VERSION "HINBNNNYYNNNYYNNNNNNNNNNNNYNNNYYYNNYNNNNNN/4//%%/4/'%**4NNN///"

NS_ :

BS_:

BU_: VirtualNMTMaster TTGateway_ID2 Master_ID1 SupportFront_ID12 LadderDrive_ID11 SupportRear_ID13 ControlPanel_ID10

BO_ 1537 CSDO_001: 8 Vector__XXX
 SG_ RequestNMT_1F82_5E m94 : 32|8@1+ (1,0) [0|255] ""  Master_ID1
 SG_ RequestNMT_1F82_5D m93 : 32|8@1+ (1,0) [0|255] ""  Master_ID1
 SG_ RequestNMT_1F82_5C m92 : 32|8@1+ (1,0) [0|255] ""  Master_ID1
 SG_ RequestNMT_1F82_5B m91 : 32|8@1+ (1,0) [0|255] ""  Master_ID1
 SG_ RequestNMT_1F82_5A m90 : 32|8@1+ (1,0) [0|255] ""  Master_ID1
 SG_ RequestNMT_1F82_59 m89 : 32|8@1+ (1,0) [0|255] ""  Master_ID1
 SG_ RequestNMT_1F82_58 m88 : 32|8@1+ (1,0) [0|255] ""  Master_ID1
 SG_ RequestNMT_1F82_57 m87 : 32|8@1+ (1,0) [0|255] ""  Master_ID1
 SG_ RequestNMT_1F82_56 m86 : 32|8@1+ (1,0) [0|255] ""  Master_ID1
 SG_ RequestNMT_1F82_55 m85 : 32|8@1+ (1,0) [0|255] ""  Master_ID1
 SG_ RequestNMT_1F82_54 m84 : 32|8@1+ (1,0) [0|255] ""  Master_ID1
 SG_ RequestNMT_1F82_53 m83 : 32|8@1+ (1,0) [0|255] ""  Master_ID1
 SG_ RequestNMT_1F82_52 m82 : 32|8@1+ (1,0) [0|255] ""  Master_ID1
 SG_ RequestNMT_1F82_51 m81 : 32|8@1+ (1,0) [0|255] ""  Master_ID1
 SG_ RequestNMT_1F82_50 m80 : 32|8@1+ (1,0) [0|255] ""  Master_ID1
 SG_ RequestNMT_1F82_4F m79 : 32|8@1+ (1,0) [0|255] ""  Master_ID1
 SG_ RequestNMT_1F82_4E m78 : 32|8@1+ (1,0) [0|255] ""  Master_ID1
 SG_ RequestNMT_1F82_4D m77 : 32|8@1+ (1,0) [0|255] ""  Master_ID1
 SG_ RequestNMT_1F82_4C m76 : 32|8@1+ (1,0) [0|255] ""  Master_ID1
 SG_ RequestNMT_1F82_4B m75 : 32|8@1+ (1,0) [0|255] ""  Master_ID1
 SG_ RequestNMT_1F82_4A m74 : 32|8@1+ (1,0) [0|255] ""  Master_ID1
 SG_ RequestNMT_1F82_49 m73 : 32|8@1+ (1,0) [0|255] ""  Master_ID1
 SG_ RequestNMT_1F82_48 m72 : 32|8@1+ (1,0) [0|255] ""  Master_ID1
 SG_ RequestNMT_1F82_47 m71 : 32|8@1+ (1,0) [0|255] ""  Master_ID1
 SG_ RequestNMT_1F82_46 m70 : 32|8@1+ (1,0) [0|255] ""  Master_ID1
 SG_ RequestNMT_1F82_45 m69 : 32|8@1+ (1,0) [0|255] ""  Master_ID1
 SG_ RequestNMT_1F82_44 m68 : 32|8@1+ (1,0) [0|255] ""  Master_ID1
 SG_ RequestNMT_1F82_43 m67 : 32|8@1+ (1,0) [0|255] ""  Master_ID1
 SG_ RequestNMT_1F82_42 m66 : 32|8@1+ (1,0) [0|255] ""  Master_ID1
 SG_ RequestNMT_1F82_41 m65 : 32|8@1+ (1,0) [0|255] ""  Master_ID1
 SG_ RequestNMT_1F82_40 m64 : 32|8@1+ (1,0) [0|255] ""  Master_ID1
 SG_ RequestNMT_1F82_3F m63 : 32|8@1+ (1,0) [0|255] ""  Master_ID1
 SG_ RequestNMT_1F82_3E m62 : 32|8@1+ (1,0) [0|255] ""  Master_ID1
 SG_ RequestNMT_1F82_3D m61 : 32|8@1+ (1,0) [0|255] ""  Master_ID1
 SG_ RequestNMT_1F82_3C m60 : 32|8@1+ (1,0) [0|255] ""  Master_ID1
 SG_ RequestNMT_1F82_3B m59 : 32|8@1+ (1,0) [0|255] ""  Master_ID1
 SG_ RequestNMT_1F82_3A m58 : 32|8@1+ (1,0) [0|255] ""  Master_ID1
 SG_ RequestNMT_1F82_39 m57 : 32|8@1+ (1,0) [0|255] ""  Master_ID1
 SG_ RequestNMT_1F82_38 m56 : 32|8@1+ (1,0) [0|255] ""  Master_ID1
 SG_ RequestNMT_1F82_37 m55 : 32|8@1+ (1,0) [0|255] ""  Master_ID1
 SG_ RequestNMT_1F82_36 m54 : 32|8@1+ (1,0) [0|255] ""  Master_ID1
 SG_ RequestNMT_1F82_35 m53 : 32|8@1+ (1,0) [0|255] ""  Master_ID1
 SG_ RequestNMT_1F82_34 m52 : 32|8@1+ (1,0) [0|255] ""  Master_ID1
 SG_ RequestNMT_1F82_33 m51 : 32|8@1+ (1,0) [0|255] ""  Master_ID1
 SG_ RequestNMT_1F82_32 m50 : 32|8@1+ (1,0) [0|255] ""  Master_ID1
 SG_ RequestNMT_1F82_31 m49 : 32|8@1+ (1,0) [0|255] ""  Master_ID1
 SG_ RequestNMT_1F82_30 m48 : 32|8@1+ (1,0) [0|255] ""  Master_ID1
 SG_ RequestNMT_1F82_2F m47 : 32|8@1+ (1,0) [0|255] ""  Master_ID1
 SG_ RequestNMT_1F82_2E m46 : 32|8@1+ (1,0) [0|255] ""  Master_ID1
 SG_ RequestNMT_1F82_2D m45 : 32|8@1+ (1,0) [0|255] ""  Master_ID1
 SG_ RequestNMT_1F82_2C m44 : 32|8@1+ (1,0) [0|255] ""  Master_ID1
 SG_ RequestNMT_1F82_2B m43 : 32|8@1+ (1,0) [0|255] ""  Master_ID1
 SG_ RequestNMT_1F82_2A m42 : 32|8@1+ (1,0) [0|255] ""  Master_ID1
 SG_ RequestNMT_1F82_29 m41 : 32|8@1+ (1,0) [0|255] ""  Master_ID1
 SG_ RequestNMT_1F82_28 m40 : 32|8@1+ (1,0) [0|255] ""  Master_ID1
 SG_ RequestNMT_1F82_27 m39 : 32|8@1+ (1,0) [0|255] ""  Master_ID1
 SG_ RequestNMT_1F82_26 m38 : 32|8@1+ (1,0) [0|255] ""  Master_ID1
 SG_ RequestNMT_1F82_25 m37 : 32|8@1+ (1,0) [0|255] ""  Master_ID1
 SG_ RequestNMT_1F82_24 m36 : 32|8@1+ (1,0) [0|255] ""  Master_ID1
 SG_ RequestNMT_1F82_23 m35 : 32|8@1+ (1,0) [0|255] ""  Master_ID1
 SG_ RequestNMT_1F82_22 m34 : 32|8@1+ (1,0) [0|255] ""  Master_ID1
 SG_ RequestNMT_1F82_21 m33 : 32|8@1+ (1,0) [0|255] ""  Master_ID1
 SG_ RequestNMT_1F82_20 m32 : 32|8@1+ (1,0) [0|255] ""  Master_ID1
 SG_ RequestNMT_1F82_1F m31 : 32|8@1+ (1,0) [0|255] ""  Master_ID1
 SG_ RequestNMT_1F82_1E m30 : 32|8@1+ (1,0) [0|255] ""  Master_ID1
 SG_ RequestNMT_1F82_1D m29 : 32|8@1+ (1,0) [0|255] ""  Master_ID1
 SG_ RequestNMT_1F82_1C m28 : 32|8@1+ (1,0) [0|255] ""  Master_ID1
 SG_ RequestNMT_1F82_1B m27 : 32|8@1+ (1,0) [0|255] ""  Master_ID1
 SG_ RequestNMT_1F82_1A m26 : 32|8@1+ (1,0) [0|255] ""  Master_ID1
 SG_ RequestNMT_1F82_19 m25 : 32|8@1+ (1,0) [0|255] ""  Master_ID1
 SG_ RequestNMT_1F82_18 m24 : 32|8@1+ (1,0) [0|255] ""  Master_ID1
 SG_ RequestNMT_1F82_17 m23 : 32|8@1+ (1,0) [0|255] ""  Master_ID1
 SG_ RequestNMT_1F82_16 m22 : 32|8@1+ (1,0) [0|255] ""  Master_ID1
 SG_ RequestNMT_1F82_15 m21 : 32|8@1+ (1,0) [0|255] ""  Master_ID1
 SG_ RequestNMT_1F82_14 m20 : 32|8@1+ (1,0) [0|255] ""  Master_ID1
 SG_ RequestNMT_1F82_13 m19 : 32|8@1+ (1,0) [0|255] ""  Master_ID1
 SG_ RequestNMT_1F82_12 m18 : 32|8@1+ (1,0) [0|255] ""  Master_ID1
 SG_ RequestNMT_1F82_11 m17 : 32|8@1+ (1,0) [0|255] ""  Master_ID1
 SG_ RequestNMT_1F82_10 m16 : 32|8@1+ (1,0) [0|255] ""  Master_ID1
 SG_ RequestNMT_1F82_0F m15 : 32|8@1+ (1,0) [0|255] ""  Master_ID1
 SG_ RequestNMT_1F82_0E m14 : 32|8@1+ (1,0) [0|255] ""  Master_ID1
 SG_ RequestNMT_1F82_0D m13 : 32|8@1+ (1,0) [0|255] ""  Master_ID1
 SG_ RequestNMT_1F82_0C m12 : 32|8@1+ (1,0) [0|255] ""  Master_ID1
 SG_ RequestNMT_1F82_0B m11 : 32|8@1+ (1,0) [0|255] ""  Master_ID1
 SG_ RequestNMT_1F82_0A m10 : 32|8@1+ (1,0) [0|255] ""  Master_ID1
 SG_ RequestNMT_1F82_09 m9 : 32|8@1+ (1,0) [0|255] ""  Master_ID1
 SG_ RequestNMT_1F82_08 m8 : 32|8@1+ (1,0) [0|255] ""  Master_ID1
 SG_ RequestNMT_1F82_07 m7 : 32|8@1+ (1,0) [0|255] ""  Master_ID1
 SG_ RequestNMT_1F82_06 m6 : 32|8@1+ (1,0) [0|255] ""  Master_ID1
 SG_ RequestNMT_1F82_05 m5 : 32|8@1+ (1,0) [0|255] ""  Master_ID1
 SG_ RequestNMT_1F82_04 m4 : 32|8@1+ (1,0) [0|255] ""  Master_ID1
 SG_ RequestNMT_1F82_03 m3 : 32|8@1+ (1,0) [0|255] ""  Master_ID1
 SG_ RequestNMT_1F82_02 m2 : 32|8@1+ (1,0) [0|255] ""  Master_ID1
 SG_ RequestNMT_1F82_01 m1 : 32|8@1+ (1,0) [0|255] ""  Master_ID1
 SG_ Highest_sub_index_supported_0013 m0 : 32|8@1+ (1,0) [0|255] ""  Master_ID1
 SG_ SubIndex_1F82 m8066M : 24|8@1+ (1,0) [0|128] ""  Master_ID1
 SG_ SlaveAssignment_1F81_7F m127 : 32|32@1+ (1,0) [0|4294967295] ""  Master_ID1
 SG_ SlaveAssignment_1F81_7E m126 : 32|32@1+ (1,0) [0|4294967295] ""  Master_ID1
 SG_ SlaveAssignment_1F81_7D m125 : 32|32@1+ (1,0) [0|4294967295] ""  Master_ID1
 SG_ SlaveAssignment_1F81_7C m124 : 32|32@1+ (1,0) [0|4294967295] ""  Master_ID1
 SG_ SlaveAssignment_1F81_7B m123 : 32|32@1+ (1,0) [0|4294967295] ""  Master_ID1
 SG_ SlaveAssignment_1F81_7A m122 : 32|32@1+ (1,0) [0|4294967295] ""  Master_ID1
 SG_ SlaveAssignment_1F81_79 m121 : 32|32@1+ (1,0) [0|4294967295] ""  Master_ID1
 SG_ SlaveAssignment_1F81_78 m120 : 32|32@1+ (1,0) [0|4294967295] ""  Master_ID1
 SG_ SlaveAssignment_1F81_77 m119 : 32|32@1+ (1,0) [0|4294967295] ""  Master_ID1
 SG_ SlaveAssignment_1F81_76 m118 : 32|32@1+ (1,0) [0|4294967295] ""  Master_ID1
 SG_ SlaveAssignment_1F81_75 m117 : 32|32@1+ (1,0) [0|4294967295] ""  Master_ID1
 SG_ SlaveAssignment_1F81_74 m116 : 32|32@1+ (1,0) [0|4294967295] ""  Master_ID1
 SG_ SlaveAssignment_1F81_73 m115 : 32|32@1+ (1,0) [0|4294967295] ""  Master_ID1
 SG_ SlaveAssignment_1F81_72 m114 : 32|32@1+ (1,0) [0|4294967295] ""  Master_ID1
 SG_ SlaveAssignment_1F81_71 m113 : 32|32@1+ (1,0) [0|4294967295] ""  Master_ID1
 SG_ SlaveAssignment_1F81_70 m112 : 32|32@1+ (1,0) [0|4294967295] ""  Master_ID1
 SG_ SlaveAssignment_1F81_6F m111 : 32|32@1+ (1,0) [0|4294967295] ""  Master_ID1
 SG_ SlaveAssignment_1F81_6E m110 : 32|32@1+ (1,0) [0|4294967295] ""  Master_ID1
 SG_ SlaveAssignment_1F81_6D m109 : 32|32@1+ (1,0) [0|4294967295] ""  Master_ID1
 SG_ SlaveAssignment_1F81_6C m108 : 32|32@1+ (1,0) [0|4294967295] ""  Master_ID1
 SG_ SlaveAssignment_1F81_6B m107 : 32|32@1+ (1,0) [0|4294967295] ""  Master_ID1
 SG_ SlaveAssignment_1F81_6A m106 : 32|32@1+ (1,0) [0|4294967295] ""  Master_ID1
 SG_ SlaveAssignment_1F81_69 m105 : 32|32@1+ (1,0) [0|4294967295] ""  Master_ID1
 SG_ SlaveAssignment_1F81_68 m104 : 32|32@1+ (1,0) [0|4294967295] ""  Master_ID1
 SG_ SlaveAssignment_1F81_67 m103 : 32|32@1+ (1,0) [0|4294967295] ""  Master_ID1
 SG_ SlaveAssignment_1F81_66 m102 : 32|32@1+ (1,0) [0|4294967295] ""  Master_ID1
 SG_ SlaveAssignment_1F81_65 m101 : 32|32@1+ (1,0) [0|4294967295] ""  Master_ID1
 SG_ SlaveAssignment_1F81_64 m100 : 32|32@1+ (1,0) [0|4294967295] ""  Master_ID1
 SG_ SlaveAssignment_1F81_63 m99 : 32|32@1+ (1,0) [0|4294967295] ""  Master_ID1
 SG_ SlaveAssignment_1F81_62 m98 : 32|32@1+ (1,0) [0|4294967295] ""  Master_ID1
 SG_ SlaveAssignment_1F81_61 m97 : 32|32@1+ (1,0) [0|4294967295] ""  Master_ID1
 SG_ SlaveAssignment_1F81_60 m96 : 32|32@1+ (1,0) [0|4294967295] ""  Master_ID1
 SG_ SlaveAssignment_1F81_5F m95 : 32|32@1+ (1,0) [0|4294967295] ""  Master_ID1
 SG_ SlaveAssignment_1F81_5E m94 : 32|32@1+ (1,0) [0|4294967295] ""  Master_ID1
 SG_ SlaveAssignment_1F81_5D m93 : 32|32@1+ (1,0) [0|4294967295] ""  Master_ID1
 SG_ SlaveAssignment_1F81_5C m92 : 32|32@1+ (1,0) [0|4294967295] ""  Master_ID1
 SG_ SlaveAssignment_1F81_5B m91 : 32|32@1+ (1,0) [0|4294967295] ""  Master_ID1
 SG_ SlaveAssignment_1F81_5A m90 : 32|32@1+ (1,0) [0|4294967295] ""  Master_ID1
 SG_ SlaveAssignment_1F81_59 m89 : 32|32@1+ (1,0) [0|4294967295] ""  Master_ID1
 SG_ SlaveAssignment_1F81_58 m88 : 32|32@1+ (1,0) [0|4294967295] ""  Master_ID1
 SG_ SlaveAssignment_1F81_57 m87 : 32|32@1+ (1,0) [0|4294967295] ""  Master_ID1
 SG_ SlaveAssignment_1F81_56 m86 : 32|32@1+ (1,0) [0|4294967295] ""  Master_ID1
 SG_ SlaveAssignment_1F81_55 m85 : 32|32@1+ (1,0) [0|4294967295] ""  Master_ID1
 SG_ SlaveAssignment_1F81_54 m84 : 32|32@1+ (1,0) [0|4294967295] ""  Master_ID1
 SG_ SlaveAssignment_1F81_53 m83 : 32|32@1+ (1,0) [0|4294967295] ""  Master_ID1
 SG_ SlaveAssignment_1F81_52 m82 : 32|32@1+ (1,0) [0|4294967295] ""  Master_ID1
 SG_ SlaveAssignment_1F81_51 m81 : 32|32@1+ (1,0) [0|4294967295] ""  Master_ID1
 SG_ SlaveAssignment_1F81_50 m80 : 32|32@1+ (1,0) [0|4294967295] ""  Master_ID1
 SG_ SlaveAssignment_1F81_4F m79 : 32|32@1+ (1,0) [0|4294967295] ""  Master_ID1
 SG_ SlaveAssignment_1F81_4E m78 : 32|32@1+ (1,0) [0|4294967295] ""  Master_ID1
 SG_ SlaveAssignment_1F81_4D m77 : 32|32@1+ (1,0) [0|4294967295] ""  Master_ID1
 SG_ SlaveAssignment_1F81_4C m76 : 32|32@1+ (1,0) [0|4294967295] ""  Master_ID1
 SG_ SlaveAssignment_1F81_4B m75 : 32|32@1+ (1,0) [0|4294967295] ""  Master_ID1
 SG_ SlaveAssignment_1F81_4A m74 : 32|32@1+ (1,0) [0|4294967295] ""  Master_ID1
 SG_ SlaveAssignment_1F81_49 m73 : 32|32@1+ (1,0) [0|4294967295] ""  Master_ID1
 SG_ SlaveAssignment_1F81_48 m72 : 32|32@1+ (1,0) [0|4294967295] ""  Master_ID1
 SG_ SlaveAssignment_1F81_47 m71 : 32|32@1+ (1,0) [0|4294967295] ""  Master_ID1
 SG_ SlaveAssignment_1F81_46 m70 : 32|32@1+ (1,0) [0|4294967295] ""  Master_ID1
 SG_ SlaveAssignment_1F81_45 m69 : 32|32@1+ (1,0) [0|4294967295] ""  Master_ID1
 SG_ SlaveAssignment_1F81_44 m68 : 32|32@1+ (1,0) [0|4294967295] ""  Master_ID1
 SG_ SlaveAssignment_1F81_43 m67 : 32|32@1+ (1,0) [0|4294967295] ""  Master_ID1
 SG_ SlaveAssignment_1F81_42 m66 : 32|32@1+ (1,0) [0|4294967295] ""  Master_ID1
 SG_ SlaveAssignment_1F81_41 m65 : 32|32@1+ (1,0) [0|4294967295] ""  Master_ID1
 SG_ SlaveAssignment_1F81_40 m64 : 32|32@1+ (1,0) [0|4294967295] ""  Master_ID1
 SG_ SlaveAssignment_1F81_3F m63 : 32|32@1+ (1,0) [0|4294967295] ""  Master_ID1
 SG_ SlaveAssignment_1F81_3E m62 : 32|32@1+ (1,0) [0|4294967295] ""  Master_ID1
 SG_ SlaveAssignment_1F81_3D m61 : 32|32@1+ (1,0) [0|4294967295] ""  Master_ID1
 SG_ SlaveAssignment_1F81_3C m60 : 32|32@1+ (1,0) [0|4294967295] ""  Master_ID1
 SG_ SlaveAssignment_1F81_3B m59 : 32|32@1+ (1,0) [0|4294967295] ""  Master_ID1
 SG_ SlaveAssignment_1F81_3A m58 : 32|32@1+ (1,0) [0|4294967295] ""  Master_ID1
 SG_ SlaveAssignment_1F81_39 m57 : 32|32@1+ (1,0) [0|4294967295] ""  Master_ID1
 SG_ SlaveAssignment_1F81_38 m56 : 32|32@1+ (1,0) [0|4294967295] ""  Master_ID1
 SG_ SlaveAssignment_1F81_37 m55 : 32|32@1+ (1,0) [0|4294967295] ""  Master_ID1
 SG_ SlaveAssignment_1F81_36 m54 : 32|32@1+ (1,0) [0|4294967295] ""  Master_ID1
 SG_ SlaveAssignment_1F81_35 m53 : 32|32@1+ (1,0) [0|4294967295] ""  Master_ID1
 SG_ SlaveAssignment_1F81_34 m52 : 32|32@1+ (1,0) [0|4294967295] ""  Master_ID1
 SG_ SlaveAssignment_1F81_33 m51 : 32|32@1+ (1,0) [0|4294967295] ""  Master_ID1
 SG_ SlaveAssignment_1F81_32 m50 : 32|32@1+ (1,0) [0|4294967295] ""  Master_ID1
 SG_ SlaveAssignment_1F81_31 m49 : 32|32@1+ (1,0) [0|4294967295] ""  Master_ID1
 SG_ SlaveAssignment_1F81_30 m48 : 32|32@1+ (1,0) [0|4294967295] ""  Master_ID1
 SG_ SlaveAssignment_1F81_2F m47 : 32|32@1+ (1,0) [0|4294967295] ""  Master_ID1
 SG_ SlaveAssignment_1F81_2E m46 : 32|32@1+ (1,0) [0|4294967295] ""  Master_ID1
 SG_ SlaveAssignment_1F81_2D m45 : 32|32@1+ (1,0) [0|4294967295] ""  Master_ID1
 SG_ SlaveAssignment_1F81_2C m44 : 32|32@1+ (1,0) [0|4294967295] ""  Master_ID1
 SG_ SlaveAssignment_1F81_2B m43 : 32|32@1+ (1,0) [0|4294967295] ""  Master_ID1
 SG_ SlaveAssignment_1F81_2A m42 : 32|32@1+ (1,0) [0|4294967295] ""  Master_ID1
 SG_ SlaveAssignment_1F81_29 m41 : 32|32@1+ (1,0) [0|4294967295] ""  Master_ID1
 SG_ SlaveAssignment_1F81_28 m40 : 32|32@1+ (1,0) [0|4294967295] ""  Master_ID1
 SG_ SlaveAssignment_1F81_27 m39 : 32|32@1+ (1,0) [0|4294967295] ""  Master_ID1
 SG_ SlaveAssignment_1F81_26 m38 : 32|32@1+ (1,0) [0|4294967295] ""  Master_ID1
 SG_ SlaveAssignment_1F81_25 m37 : 32|32@1+ (1,0) [0|4294967295] ""  Master_ID1
 SG_ SlaveAssignment_1F81_24 m36 : 32|32@1+ (1,0) [0|4294967295] ""  Master_ID1
 SG_ SlaveAssignment_1F81_23 m35 : 32|32@1+ (1,0) [0|4294967295] ""  Master_ID1
 SG_ SlaveAssignment_1F81_22 m34 : 32|32@1+ (1,0) [0|4294967295] ""  Master_ID1
 SG_ SlaveAssignment_1F81_21 m33 : 32|32@1+ (1,0) [0|4294967295] ""  Master_ID1
 SG_ SlaveAssignment_1F81_20 m32 : 32|32@1+ (1,0) [0|4294967295] ""  Master_ID1
 SG_ SlaveAssignment_1F81_1F m31 : 32|32@1+ (1,0) [0|4294967295] ""  Master_ID1
 SG_ SlaveAssignment_1F81_1E m30 : 32|32@1+ (1,0) [0|4294967295] ""  Master_ID1
 SG_ SlaveAssignment_1F81_1D m29 : 32|32@1+ (1,0) [0|4294967295] ""  Master_ID1
 SG_ SlaveAssignment_1F81_1C m28 : 32|32@1+ (1,0) [0|4294967295] ""  Master_ID1
 SG_ SlaveAssignment_1F81_1B m27 : 32|32@1+ (1,0) [0|4294967295] ""  Master_ID1
 SG_ SlaveAssignment_1F81_1A m26 : 32|32@1+ (1,0) [0|4294967295] ""  Master_ID1
 SG_ SlaveAssignment_1F81_19 m25 : 32|32@1+ (1,0) [0|4294967295] ""  Master_ID1
 SG_ SlaveAssignment_1F81_18 m24 : 32|32@1+ (1,0) [0|4294967295] ""  Master_ID1
 SG_ SlaveAssignment_1F81_17 m23 : 32|32@1+ (1,0) [0|4294967295] ""  Master_ID1
 SG_ SlaveAssignment_1F81_16 m22 : 32|32@1+ (1,0) [0|4294967295] ""  Master_ID1
 SG_ SlaveAssignment_1F81_15 m21 : 32|32@1+ (1,0) [0|4294967295] ""  Master_ID1
 SG_ SlaveAssignment_1F81_14 m20 : 32|32@1+ (1,0) [0|4294967295] ""  Master_ID1
 SG_ SlaveAssignment_1F81_13 m19 : 32|32@1+ (1,0) [0|4294967295] ""  Master_ID1
 SG_ SlaveAssignment_1F81_12 m18 : 32|32@1+ (1,0) [0|4294967295] ""  Master_ID1
 SG_ SlaveAssignment_1F81_11 m17 : 32|32@1+ (1,0) [0|4294967295] ""  Master_ID1
 SG_ SlaveAssignment_1F81_10 m16 : 32|32@1+ (1,0) [0|4294967295] ""  Master_ID1
 SG_ SlaveAssignment_1F81_0F m15 : 32|32@1+ (1,0) [0|4294967295] ""  Master_ID1
 SG_ SlaveAssignment_1F81_0E m14 : 32|32@1+ (1,0) [0|4294967295] ""  Master_ID1
 SG_ SlaveAssignment_1F81_0D m13 : 32|32@1+ (1,0) [0|4294967295] ""  Master_ID1
 SG_ SlaveAssignment_1F81_0C m12 : 32|32@1+ (1,0) [0|4294967295] ""  Master_ID1
 SG_ SlaveAssignment_1F81_0B m11 : 32|32@1+ (1,0) [0|4294967295] ""  Master_ID1
 SG_ SlaveAssignment_1F81_0A m10 : 32|32@1+ (1,0) [0|4294967295] ""  Master_ID1
 SG_ SlaveAssignment_1F81_09 m9 : 32|32@1+ (1,0) [0|4294967295] ""  Master_ID1
 SG_ SlaveAssignment_1F81_08 m8 : 32|32@1+ (1,0) [0|4294967295] ""  Master_ID1
 SG_ SlaveAssignment_1F81_07 m7 : 32|32@1+ (1,0) [0|4294967295] ""  Master_ID1
 SG_ SlaveAssignment_1F81_06 m6 : 32|32@1+ (1,0) [0|4294967295] ""  Master_ID1
 SG_ SlaveAssignment_1F81_05 m5 : 32|32@1+ (1,0) [0|4294967295] ""  Master_ID1
 SG_ SlaveAssignment_1F81_04 m4 : 32|32@1+ (1,0) [0|4294967295] ""  Master_ID1
 SG_ SlaveAssignment_1F81_03 m3 : 32|32@1+ (1,0) [0|4294967295] ""  Master_ID1
 SG_ SlaveAssignment_1F81_02 m2 : 32|32@1+ (1,0) [0|4294967295] ""  Master_ID1
 SG_ SlaveAssignment_1F81_01 m1 : 32|32@1+ (1,0) [0|4294967295] ""  Master_ID1
 SG_ NrOfObjects_1F81_00 m0 : 32|8@1+ (1,0) [0|255] ""  Master_ID1
 SG_ SubIndex_1F81 m8065M : 24|8@1+ (1,0) [0|127] ""  Master_ID1
 SG_ NMTStartup_1F80 m0 : 32|32@1+ (1,0) [0|4294967295] ""  Master_ID1
 SG_ SubIndex_1F80 m8064M : 24|8@1+ (1,0) [0|0] ""  Master_ID1
 SG_ Configure_Slave_1F25_80 m128 : 32|32@1+ (1,0) [0|4294967295] ""  Master_ID1
 SG_ Configure_Slave_1F25_7F m127 : 32|32@1+ (1,0) [0|4294967295] ""  Master_ID1
 SG_ Configure_Slave_1F25_7E m126 : 32|32@1+ (1,0) [0|4294967295] ""  Master_ID1
 SG_ Configure_Slave_1F25_7D m125 : 32|32@1+ (1,0) [0|4294967295] ""  Master_ID1
 SG_ Configure_Slave_1F25_7C m124 : 32|32@1+ (1,0) [0|4294967295] ""  Master_ID1
 SG_ Configure_Slave_1F25_7B m123 : 32|32@1+ (1,0) [0|4294967295] ""  Master_ID1
 SG_ Configure_Slave_1F25_7A m122 : 32|32@1+ (1,0) [0|4294967295] ""  Master_ID1
 SG_ Configure_Slave_1F25_79 m121 : 32|32@1+ (1,0) [0|4294967295] ""  Master_ID1
 SG_ Configure_Slave_1F25_78 m120 : 32|32@1+ (1,0) [0|4294967295] ""  Master_ID1
 SG_ Configure_Slave_1F25_77 m119 : 32|32@1+ (1,0) [0|4294967295] ""  Master_ID1
 SG_ Configure_Slave_1F25_76 m118 : 32|32@1+ (1,0) [0|4294967295] ""  Master_ID1
 SG_ Configure_Slave_1F25_75 m117 : 32|32@1+ (1,0) [0|4294967295] ""  Master_ID1
 SG_ Configure_Slave_1F25_74 m116 : 32|32@1+ (1,0) [0|4294967295] ""  Master_ID1
 SG_ Configure_Slave_1F25_73 m115 : 32|32@1+ (1,0) [0|4294967295] ""  Master_ID1
 SG_ Configure_Slave_1F25_72 m114 : 32|32@1+ (1,0) [0|4294967295] ""  Master_ID1
 SG_ Configure_Slave_1F25_71 m113 : 32|32@1+ (1,0) [0|4294967295] ""  Master_ID1
 SG_ Configure_Slave_1F25_70 m112 : 32|32@1+ (1,0) [0|4294967295] ""  Master_ID1
 SG_ Configure_Slave_1F25_6F m111 : 32|32@1+ (1,0) [0|4294967295] ""  Master_ID1
 SG_ Configure_Slave_1F25_6E m110 : 32|32@1+ (1,0) [0|4294967295] ""  Master_ID1
 SG_ Configure_Slave_1F25_6D m109 : 32|32@1+ (1,0) [0|4294967295] ""  Master_ID1
 SG_ Configure_Slave_1F25_6C m108 : 32|32@1+ (1,0) [0|4294967295] ""  Master_ID1
 SG_ Configure_Slave_1F25_6B m107 : 32|32@1+ (1,0) [0|4294967295] ""  Master_ID1
 SG_ Configure_Slave_1F25_6A m106 : 32|32@1+ (1,0) [0|4294967295] ""  Master_ID1
 SG_ Configure_Slave_1F25_69 m105 : 32|32@1+ (1,0) [0|4294967295] ""  Master_ID1
 SG_ Configure_Slave_1F25_68 m104 : 32|32@1+ (1,0) [0|4294967295] ""  Master_ID1
 SG_ Configure_Slave_1F25_67 m103 : 32|32@1+ (1,0) [0|4294967295] ""  Master_ID1
 SG_ Configure_Slave_1F25_66 m102 : 32|32@1+ (1,0) [0|4294967295] ""  Master_ID1
 SG_ Configure_Slave_1F25_65 m101 : 32|32@1+ (1,0) [0|4294967295] ""  Master_ID1
 SG_ Configure_Slave_1F25_64 m100 : 32|32@1+ (1,0) [0|4294967295] ""  Master_ID1
 SG_ Configure_Slave_1F25_63 m99 : 32|32@1+ (1,0) [0|4294967295] ""  Master_ID1
 SG_ Configure_Slave_1F25_62 m98 : 32|32@1+ (1,0) [0|4294967295] ""  Master_ID1
 SG_ Configure_Slave_1F25_61 m97 : 32|32@1+ (1,0) [0|4294967295] ""  Master_ID1
 SG_ Configure_Slave_1F25_60 m96 : 32|32@1+ (1,0) [0|4294967295] ""  Master_ID1
 SG_ Configure_Slave_1F25_5F m95 : 32|32@1+ (1,0) [0|4294967295] ""  Master_ID1
 SG_ Configure_Slave_1F25_5E m94 : 32|32@1+ (1,0) [0|4294967295] ""  Master_ID1
 SG_ Configure_Slave_1F25_5D m93 : 32|32@1+ (1,0) [0|4294967295] ""  Master_ID1
 SG_ Configure_Slave_1F25_5C m92 : 32|32@1+ (1,0) [0|4294967295] ""  Master_ID1
 SG_ Configure_Slave_1F25_5B m91 : 32|32@1+ (1,0) [0|4294967295] ""  Master_ID1
 SG_ Configure_Slave_1F25_5A m90 : 32|32@1+ (1,0) [0|4294967295] ""  Master_ID1
 SG_ Configure_Slave_1F25_59 m89 : 32|32@1+ (1,0) [0|4294967295] ""  Master_ID1
 SG_ Configure_Slave_1F25_58 m88 : 32|32@1+ (1,0) [0|4294967295] ""  Master_ID1
 SG_ Configure_Slave_1F25_57 m87 : 32|32@1+ (1,0) [0|4294967295] ""  Master_ID1
 SG_ Configure_Slave_1F25_56 m86 : 32|32@1+ (1,0) [0|4294967295] ""  Master_ID1
 SG_ Configure_Slave_1F25_55 m85 : 32|32@1+ (1,0) [0|4294967295] ""  Master_ID1
 SG_ Configure_Slave_1F25_54 m84 : 32|32@1+ (1,0) [0|4294967295] ""  Master_ID1
 SG_ Configure_Slave_1F25_53 m83 : 32|32@1+ (1,0) [0|4294967295] ""  Master_ID1
 SG_ Configure_Slave_1F25_52 m82 : 32|32@1+ (1,0) [0|4294967295] ""  Master_ID1
 SG_ Configure_Slave_1F25_51 m81 : 32|32@1+ (1,0) [0|4294967295] ""  Master_ID1
 SG_ Configure_Slave_1F25_50 m80 : 32|32@1+ (1,0) [0|4294967295] ""  Master_ID1
 SG_ Configure_Slave_1F25_4F m79 : 32|32@1+ (1,0) [0|4294967295] ""  Master_ID1
 SG_ Configure_Slave_1F25_4E m78 : 32|32@1+ (1,0) [0|4294967295] ""  Master_ID1
 SG_ Configure_Slave_1F25_4D m77 : 32|32@1+ (1,0) [0|4294967295] ""  Master_ID1
 SG_ Configure_Slave_1F25_4C m76 : 32|32@1+ (1,0) [0|4294967295] ""  Master_ID1
 SG_ Configure_Slave_1F25_4B m75 : 32|32@1+ (1,0) [0|4294967295] ""  Master_ID1
 SG_ Configure_Slave_1F25_4A m74 : 32|32@1+ (1,0) [0|4294967295] ""  Master_ID1
 SG_ Configure_Slave_1F25_49 m73 : 32|32@1+ (1,0) [0|4294967295] ""  Master_ID1
 SG_ Configure_Slave_1F25_48 m72 : 32|32@1+ (1,0) [0|4294967295] ""  Master_ID1
 SG_ Configure_Slave_1F25_47 m71 : 32|32@1+ (1,0) [0|4294967295] ""  Master_ID1
 SG_ Configure_Slave_1F25_46 m70 : 32|32@1+ (1,0) [0|4294967295] ""  Master_ID1
 SG_ Configure_Slave_1F25_45 m69 : 32|32@1+ (1,0) [0|4294967295] ""  Master_ID1
 SG_ Configure_Slave_1F25_44 m68 : 32|32@1+ (1,0) [0|4294967295] ""  Master_ID1
 SG_ Configure_Slave_1F25_43 m67 : 32|32@1+ (1,0) [0|4294967295] ""  Master_ID1
 SG_ Configure_Slave_1F25_42 m66 : 32|32@1+ (1,0) [0|4294967295] ""  Master_ID1
 SG_ Configure_Slave_1F25_41 m65 : 32|32@1+ (1,0) [0|4294967295] ""  Master_ID1
 SG_ Configure_Slave_1F25_40 m64 : 32|32@1+ (1,0) [0|4294967295] ""  Master_ID1
 SG_ Configure_Slave_1F25_3F m63 : 32|32@1+ (1,0) [0|4294967295] ""  Master_ID1
 SG_ Configure_Slave_1F25_3E m62 : 32|32@1+ (1,0) [0|4294967295] ""  Master_ID1
 SG_ Configure_Slave_1F25_3D m61 : 32|32@1+ (1,0) [0|4294967295] ""  Master_ID1
 SG_ Configure_Slave_1F25_3C m60 : 32|32@1+ (1,0) [0|4294967295] ""  Master_ID1
 SG_ Configure_Slave_1F25_3B m59 : 32|32@1+ (1,0) [0|4294967295] ""  Master_ID1
 SG_ Configure_Slave_1F25_3A m58 : 32|32@1+ (1,0) [0|4294967295] ""  Master_ID1
 SG_ Configure_Slave_1F25_39 m57 : 32|32@1+ (1,0) [0|4294967295] ""  Master_ID1
 SG_ Configure_Slave_1F25_38 m56 : 32|32@1+ (1,0) [0|4294967295] ""  Master_ID1
 SG_ Configure_Slave_1F25_37 m55 : 32|32@1+ (1,0) [0|4294967295] ""  Master_ID1
 SG_ Configure_Slave_1F25_36 m54 : 32|32@1+ (1,0) [0|4294967295] ""  Master_ID1
 SG_ Configure_Slave_1F25_35 m53 : 32|32@1+ (1,0) [0|4294967295] ""  Master_ID1
 SG_ Configure_Slave_1F25_34 m52 : 32|32@1+ (1,0) [0|4294967295] ""  Master_ID1
 SG_ Configure_Slave_1F25_33 m51 : 32|32@1+ (1,0) [0|4294967295] ""  Master_ID1
 SG_ Configure_Slave_1F25_32 m50 : 32|32@1+ (1,0) [0|4294967295] ""  Master_ID1
 SG_ Configure_Slave_1F25_31 m49 : 32|32@1+ (1,0) [0|4294967295] ""  Master_ID1
 SG_ Configure_Slave_1F25_30 m48 : 32|32@1+ (1,0) [0|4294967295] ""  Master_ID1
 SG_ Configure_Slave_1F25_2F m47 : 32|32@1+ (1,0) [0|4294967295] ""  Master_ID1
 SG_ Configure_Slave_1F25_2E m46 : 32|32@1+ (1,0) [0|4294967295] ""  Master_ID1
 SG_ Configure_Slave_1F25_2D m45 : 32|32@1+ (1,0) [0|4294967295] ""  Master_ID1
 SG_ Configure_Slave_1F25_2C m44 : 32|32@1+ (1,0) [0|4294967295] ""  Master_ID1
 SG_ Configure_Slave_1F25_2B m43 : 32|32@1+ (1,0) [0|4294967295] ""  Master_ID1
 SG_ Configure_Slave_1F25_2A m42 : 32|32@1+ (1,0) [0|4294967295] ""  Master_ID1
 SG_ Configure_Slave_1F25_29 m41 : 32|32@1+ (1,0) [0|4294967295] ""  Master_ID1
 SG_ Configure_Slave_1F25_28 m40 : 32|32@1+ (1,0) [0|4294967295] ""  Master_ID1
 SG_ Configure_Slave_1F25_27 m39 : 32|32@1+ (1,0) [0|4294967295] ""  Master_ID1
 SG_ Configure_Slave_1F25_26 m38 : 32|32@1+ (1,0) [0|4294967295] ""  Master_ID1
 SG_ Configure_Slave_1F25_25 m37 : 32|32@1+ (1,0) [0|4294967295] ""  Master_ID1
 SG_ Configure_Slave_1F25_24 m36 : 32|32@1+ (1,0) [0|4294967295] ""  Master_ID1
 SG_ Configure_Slave_1F25_23 m35 : 32|32@1+ (1,0) [0|4294967295] ""  Master_ID1
 SG_ Configure_Slave_1F25_22 m34 : 32|32@1+ (1,0) [0|4294967295] ""  Master_ID1
 SG_ Configure_Slave_1F25_21 m33 : 32|32@1+ (1,0) [0|4294967295] ""  Master_ID1
 SG_ Configure_Slave_1F25_20 m32 : 32|32@1+ (1,0) [0|4294967295] ""  Master_ID1
 SG_ Configure_Slave_1F25_1F m31 : 32|32@1+ (1,0) [0|4294967295] ""  Master_ID1
 SG_ Configure_Slave_1F25_1E m30 : 32|32@1+ (1,0) [0|4294967295] ""  Master_ID1
 SG_ Configure_Slave_1F25_1D m29 : 32|32@1+ (1,0) [0|4294967295] ""  Master_ID1
 SG_ Configure_Slave_1F25_1C m28 : 32|32@1+ (1,0) [0|4294967295] ""  Master_ID1
 SG_ Configure_Slave_1F25_1B m27 : 32|32@1+ (1,0) [0|4294967295] ""  Master_ID1
 SG_ Configure_Slave_1F25_1A m26 : 32|32@1+ (1,0) [0|4294967295] ""  Master_ID1
 SG_ Configure_Slave_1F25_19 m25 : 32|32@1+ (1,0) [0|4294967295] ""  Master_ID1
 SG_ Configure_Slave_1F25_18 m24 : 32|32@1+ (1,0) [0|4294967295] ""  Master_ID1
 SG_ Configure_Slave_1F25_17 m23 : 32|32@1+ (1,0) [0|4294967295] ""  Master_ID1
 SG_ Configure_Slave_1F25_16 m22 : 32|32@1+ (1,0) [0|4294967295] ""  Master_ID1
 SG_ Configure_Slave_1F25_15 m21 : 32|32@1+ (1,0) [0|4294967295] ""  Master_ID1
 SG_ Configure_Slave_1F25_14 m20 : 32|32@1+ (1,0) [0|4294967295] ""  Master_ID1
 SG_ Configure_Slave_1F25_13 m19 : 32|32@1+ (1,0) [0|4294967295] ""  Master_ID1
 SG_ Configure_Slave_1F25_12 m18 : 32|32@1+ (1,0) [0|4294967295] ""  Master_ID1
 SG_ Configure_Slave_1F25_11 m17 : 32|32@1+ (1,0) [0|4294967295] ""  Master_ID1
 SG_ Configure_Slave_1F25_10 m16 : 32|32@1+ (1,0) [0|4294967295] ""  Master_ID1
 SG_ Configure_Slave_1F25_0F m15 : 32|32@1+ (1,0) [0|4294967295] ""  Master_ID1
 SG_ Configure_Slave_1F25_0E m14 : 32|32@1+ (1,0) [0|4294967295] ""  Master_ID1
 SG_ Configure_Slave_1F25_0D m13 : 32|32@1+ (1,0) [0|4294967295] ""  Master_ID1
 SG_ Configure_Slave_1F25_0C m12 : 32|32@1+ (1,0) [0|4294967295] ""  Master_ID1
 SG_ Configure_Slave_1F25_0B m11 : 32|32@1+ (1,0) [0|4294967295] ""  Master_ID1
 SG_ Configure_Slave_1F25_0A m10 : 32|32@1+ (1,0) [0|4294967295] ""  Master_ID1
 SG_ Configure_Slave_1F25_09 m9 : 32|32@1+ (1,0) [0|4294967295] ""  Master_ID1
 SG_ Configure_Slave_1F25_08 m8 : 32|32@1+ (1,0) [0|4294967295] ""  Master_ID1
 SG_ Configure_Slave_1F25_07 m7 : 32|32@1+ (1,0) [0|4294967295] ""  Master_ID1
 SG_ Configure_Slave_1F25_06 m6 : 32|32@1+ (1,0) [0|4294967295] ""  Master_ID1
 SG_ Configure_Slave_1F25_05 m5 : 32|32@1+ (1,0) [0|4294967295] ""  Master_ID1
 SG_ Configure_Slave_1F25_04 m4 : 32|32@1+ (1,0) [0|4294967295] ""  Master_ID1
 SG_ Configure_Slave_1F25_03 m3 : 32|32@1+ (1,0) [0|4294967295] ""  Master_ID1
 SG_ Configure_Slave_1F25_02 m2 : 32|32@1+ (1,0) [0|4294967295] ""  Master_ID1
 SG_ Configure_Network_1F25_01 m1 : 32|32@1+ (1,0) [0|4294967295] ""  Master_ID1
 SG_ NrOfObjects_1F25_00 m0 : 32|8@1+ (1,0) [0|255] ""  Master_ID1
 SG_ SubIndex_1F25 m7973M : 24|8@1+ (1,0) [0|128] ""  Master_ID1
 SG_ NrOfObjects_1F22_00 m0 : 32|8@1+ (1,0) [0|255] ""  Master_ID1
 SG_ SubIndex_1F22 m7970M : 24|8@1+ (1,0) [0|127] ""  Master_ID1
 SG_ GENERATED_1A04_03 m3 : 32|32@1+ (1,0) [0|4294967295] ""  Master_ID1
 SG_ GENERATED_1A04_02 m2 : 32|32@1+ (1,0) [0|4294967295] ""  Master_ID1
 SG_ GENERATED_1A04_01 m1 : 32|32@1+ (1,0) [0|4294967295] ""  Master_ID1
 SG_ NrOfMappedObjects_1A04_00 m0 : 32|8@1+ (1,0) [0|8] ""  Master_ID1
 SG_ SubIndex_1A04 m6660M : 24|8@1+ (1,0) [0|3] ""  Master_ID1
 SG_ GENERATED_1A03_03 m3 : 32|32@1+ (1,0) [0|4294967295] ""  Master_ID1
 SG_ mappedObj2_1A03_02 m2 : 32|32@1+ (1,0) [0|4294967295] ""  Master_ID1
 SG_ mappedObj1_1A03_01 m1 : 32|32@1+ (1,0) [0|4294967295] ""  Master_ID1
 SG_ NrOfMappedObjects_1A03_00 m0 : 32|8@1+ (1,0) [0|8] ""  Master_ID1
 SG_ SubIndex_1A03 m6659M : 24|8@1+ (1,0) [0|3] ""  Master_ID1
 SG_ mappedObj2_1A02_02 m2 : 32|32@1+ (1,0) [0|4294967295] ""  Master_ID1
 SG_ mappedObj1_1A02_01 m1 : 32|32@1+ (1,0) [0|4294967295] ""  Master_ID1
 SG_ NrOfMappedObjects_1A02_00 m0 : 32|8@1+ (1,0) [0|8] ""  Master_ID1
 SG_ SubIndex_1A02 m6658M : 24|8@1+ (1,0) [0|2] ""  Master_ID1
 SG_ mappedObj2_1A01_02 m2 : 32|32@1+ (1,0) [0|4294967295] ""  Master_ID1
 SG_ mappedObj1_1A01_01 m1 : 32|32@1+ (1,0) [0|4294967295] ""  Master_ID1
 SG_ NrOfMappedObjects_1A01_00 m0 : 32|8@1+ (1,0) [0|8] ""  Master_ID1
 SG_ SubIndex_1A01 m6657M : 24|8@1+ (1,0) [0|2] ""  Master_ID1
 SG_ mappedObj2_1A00_02 m2 : 32|32@1+ (1,0) [0|4294967295] ""  Master_ID1
 SG_ mappedObj1_1A00_01 m1 : 32|32@1+ (1,0) [0|4294967295] ""  Master_ID1
 SG_ NrOfMappedObjects_1A00_00 m0 : 32|8@1+ (1,0) [0|8] ""  Master_ID1
 SG_ SubIndex_1A00 m6656M : 24|8@1+ (1,0) [0|2] ""  Master_ID1
 SG_ EventTimer_1804_05 m5 : 32|16@1+ (1,0) [0|65535] ""  Master_ID1
 SG_ TransmissionType_1804_02 m2 : 32|8@1+ (1,0) [0|255] ""  Master_ID1
 SG_ COB_ID_1804_01 m1 : 32|32@1+ (1,0) [128|4294967295] ""  Master_ID1
 SG_ Highest_sub_index_supported_0014 m0 : 32|8@1+ (1,0) [2|5] ""  Master_ID1
 SG_ SubIndex_1804 m6148M : 24|8@1+ (1,0) [0|5] ""  Master_ID1
 SG_ EventTimer_1803_05 m5 : 32|16@1+ (1,0) [0|65535] ""  Master_ID1
 SG_ TransmissionType_1803_02 m2 : 32|8@1+ (1,0) [0|255] ""  Master_ID1
 SG_ COB_ID_1803_01 m1 : 32|32@1+ (1,0) [128|4294967295] ""  Master_ID1
 SG_ Highest_sub_index_supported_0015 m0 : 32|8@1+ (1,0) [2|5] ""  Master_ID1
 SG_ SubIndex_1803 m6147M : 24|8@1+ (1,0) [0|5] ""  Master_ID1
 SG_ EventTimer_1802_05 m5 : 32|16@1+ (1,0) [0|65535] ""  Master_ID1
 SG_ TransmissionType_1802_02 m2 : 32|8@1+ (1,0) [0|255] ""  Master_ID1
 SG_ COB_ID_1802_01 m1 : 32|32@1+ (1,0) [128|4294967295] ""  Master_ID1
 SG_ Highest_sub_index_supported_0016 m0 : 32|8@1+ (1,0) [2|5] ""  Master_ID1
 SG_ SubIndex_1802 m6146M : 24|8@1+ (1,0) [0|5] ""  Master_ID1
 SG_ EventTimer_1801_05 m5 : 32|16@1+ (1,0) [0|65535] ""  Master_ID1
 SG_ TransmissionType_1801_02 m2 : 32|8@1+ (1,0) [0|255] ""  Master_ID1
 SG_ COB_ID_1801_01 m1 : 32|32@1+ (1,0) [128|4294967295] ""  Master_ID1
 SG_ Highest_sub_index_supported_0017 m0 : 32|8@1+ (1,0) [2|5] ""  Master_ID1
 SG_ SubIndex_1801 m6145M : 24|8@1+ (1,0) [0|5] ""  Master_ID1
 SG_ EventTimer_1800_05 m5 : 32|16@1+ (1,0) [0|65535] ""  Master_ID1
 SG_ TransmissionType_1800_02 m2 : 32|8@1+ (1,0) [0|255] ""  Master_ID1
 SG_ COB_ID_1800_01 m1 : 32|32@1+ (1,0) [128|4294967295] ""  Master_ID1
 SG_ Highest_sub_index_supported_0018 m0 : 32|8@1+ (1,0) [2|5] ""  Master_ID1
 SG_ SubIndex_1800 m6144M : 24|8@1+ (1,0) [0|5] ""  Master_ID1
 SG_ GENERATED_1604_05 m5 : 32|32@1+ (1,0) [0|4294967295] ""  Master_ID1
 SG_ GENERATED_1604_04 m4 : 32|32@1+ (1,0) [0|4294967295] ""  Master_ID1
 SG_ GENERATED_1604_03 m3 : 32|32@1+ (1,0) [0|4294967295] ""  Master_ID1
 SG_ GENERATED_1604_02 m2 : 32|32@1+ (1,0) [0|4294967295] ""  Master_ID1
 SG_ GENERATED_1604_01 m1 : 32|32@1+ (1,0) [0|4294967295] ""  Master_ID1
 SG_ NrOfMappedObjects_1604_00 m0 : 32|8@1+ (1,0) [0|8] ""  Master_ID1
 SG_ SubIndex_1604 m5636M : 24|8@1+ (1,0) [0|5] ""  Master_ID1
 SG_ mappedObj2_1603_02 m2 : 32|32@1+ (1,0) [0|4294967295] ""  Master_ID1
 SG_ mappedObj1_1603_01 m1 : 32|32@1+ (1,0) [0|4294967295] ""  Master_ID1
 SG_ NrOfMappedObjects_1603_00 m0 : 32|8@1+ (1,0) [0|8] ""  Master_ID1
 SG_ SubIndex_1603 m5635M : 24|8@1+ (1,0) [0|2] ""  Master_ID1
 SG_ mappedObj2_1602_02 m2 : 32|32@1+ (1,0) [0|4294967295] ""  Master_ID1
 SG_ mappedObj1_1602_01 m1 : 32|32@1+ (1,0) [0|4294967295] ""  Master_ID1
 SG_ NrOfMappedObjects_1602_00 m0 : 32|8@1+ (1,0) [0|8] ""  Master_ID1
 SG_ SubIndex_1602 m5634M : 24|8@1+ (1,0) [0|2] ""  Master_ID1
 SG_ GENERATED_1601_03 m3 : 32|32@1+ (1,0) [0|4294967295] ""  Master_ID1
 SG_ mappedObj2_1601_02 m2 : 32|32@1+ (1,0) [0|4294967295] ""  Master_ID1
 SG_ mappedObj1_1601_01 m1 : 32|32@1+ (1,0) [0|4294967295] ""  Master_ID1
 SG_ NrOfMappedObjects_1601_00 m0 : 32|8@1+ (1,0) [0|8] ""  Master_ID1
 SG_ SubIndex_1601 m5633M : 24|8@1+ (1,0) [0|3] ""  Master_ID1
 SG_ GENERATED_1600_05 m5 : 32|32@1+ (1,0) [0|4294967295] ""  Master_ID1
 SG_ mappedObj4_1600_04 m4 : 32|32@1+ (1,0) [0|4294967295] ""  Master_ID1
 SG_ mappedObj3_1600_03 m3 : 32|32@1+ (1,0) [0|4294967295] ""  Master_ID1
 SG_ mappedObj2_1600_02 m2 : 32|32@1+ (1,0) [0|4294967295] ""  Master_ID1
 SG_ mappedObj1_1600_01 m1 : 32|32@1+ (1,0) [0|4294967295] ""  Master_ID1
 SG_ NrOfMappedObjects_1600_00 m0 : 32|8@1+ (1,0) [0|8] ""  Master_ID1
 SG_ SubIndex_1600 m5632M : 24|8@1+ (1,0) [0|5] ""  Master_ID1
 SG_ TransmissionType_1404_02 m2 : 32|8@1+ (1,0) [0|255] ""  Master_ID1
 SG_ COB_ID_1404_01 m1 : 32|32@1+ (1,0) [128|4294967295] ""  Master_ID1
 SG_ Highest_sub_index_supported_0019 m0 : 32|8@1+ (1,0) [2|5] ""  Master_ID1
 SG_ SubIndex_1404 m5124M : 24|8@1+ (1,0) [0|2] ""  Master_ID1
 SG_ TransmissionType_1403_02 m2 : 32|8@1+ (1,0) [0|255] ""  Master_ID1
 SG_ COB_ID_1403_01 m1 : 32|32@1+ (1,0) [128|4294967295] ""  Master_ID1
 SG_ Highest_sub_index_supported_0020 m0 : 32|8@1+ (1,0) [2|5] ""  Master_ID1
 SG_ SubIndex_1403 m5123M : 24|8@1+ (1,0) [0|2] ""  Master_ID1
 SG_ TransmissionType_1402_02 m2 : 32|8@1+ (1,0) [0|255] ""  Master_ID1
 SG_ COB_ID_1402_01 m1 : 32|32@1+ (1,0) [128|4294967295] ""  Master_ID1
 SG_ Highest_sub_index_supported_0021 m0 : 32|8@1+ (1,0) [2|5] ""  Master_ID1
 SG_ SubIndex_1402 m5122M : 24|8@1+ (1,0) [0|2] ""  Master_ID1
 SG_ TransmissionType_1401_02 m2 : 32|8@1+ (1,0) [0|255] ""  Master_ID1
 SG_ COB_ID_1401_01 m1 : 32|32@1+ (1,0) [128|4294967295] ""  Master_ID1
 SG_ Highest_sub_index_supported_0022 m0 : 32|8@1+ (1,0) [2|5] ""  Master_ID1
 SG_ SubIndex_1401 m5121M : 24|8@1+ (1,0) [0|2] ""  Master_ID1
 SG_ TransmissionType_1400_02 m2 : 32|8@1+ (1,0) [0|255] ""  Master_ID1
 SG_ COB_ID_1400_01 m1 : 32|32@1+ (1,0) [128|4294967295] ""  Master_ID1
 SG_ Highest_sub_index_supported_0023 m0 : 32|8@1+ (1,0) [2|5] ""  Master_ID1
 SG_ SubIndex_1400 m5120M : 24|8@1+ (1,0) [0|2] ""  Master_ID1
 SG_ Configuration_time_1020_02 m2 : 32|32@1+ (1,0) [0|4294967295] ""  Master_ID1
 SG_ Configuration_date_1020_01 m1 : 32|32@1+ (1,0) [0|4294967295] ""  Master_ID1
 SG_ NrOfObjects_1020_00 m0 : 32|8@1+ (1,0) [0|255] ""  Master_ID1
 SG_ SubIndex_1020 m4128M : 24|8@1+ (1,0) [0|2] ""  Master_ID1
 SG_ Serial_number_1018_04 m4 : 32|32@1+ (1,0) [0|4294967295] ""  Master_ID1
 SG_ Revision_number_1018_03 m3 : 32|32@1+ (1,0) [0|4294967295] ""  Master_ID1
 SG_ Product_Code_1018_02 m2 : 32|32@1+ (1,0) [0|4294967295] ""  Master_ID1
 SG_ Vendor_Id_1018_01 m1 : 32|32@1+ (1,0) [0|4294967295] ""  Master_ID1
 SG_ Highest_sub_index_supported_0024 m0 : 32|8@1+ (1,0) [1|4] ""  Master_ID1
 SG_ SubIndex_1018 m4120M : 24|8@1+ (1,0) [0|4] ""  Master_ID1
 SG_ Producer_Heartbeat_Time_1017 m0 : 32|16@1+ (1,0) [0|65535] ""  Master_ID1
 SG_ SubIndex_1017 m4119M : 24|8@1+ (1,0) [0|0] ""  Master_ID1
 SG_ Consumer_Heartbeat_Time_1016_7E m126 : 32|32@1+ (1,0) [0|4294967295] ""  Master_ID1
 SG_ Consumer_Heartbeat_Time_1016_7D m125 : 32|32@1+ (1,0) [0|4294967295] ""  Master_ID1
 SG_ Consumer_Heartbeat_Time_1016_7C m124 : 32|32@1+ (1,0) [0|4294967295] ""  Master_ID1
 SG_ Consumer_Heartbeat_Time_1016_7B m123 : 32|32@1+ (1,0) [0|4294967295] ""  Master_ID1
 SG_ Consumer_Heartbeat_Time_1016_7A m122 : 32|32@1+ (1,0) [0|4294967295] ""  Master_ID1
 SG_ Consumer_Heartbeat_Time_1016_79 m121 : 32|32@1+ (1,0) [0|4294967295] ""  Master_ID1
 SG_ Consumer_Heartbeat_Time_1016_78 m120 : 32|32@1+ (1,0) [0|4294967295] ""  Master_ID1
 SG_ Consumer_Heartbeat_Time_1016_77 m119 : 32|32@1+ (1,0) [0|4294967295] ""  Master_ID1
 SG_ Consumer_Heartbeat_Time_1016_76 m118 : 32|32@1+ (1,0) [0|4294967295] ""  Master_ID1
 SG_ Consumer_Heartbeat_Time_1016_75 m117 : 32|32@1+ (1,0) [0|4294967295] ""  Master_ID1
 SG_ Consumer_Heartbeat_Time_1016_74 m116 : 32|32@1+ (1,0) [0|4294967295] ""  Master_ID1
 SG_ Consumer_Heartbeat_Time_1016_73 m115 : 32|32@1+ (1,0) [0|4294967295] ""  Master_ID1
 SG_ Consumer_Heartbeat_Time_1016_72 m114 : 32|32@1+ (1,0) [0|4294967295] ""  Master_ID1
 SG_ Consumer_Heartbeat_Time_1016_71 m113 : 32|32@1+ (1,0) [0|4294967295] ""  Master_ID1
 SG_ Consumer_Heartbeat_Time_1016_70 m112 : 32|32@1+ (1,0) [0|4294967295] ""  Master_ID1
 SG_ Consumer_Heartbeat_Time_1016_6F m111 : 32|32@1+ (1,0) [0|4294967295] ""  Master_ID1
 SG_ Consumer_Heartbeat_Time_1016_6E m110 : 32|32@1+ (1,0) [0|4294967295] ""  Master_ID1
 SG_ Consumer_Heartbeat_Time_1016_6D m109 : 32|32@1+ (1,0) [0|4294967295] ""  Master_ID1
 SG_ Consumer_Heartbeat_Time_1016_6C m108 : 32|32@1+ (1,0) [0|4294967295] ""  Master_ID1
 SG_ Consumer_Heartbeat_Time_1016_6B m107 : 32|32@1+ (1,0) [0|4294967295] ""  Master_ID1
 SG_ Consumer_Heartbeat_Time_1016_6A m106 : 32|32@1+ (1,0) [0|4294967295] ""  Master_ID1
 SG_ Consumer_Heartbeat_Time_1016_69 m105 : 32|32@1+ (1,0) [0|4294967295] ""  Master_ID1
 SG_ Consumer_Heartbeat_Time_1016_68 m104 : 32|32@1+ (1,0) [0|4294967295] ""  Master_ID1
 SG_ Consumer_Heartbeat_Time_1016_67 m103 : 32|32@1+ (1,0) [0|4294967295] ""  Master_ID1
 SG_ Consumer_Heartbeat_Time_1016_66 m102 : 32|32@1+ (1,0) [0|4294967295] ""  Master_ID1
 SG_ Consumer_Heartbeat_Time_1016_65 m101 : 32|32@1+ (1,0) [0|4294967295] ""  Master_ID1
 SG_ Consumer_Heartbeat_Time_1016_64 m100 : 32|32@1+ (1,0) [0|4294967295] ""  Master_ID1
 SG_ Consumer_Heartbeat_Time_1016_63 m99 : 32|32@1+ (1,0) [0|4294967295] ""  Master_ID1
 SG_ Consumer_Heartbeat_Time_1016_62 m98 : 32|32@1+ (1,0) [0|4294967295] ""  Master_ID1
 SG_ Consumer_Heartbeat_Time_1016_61 m97 : 32|32@1+ (1,0) [0|4294967295] ""  Master_ID1
 SG_ Consumer_Heartbeat_Time_1016_60 m96 : 32|32@1+ (1,0) [0|4294967295] ""  Master_ID1
 SG_ Consumer_Heartbeat_Time_1016_5F m95 : 32|32@1+ (1,0) [0|4294967295] ""  Master_ID1
 SG_ Consumer_Heartbeat_Time_1016_5E m94 : 32|32@1+ (1,0) [0|4294967295] ""  Master_ID1
 SG_ Consumer_Heartbeat_Time_1016_5D m93 : 32|32@1+ (1,0) [0|4294967295] ""  Master_ID1
 SG_ Consumer_Heartbeat_Time_1016_5C m92 : 32|32@1+ (1,0) [0|4294967295] ""  Master_ID1
 SG_ Consumer_Heartbeat_Time_1016_5B m91 : 32|32@1+ (1,0) [0|4294967295] ""  Master_ID1
 SG_ Consumer_Heartbeat_Time_1016_5A m90 : 32|32@1+ (1,0) [0|4294967295] ""  Master_ID1
 SG_ Consumer_Heartbeat_Time_1016_59 m89 : 32|32@1+ (1,0) [0|4294967295] ""  Master_ID1
 SG_ Consumer_Heartbeat_Time_1016_58 m88 : 32|32@1+ (1,0) [0|4294967295] ""  Master_ID1
 SG_ Consumer_Heartbeat_Time_1016_57 m87 : 32|32@1+ (1,0) [0|4294967295] ""  Master_ID1
 SG_ Consumer_Heartbeat_Time_1016_56 m86 : 32|32@1+ (1,0) [0|4294967295] ""  Master_ID1
 SG_ Consumer_Heartbeat_Time_1016_55 m85 : 32|32@1+ (1,0) [0|4294967295] ""  Master_ID1
 SG_ Consumer_Heartbeat_Time_1016_54 m84 : 32|32@1+ (1,0) [0|4294967295] ""  Master_ID1
 SG_ Consumer_Heartbeat_Time_1016_53 m83 : 32|32@1+ (1,0) [0|4294967295] ""  Master_ID1
 SG_ Consumer_Heartbeat_Time_1016_52 m82 : 32|32@1+ (1,0) [0|4294967295] ""  Master_ID1
 SG_ Consumer_Heartbeat_Time_1016_51 m81 : 32|32@1+ (1,0) [0|4294967295] ""  Master_ID1
 SG_ Consumer_Heartbeat_Time_1016_50 m80 : 32|32@1+ (1,0) [0|4294967295] ""  Master_ID1
 SG_ Consumer_Heartbeat_Time_1016_4F m79 : 32|32@1+ (1,0) [0|4294967295] ""  Master_ID1
 SG_ Consumer_Heartbeat_Time_1016_4E m78 : 32|32@1+ (1,0) [0|4294967295] ""  Master_ID1
 SG_ Consumer_Heartbeat_Time_1016_4D m77 : 32|32@1+ (1,0) [0|4294967295] ""  Master_ID1
 SG_ Consumer_Heartbeat_Time_1016_4C m76 : 32|32@1+ (1,0) [0|4294967295] ""  Master_ID1
 SG_ Consumer_Heartbeat_Time_1016_4B m75 : 32|32@1+ (1,0) [0|4294967295] ""  Master_ID1
 SG_ Consumer_Heartbeat_Time_1016_4A m74 : 32|32@1+ (1,0) [0|4294967295] ""  Master_ID1
 SG_ Consumer_Heartbeat_Time_1016_49 m73 : 32|32@1+ (1,0) [0|4294967295] ""  Master_ID1
 SG_ Consumer_Heartbeat_Time_1016_48 m72 : 32|32@1+ (1,0) [0|4294967295] ""  Master_ID1
 SG_ Consumer_Heartbeat_Time_1016_47 m71 : 32|32@1+ (1,0) [0|4294967295] ""  Master_ID1
 SG_ Consumer_Heartbeat_Time_1016_46 m70 : 32|32@1+ (1,0) [0|4294967295] ""  Master_ID1
 SG_ Consumer_Heartbeat_Time_1016_45 m69 : 32|32@1+ (1,0) [0|4294967295] ""  Master_ID1
 SG_ Consumer_Heartbeat_Time_1016_44 m68 : 32|32@1+ (1,0) [0|4294967295] ""  Master_ID1
 SG_ Consumer_Heartbeat_Time_1016_43 m67 : 32|32@1+ (1,0) [0|4294967295] ""  Master_ID1
 SG_ Consumer_Heartbeat_Time_1016_42 m66 : 32|32@1+ (1,0) [0|4294967295] ""  Master_ID1
 SG_ Consumer_Heartbeat_Time_1016_41 m65 : 32|32@1+ (1,0) [0|4294967295] ""  Master_ID1
 SG_ Consumer_Heartbeat_Time_1016_40 m64 : 32|32@1+ (1,0) [0|4294967295] ""  Master_ID1
 SG_ Consumer_Heartbeat_Time_1016_3F m63 : 32|32@1+ (1,0) [0|4294967295] ""  Master_ID1
 SG_ Consumer_Heartbeat_Time_1016_3E m62 : 32|32@1+ (1,0) [0|4294967295] ""  Master_ID1
 SG_ Consumer_Heartbeat_Time_1016_3D m61 : 32|32@1+ (1,0) [0|4294967295] ""  Master_ID1
 SG_ Consumer_Heartbeat_Time_1016_3C m60 : 32|32@1+ (1,0) [0|4294967295] ""  Master_ID1
 SG_ Consumer_Heartbeat_Time_1016_3B m59 : 32|32@1+ (1,0) [0|4294967295] ""  Master_ID1
 SG_ Consumer_Heartbeat_Time_1016_3A m58 : 32|32@1+ (1,0) [0|4294967295] ""  Master_ID1
 SG_ Consumer_Heartbeat_Time_1016_39 m57 : 32|32@1+ (1,0) [0|4294967295] ""  Master_ID1
 SG_ Consumer_Heartbeat_Time_1016_38 m56 : 32|32@1+ (1,0) [0|4294967295] ""  Master_ID1
 SG_ Consumer_Heartbeat_Time_1016_37 m55 : 32|32@1+ (1,0) [0|4294967295] ""  Master_ID1
 SG_ Consumer_Heartbeat_Time_1016_36 m54 : 32|32@1+ (1,0) [0|4294967295] ""  Master_ID1
 SG_ Consumer_Heartbeat_Time_1016_35 m53 : 32|32@1+ (1,0) [0|4294967295] ""  Master_ID1
 SG_ Consumer_Heartbeat_Time_1016_34 m52 : 32|32@1+ (1,0) [0|4294967295] ""  Master_ID1
 SG_ Consumer_Heartbeat_Time_1016_33 m51 : 32|32@1+ (1,0) [0|4294967295] ""  Master_ID1
 SG_ Consumer_Heartbeat_Time_1016_32 m50 : 32|32@1+ (1,0) [0|4294967295] ""  Master_ID1
 SG_ Consumer_Heartbeat_Time_1016_31 m49 : 32|32@1+ (1,0) [0|4294967295] ""  Master_ID1
 SG_ Consumer_Heartbeat_Time_1016_30 m48 : 32|32@1+ (1,0) [0|4294967295] ""  Master_ID1
 SG_ Consumer_Heartbeat_Time_1016_2F m47 : 32|32@1+ (1,0) [0|4294967295] ""  Master_ID1
 SG_ Consumer_Heartbeat_Time_1016_2E m46 : 32|32@1+ (1,0) [0|4294967295] ""  Master_ID1
 SG_ Consumer_Heartbeat_Time_1016_2D m45 : 32|32@1+ (1,0) [0|4294967295] ""  Master_ID1
 SG_ Consumer_Heartbeat_Time_1016_2C m44 : 32|32@1+ (1,0) [0|4294967295] ""  Master_ID1
 SG_ Consumer_Heartbeat_Time_1016_2B m43 : 32|32@1+ (1,0) [0|4294967295] ""  Master_ID1
 SG_ Consumer_Heartbeat_Time_1016_2A m42 : 32|32@1+ (1,0) [0|4294967295] ""  Master_ID1
 SG_ Consumer_Heartbeat_Time_1016_29 m41 : 32|32@1+ (1,0) [0|4294967295] ""  Master_ID1
 SG_ Consumer_Heartbeat_Time_1016_28 m40 : 32|32@1+ (1,0) [0|4294967295] ""  Master_ID1
 SG_ Consumer_Heartbeat_Time_1016_27 m39 : 32|32@1+ (1,0) [0|4294967295] ""  Master_ID1
 SG_ Consumer_Heartbeat_Time_1016_26 m38 : 32|32@1+ (1,0) [0|4294967295] ""  Master_ID1
 SG_ Consumer_Heartbeat_Time_1016_25 m37 : 32|32@1+ (1,0) [0|4294967295] ""  Master_ID1
 SG_ Consumer_Heartbeat_Time_1016_24 m36 : 32|32@1+ (1,0) [0|4294967295] ""  Master_ID1
 SG_ Consumer_Heartbeat_Time_1016_23 m35 : 32|32@1+ (1,0) [0|4294967295] ""  Master_ID1
 SG_ Consumer_Heartbeat_Time_1016_22 m34 : 32|32@1+ (1,0) [0|4294967295] ""  Master_ID1
 SG_ Consumer_Heartbeat_Time_1016_21 m33 : 32|32@1+ (1,0) [0|4294967295] ""  Master_ID1
 SG_ Consumer_Heartbeat_Time_1016_20 m32 : 32|32@1+ (1,0) [0|4294967295] ""  Master_ID1
 SG_ Consumer_Heartbeat_Time_1016_1F m31 : 32|32@1+ (1,0) [0|4294967295] ""  Master_ID1
 SG_ Consumer_Heartbeat_Time_1016_1E m30 : 32|32@1+ (1,0) [0|4294967295] ""  Master_ID1
 SG_ Consumer_Heartbeat_Time_1016_1D m29 : 32|32@1+ (1,0) [0|4294967295] ""  Master_ID1
 SG_ Consumer_Heartbeat_Time_1016_1C m28 : 32|32@1+ (1,0) [0|4294967295] ""  Master_ID1
 SG_ Consumer_Heartbeat_Time_1016_1B m27 : 32|32@1+ (1,0) [0|4294967295] ""  Master_ID1
 SG_ Consumer_Heartbeat_Time_1016_1A m26 : 32|32@1+ (1,0) [0|4294967295] ""  Master_ID1
 SG_ Consumer_Heartbeat_Time_1016_19 m25 : 32|32@1+ (1,0) [0|4294967295] ""  Master_ID1
 SG_ Consumer_Heartbeat_Time_1016_18 m24 : 32|32@1+ (1,0) [0|4294967295] ""  Master_ID1
 SG_ Consumer_Heartbeat_Time_1016_17 m23 : 32|32@1+ (1,0) [0|4294967295] ""  Master_ID1
 SG_ Consumer_Heartbeat_Time_1016_16 m22 : 32|32@1+ (1,0) [0|4294967295] ""  Master_ID1
 SG_ Consumer_Heartbeat_Time_1016_15 m21 : 32|32@1+ (1,0) [0|4294967295] ""  Master_ID1
 SG_ Consumer_Heartbeat_Time_1016_14 m20 : 32|32@1+ (1,0) [0|4294967295] ""  Master_ID1
 SG_ Consumer_Heartbeat_Time_1016_13 m19 : 32|32@1+ (1,0) [0|4294967295] ""  Master_ID1
 SG_ Consumer_Heartbeat_Time_1016_12 m18 : 32|32@1+ (1,0) [0|4294967295] ""  Master_ID1
 SG_ Consumer_Heartbeat_Time_1016_11 m17 : 32|32@1+ (1,0) [0|4294967295] ""  Master_ID1
 SG_ Consumer_Heartbeat_Time_1016_10 m16 : 32|32@1+ (1,0) [0|4294967295] ""  Master_ID1
 SG_ Consumer_Heartbeat_Time_1016_0F m15 : 32|32@1+ (1,0) [0|4294967295] ""  Master_ID1
 SG_ Consumer_Heartbeat_Time_1016_0E m14 : 32|32@1+ (1,0) [0|4294967295] ""  Master_ID1
 SG_ Consumer_Heartbeat_Time_1016_0D m13 : 32|32@1+ (1,0) [0|4294967295] ""  Master_ID1
 SG_ Consumer_Heartbeat_Time_1016_0C m12 : 32|32@1+ (1,0) [0|4294967295] ""  Master_ID1
 SG_ Consumer_Heartbeat_Time_1016_0B m11 : 32|32@1+ (1,0) [0|4294967295] ""  Master_ID1
 SG_ Consumer_Heartbeat_Time_1016_0A m10 : 32|32@1+ (1,0) [0|4294967295] ""  Master_ID1
 SG_ Consumer_Heartbeat_Time_1016_09 m9 : 32|32@1+ (1,0) [0|4294967295] ""  Master_ID1
 SG_ Consumer_Heartbeat_Time_1016_08 m8 : 32|32@1+ (1,0) [0|4294967295] ""  Master_ID1
 SG_ Consumer_Heartbeat_Time_1016_07 m7 : 32|32@1+ (1,0) [0|4294967295] ""  Master_ID1
 SG_ Consumer_Heartbeat_Time_1016_06 m6 : 32|32@1+ (1,0) [0|4294967295] ""  Master_ID1
 SG_ Consumer_Heartbeat_Time_1016_05 m5 : 32|32@1+ (1,0) [0|4294967295] ""  Master_ID1
 SG_ Consumer_Heartbeat_Time_1016_04 m4 : 32|32@1+ (1,0) [0|4294967295] ""  Master_ID1
 SG_ Consumer_Heartbeat_Time_1016_03 m3 : 32|32@1+ (1,0) [0|4294967295] ""  Master_ID1
 SG_ Consumer_Heartbeat_Time_1016_02 m2 : 32|32@1+ (1,0) [0|4294967295] ""  Master_ID1
 SG_ Consumer_Heartbeat_Time_1016_01 m1 : 32|32@1+ (1,0) [0|4294967295] ""  Master_ID1
 SG_ NrOfObjects_1016_00 m0 : 32|8@1+ (1,0) [0|255] ""  Master_ID1
 SG_ SubIndex_1016 m4118M : 24|8@1+ (1,0) [0|126] ""  Master_ID1
 SG_ Restore_all_Default_Paramet_0000 m1 : 32|32@1+ (1,0) [0|4294967295] ""  Master_ID1
 SG_ Highest_sub_index_supported_0025 m0 : 32|8@1+ (1,0) [0|255] ""  Master_ID1
 SG_ SubIndex_1011 m4113M : 24|8@1+ (1,0) [0|1] ""  Master_ID1
 SG_ Save_all_Parameters_1010_01 m1 : 32|32@1+ (1,0) [0|4294967295] ""  Master_ID1
 SG_ Highest_sub_index_supported_0026 m0 : 32|8@1+ (1,0) [0|255] ""  Master_ID1
 SG_ SubIndex_1010 m4112M : 24|8@1+ (1,0) [0|1] ""  Master_ID1
 SG_ Life_Time_Factor_100D m0 : 32|8@1+ (1,0) [0|255] ""  Master_ID1
 SG_ SubIndex_100D m4109M : 24|8@1+ (1,0) [0|0] ""  Master_ID1
 SG_ Guard_Time_100C m0 : 32|16@1+ (1,0) [0|65535] ""  Master_ID1
 SG_ SubIndex_100C m4108M : 24|8@1+ (1,0) [0|0] ""  Master_ID1
 SG_ Sync_Window_Length_1007 m0 : 32|32@1+ (1,0) [0|4294967295] ""  Master_ID1
 SG_ SubIndex_1007 m4103M : 24|8@1+ (1,0) [0|0] ""  Master_ID1
 SG_ Communication_Cycle_Period_1006 m0 : 32|32@1+ (1,0) [0|4294967295] ""  Master_ID1
 SG_ SubIndex_1006 m4102M : 24|8@1+ (1,0) [0|0] ""  Master_ID1
 SG_ COB_ID_SYNC_1005 m0 : 32|32@1+ (1,0) [128|4294967295] ""  Master_ID1
 SG_ SubIndex_1005 m4101M : 24|8@1+ (1,0) [0|0] ""  Master_ID1
 SG_ Manufacturer_Status_Registe_0000 m0 : 32|32@1+ (1,0) [0|4294967295] ""  Master_ID1
 SG_ SubIndex_1002 m4098M : 24|8@1+ (1,0) [0|0] ""  Master_ID1
 SG_ Error_Register_1001 m0 : 32|8@1+ (1,0) [0|255] ""  Master_ID1
 SG_ SubIndex_1001 m4097M : 24|8@1+ (1,0) [0|0] ""  Master_ID1
 SG_ Device_Type_1000 m0 : 32|32@1+ (1,0) [0|4294967295] ""  Master_ID1
 SG_ SubIndex_1000 m4096M : 24|8@1+ (1,0) [0|0] ""  Master_ID1
 SG_ Index m1M : 8|16@1+ (1,0) [4096|42624] ""  Master_ID1
 SG_ TransferType m1M : 1|1@1+ (1,0) [0|1] ""  Master_ID1
 SG_ NotUsedBytes m1 : 2|2@1+ (1,0) [0|3] ""  Master_ID1
 SG_ SizeIndicator m1 : 0|1@1+ (1,0) [0|1] ""  Master_ID1
 SG_ CCS M : 5|3@1+ (1,0) [0|6] ""  Master_ID1

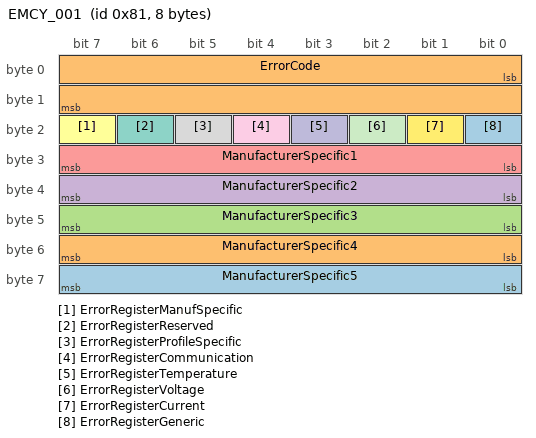
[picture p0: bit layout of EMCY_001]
BO_ 129 EMCY_001: 8 Master_ID1
 SG_ ManufacturerSpecific5 : 56|8@1+ (1,0) [0|0] "" Vector__XXX
 SG_ ManufacturerSpecific4 : 48|8@1+ (1,0) [0|0] "" Vector__XXX
 SG_ ManufacturerSpecific3 : 40|8@1+ (1,0) [0|0] "" Vector__XXX
 SG_ ManufacturerSpecific2 : 32|8@1+ (1,0) [0|0] "" Vector__XXX
 SG_ ManufacturerSpecific1 : 24|8@1+ (1,0) [0|0] "" Vector__XXX
 SG_ ErrorRegisterManufSpecific : 23|1@1+ (1,0) [0|0] "" Vector__XXX
 SG_ ErrorRegisterReserved : 22|1@1+ (1,0) [0|0] "" Vector__XXX
 SG_ ErrorRegisterProfileSpecific : 21|1@1+ (1,0) [0|0] "" Vector__XXX
 SG_ ErrorRegisterCommunication : 20|1@1+ (1,0) [0|0] "" Vector__XXX
 SG_ ErrorRegisterTemperature : 19|1@1+ (1,0) [0|0] "" Vector__XXX
 SG_ ErrorRegisterVoltage : 18|1@1+ (1,0) [0|0] "" Vector__XXX
 SG_ ErrorRegisterCurrent : 17|1@1+ (1,0) [0|0] "" Vector__XXX
 SG_ ErrorRegisterGeneric : 16|1@1+ (1,0) [0|0] "" Vector__XXX
 SG_ ErrorCode : 0|16@1+ (1,0) [0|0] "" Vector__XXX

BO_ 1804 HBGuard_012: 1 SupportFront_ID12
 SG_ Toggle : 7|1@1+ (1,0) [0|0] "" Vector__XXX
 SG_ State : 0|7@1+ (1,0) [0|0] "" Vector__XXX

BO_ 1420 SSDO_012: 8 SupportFront_ID12
 SG_ supported_drive_modes_6502 m0 : 32|32@1+ (1,0) [0|4294967295] "" Vector__XXX
 SG_ SubIndex_6502 m25858M : 24|8@1+ (1,0) [0|0] "" Vector__XXX
 SG_ motor_service_period_6407 m0 : 32|32@1+ (1,0) [0|4294967295] "" Vector__XXX
 SG_ SubIndex_6407 m25607M : 24|8@1+ (1,0) [0|0] "" Vector__XXX
 SG_ motor_type_6402 m0 : 32|16@1+ (1,0) [0|65535] "" Vector__XXX
 SG_ SubIndex_6402 m25602M : 24|8@1+ (1,0) [0|0] "" Vector__XXX
 SG_ target_velocity_60FF m0 : 32|32@1- (1,0) [-2147483648|2147483647] "" Vector__XXX
 SG_ SubIndex_60FF m24831M : 24|8@1+ (1,0) [0|0] "" Vector__XXX
 SG_ bitmask_60FE_02 m2 : 32|32@1+ (1,0) [0|4294967295] "" Vector__XXX
 SG_ physical_outputs_60FE_01 m1 : 32|32@1+ (1,0) [0|4294967295] "" Vector__XXX
 SG_ digital_outputs_highest_subindex m0 : 32|8@1+ (1,0) [0|255] "" Vector__XXX
 SG_ SubIndex_60FE m24830M : 24|8@1+ (1,0) [0|2] "" Vector__XXX
 SG_ digital_inputs_60FD m0 : 32|32@1+ (1,0) [0|4294967295] "" Vector__XXX
 SG_ SubIndex_60FD m24829M : 24|8@1+ (1,0) [0|0] "" Vector__XXX
 SG_ polarity_607E m0 : 32|8@1+ (1,0) [0|255] "" Vector__XXX
 SG_ SubIndex_607E m24702M : 24|8@1+ (1,0) [0|0] "" Vector__XXX
 SG_ target_position_607A m0 : 32|32@1- (1,0) [-2147483648|2147483647] "" Vector__XXX
 SG_ SubIndex_607A m24698M : 24|8@1+ (1,0) [0|0] "" Vector__XXX
 SG_ torque_actual_value_6077 m0 : 32|16@1- (1,0) [-32768|32767] "" Vector__XXX
 SG_ SubIndex_6077 m24695M : 24|8@1+ (1,0) [0|0] "" Vector__XXX
 SG_ target_torque_6071 m0 : 32|16@1- (1,0) [-32768|32767] "" Vector__XXX
 SG_ SubIndex_6071 m24689M : 24|8@1+ (1,0) [0|0] "" Vector__XXX
 SG_ velocity_actual_value_606C m0 : 32|32@1- (1,0) [-2147483648|2147483647] "" Vector__XXX
 SG_ SubIndex_606C m24684M : 24|8@1+ (1,0) [0|0] "" Vector__XXX
 SG_ position_window_6067 m0 : 32|32@1+ (1,0) [0|4294967295] "" Vector__XXX
 SG_ SubIndex_6067 m24679M : 24|8@1+ (1,0) [0|0] "" Vector__XXX
 SG_ position_actual_value_6064 m0 : 32|32@1- (1,0) [0|100] "" Vector__XXX
 SG_ SubIndex_6064 m24676M : 24|8@1+ (1,0) [0|0] "" Vector__XXX
 SG_ position_actual_internal_value_6 m0 : 32|32@1- (1,0) [-2147483648|2147483647] "" Vector__XXX
 SG_ SubIndex_6063 m24675M : 24|8@1+ (1,0) [0|0] "" Vector__XXX
 SG_ position_demand_value_6062 m0 : 32|32@1- (1,0) [-2147483648|2147483647] "" Vector__XXX
 SG_ SubIndex_6062 m24674M : 24|8@1+ (1,0) [0|0] "" Vector__XXX
 SG_ modes_of_operation_display_6061 m0 : 32|8@1- (1,0) [-128|127] "" Vector__XXX
 SG_ SubIndex_6061 m24673M : 24|8@1+ (1,0) [0|0] "" Vector__XXX
 SG_ modes_of_operation_6060 m0 : 32|8@1- (1,0) [-128|127] "" Vector__XXX
 SG_ SubIndex_6060 m24672M : 24|8@1+ (1,0) [0|0] "" Vector__XXX
 SG_ fault_reaction_option_code_605E m0 : 32|16@1- (1,0) [-32768|32767] "" Vector__XXX
 SG_ SubIndex_605E m24670M : 24|8@1+ (1,0) [0|0] "" Vector__XXX
 SG_ stop_option_code_605D m0 : 32|16@1- (1,0) [-32768|32767] "" Vector__XXX
 SG_ SubIndex_605D m24669M : 24|8@1+ (1,0) [0|0] "" Vector__XXX
 SG_ disable_operation_option_code_60 m0 : 32|16@1- (1,0) [-32768|32767] "" Vector__XXX
 SG_ SubIndex_605C m24668M : 24|8@1+ (1,0) [0|0] "" Vector__XXX
 SG_ shutdown_option_code_605B m0 : 32|16@1- (1,0) [-32768|32767] "" Vector__XXX
 SG_ SubIndex_605B m24667M : 24|8@1+ (1,0) [0|0] "" Vector__XXX
 SG_ quick_stop_option_code_605A m0 : 32|16@1- (1,0) [-32768|32767] "" Vector__XXX
 SG_ SubIndex_605A m24666M : 24|8@1+ (1,0) [0|0] "" Vector__XXX
 SG_ delta_time_6049_02 m2 : 32|16@1+ (1,0) [0|65535] "" Vector__XXX
 SG_ delta_speed_6049_01 m1 : 32|32@1+ (1,0) [0|4294967295] "" Vector__XXX
 SG_ NrOfObjects_6049_00 m0 : 32|8@1+ (1,0) [0|255] "" Vector__XXX
 SG_ SubIndex_6049 m24649M : 24|8@1+ (1,0) [0|2] "" Vector__XXX
 SG_ delta_time_6048_02 m2 : 32|16@1+ (1,0) [0|65535] "" Vector__XXX
 SG_ delta_speed_6048_01 m1 : 32|32@1+ (1,0) [0|4294967295] "" Vector__XXX
 SG_ NrOfObjects_6048_00 m0 : 32|8@1+ (1,0) [0|255] "" Vector__XXX
 SG_ SubIndex_6048 m24648M : 24|8@1+ (1,0) [0|2] "" Vector__XXX
 SG_ vl_velocity_max_amount_6046_02 m2 : 32|32@1+ (1,0) [0|4294967295] "" Vector__XXX
 SG_ vl_velocity_min_amount_6046_01 m1 : 32|32@1+ (1,0) [0|4294967295] "" Vector__XXX
 SG_ vl_velocity_min_max_amount_highe m0 : 32|8@1+ (1,0) [0|255] "" Vector__XXX
 SG_ SubIndex_6046 m24646M : 24|8@1+ (1,0) [0|2] "" Vector__XXX
 SG_ vl_control_effort_6044 m0 : 32|16@1- (1,0) [-32768|32767] "" Vector__XXX
 SG_ SubIndex_6044 m24644M : 24|8@1+ (1,0) [0|0] "" Vector__XXX
 SG_ vl_velocity_demand_6043 m0 : 32|16@1- (1,0) [-1000|1000] "" Vector__XXX
 SG_ SubIndex_6043 m24643M : 24|8@1+ (1,0) [0|0] "" Vector__XXX
 SG_ vl_target_velocity_6042 m0 : 32|16@1- (1,0) [-32768|32767] "" Vector__XXX
 SG_ SubIndex_6042 m24642M : 24|8@1+ (1,0) [0|0] "" Vector__XXX
 SG_ statusword_6041 m0 : 32|16@1+ (1,0) [0|65535] "" Vector__XXX
 SG_ SubIndex_6041 m24641M : 24|8@1+ (1,0) [0|0] "" Vector__XXX
 SG_ controlword_6040 m0 : 32|16@1+ (1,0) [0|65535] "" Vector__XXX
 SG_ SubIndex_6040 m24640M : 24|8@1+ (1,0) [0|0] "" Vector__XXX
 SG_ error_code_603F m0 : 32|16@1+ (1,0) [0|65535] "" Vector__XXX
 SG_ SubIndex_603F m24639M : 24|8@1+ (1,0) [0|0] "" Vector__XXX
 SG_ abort_connection_option_code_600 m0 : 32|16@1- (1,0) [-32768|3] "" Vector__XXX
 SG_ SubIndex_6007 m24583M : 24|8@1+ (1,0) [0|0] "" Vector__XXX
 SG_ PDO_Mapping_Entry_1A06_02 m2 : 32|32@1+ (1,0) [0|4294967295] "" Vector__XXX
 SG_ PDO_Mapping_Entry_1A06_01 m1 : 32|32@1+ (1,0) [0|4294967295] "" Vector__XXX
 SG_ NrOfMappedObjects_1A06_00 m0 : 32|8@1+ (1,0) [0|8] "" Vector__XXX
 SG_ SubIndex_1A06 m6662M : 24|8@1+ (1,0) [0|2] "" Vector__XXX
 SG_ PDO_Mapping_Entry_1A05_02 m2 : 32|32@1+ (1,0) [0|4294967295] "" Vector__XXX
 SG_ PDO_Mapping_Entry_1A05_01 m1 : 32|32@1+ (1,0) [0|4294967295] "" Vector__XXX
 SG_ NrOfMappedObjects_1A05_00 m0 : 32|8@1+ (1,0) [0|8] "" Vector__XXX
 SG_ SubIndex_1A05 m6661M : 24|8@1+ (1,0) [0|2] "" Vector__XXX
 SG_ PDO_Mapping_Entry_1A04_02 m2 : 32|32@1+ (1,0) [0|4294967295] "" Vector__XXX
 SG_ PDO_Mapping_Entry_1A04_01 m1 : 32|32@1+ (1,0) [0|4294967295] "" Vector__XXX
 SG_ NrOfMappedObjects_1A04_00 m0 : 32|8@1+ (1,0) [0|8] "" Vector__XXX
 SG_ SubIndex_1A04 m6660M : 24|8@1+ (1,0) [0|2] "" Vector__XXX
 SG_ PDO_Mapping_Entry_1A03_02 m2 : 32|32@1+ (1,0) [0|4294967295] "" Vector__XXX
 SG_ PDO_Mapping_Entry_1A03_01 m1 : 32|32@1+ (1,0) [0|4294967295] "" Vector__XXX
 SG_ NrOfMappedObjects_1A03_00 m0 : 32|8@1+ (1,0) [0|8] "" Vector__XXX
 SG_ SubIndex_1A03 m6659M : 24|8@1+ (1,0) [0|2] "" Vector__XXX
 SG_ mappedObj2_1A02_02 m2 : 32|32@1+ (1,0) [0|4294967295] "" Vector__XXX
 SG_ mappedObj1_1A02_01 m1 : 32|32@1+ (1,0) [0|4294967295] "" Vector__XXX
 SG_ NrOfMappedObjects_1A02_00 m0 : 32|8@1+ (1,0) [0|8] "" Vector__XXX
 SG_ SubIndex_1A02 m6658M : 24|8@1+ (1,0) [0|2] "" Vector__XXX
 SG_ mappedObj2_1A01_02 m2 : 32|32@1+ (1,0) [0|4294967295] "" Vector__XXX
 SG_ mappedObj1_1A01_01 m1 : 32|32@1+ (1,0) [0|4294967295] "" Vector__XXX
 SG_ NrOfMappedObjects_1A01_00 m0 : 32|8@1+ (1,0) [0|8] "" Vector__XXX
 SG_ SubIndex_1A01 m6657M : 24|8@1+ (1,0) [0|2] "" Vector__XXX
 SG_ mappedObj1_1A00_01 m1 : 32|32@1+ (1,0) [0|4294967295] "" Vector__XXX
 SG_ NrOfMappedObjects_1A00_00 m0 : 32|8@1+ (1,0) [0|8] "" Vector__XXX
 SG_ SubIndex_1A00 m6656M : 24|8@1+ (1,0) [0|1] "" Vector__XXX
 SG_ EventTimer_1806_05 m5 : 32|16@1+ (1,0) [0|65535] "" Vector__XXX
 SG_ TransmissionType_1806_02 m2 : 32|8@1+ (1,0) [0|255] "" Vector__XXX
 SG_ COB_ID_1806_01 m1 : 32|32@1+ (1,0) [128|4294967295] "" Vector__XXX
 SG_ Highest_sub_index_supported_1806 m0 : 32|8@1+ (1,0) [2|5] "" Vector__XXX
 SG_ SubIndex_1806 m6150M : 24|8@1+ (1,0) [0|5] "" Vector__XXX
 SG_ EventTimer_1805_05 m5 : 32|16@1+ (1,0) [0|65535] "" Vector__XXX
 SG_ TransmissionType_1805_02 m2 : 32|8@1+ (1,0) [0|255] "" Vector__XXX
 SG_ COB_ID_1805_01 m1 : 32|32@1+ (1,0) [128|4294967295] "" Vector__XXX
 SG_ Highest_sub_index_supported_1805 m0 : 32|8@1+ (1,0) [2|5] "" Vector__XXX
 SG_ SubIndex_1805 m6149M : 24|8@1+ (1,0) [0|5] "" Vector__XXX
 SG_ EventTimer_1804_05 m5 : 32|16@1+ (1,0) [0|65535] "" Vector__XXX
 SG_ TransmissionType_1804_02 m2 : 32|8@1+ (1,0) [0|255] "" Vector__XXX
 SG_ COB_ID_1804_01 m1 : 32|32@1+ (1,0) [128|4294967295] "" Vector__XXX
 SG_ Highest_sub_index_supported_0027 m0 : 32|8@1+ (1,0) [2|5] "" Vector__XXX
 SG_ SubIndex_1804 m6148M : 24|8@1+ (1,0) [0|5] "" Vector__XXX
 SG_ EventTimer_1803_05 m5 : 32|16@1+ (1,0) [0|65535] "" Vector__XXX
 SG_ TransmissionType_1803_02 m2 : 32|8@1+ (1,0) [0|255] "" Vector__XXX
 SG_ COB_ID_1803_01 m1 : 32|32@1+ (1,0) [128|4294967295] "" Vector__XXX
 SG_ Highest_sub_index_supported_0028 m0 : 32|8@1+ (1,0) [2|5] "" Vector__XXX
 SG_ SubIndex_1803 m6147M : 24|8@1+ (1,0) [0|5] "" Vector__XXX
 SG_ EventTimer_1802_05 m5 : 32|16@1+ (1,0) [0|65535] "" Vector__XXX
 SG_ TransmissionType_1802_02 m2 : 32|8@1+ (1,0) [0|255] "" Vector__XXX
 SG_ COB_ID_1802_01 m1 : 32|32@1+ (1,0) [128|4294967295] "" Vector__XXX
 SG_ Highest_sub_index_supported_0029 m0 : 32|8@1+ (1,0) [2|5] "" Vector__XXX
 SG_ SubIndex_1802 m6146M : 24|8@1+ (1,0) [0|5] "" Vector__XXX
 SG_ EventTimer_1801_05 m5 : 32|16@1+ (1,0) [0|65535] "" Vector__XXX
 SG_ TransmissionType_1801_02 m2 : 32|8@1+ (1,0) [0|255] "" Vector__XXX
 SG_ COB_ID_1801_01 m1 : 32|32@1+ (1,0) [128|4294967295] "" Vector__XXX
 SG_ Highest_sub_index_supported_0030 m0 : 32|8@1+ (1,0) [2|5] "" Vector__XXX
 SG_ SubIndex_1801 m6145M : 24|8@1+ (1,0) [0|5] "" Vector__XXX
 SG_ EventTimer_1800_05 m5 : 32|16@1+ (1,0) [0|65535] "" Vector__XXX
 SG_ TransmissionType_1800_02 m2 : 32|8@1+ (1,0) [0|255] "" Vector__XXX
 SG_ COB_ID_1800_01 m1 : 32|32@1+ (1,0) [128|4294967295] "" Vector__XXX
 SG_ Highest_sub_index_supported_0031 m0 : 32|8@1+ (1,0) [2|5] "" Vector__XXX
 SG_ SubIndex_1800 m6144M : 24|8@1+ (1,0) [0|5] "" Vector__XXX
 SG_ PDO_Mapping_Entry_1607_02 m2 : 32|32@1+ (1,0) [0|4294967295] "" Vector__XXX
 SG_ PDO_Mapping_Entry_1607_01 m1 : 32|32@1+ (1,0) [0|4294967295] "" Vector__XXX
 SG_ NrOfMappedObjects_1607_00 m0 : 32|8@1+ (1,0) [0|8] "" Vector__XXX
 SG_ SubIndex_1607 m5639M : 24|8@1+ (1,0) [0|2] "" Vector__XXX
 SG_ PDO_Mapping_Entry_1606_02 m2 : 32|32@1+ (1,0) [0|4294967295] "" Vector__XXX
 SG_ PDO_Mapping_Entry_1606_01 m1 : 32|32@1+ (1,0) [0|4294967295] "" Vector__XXX
 SG_ NrOfMappedObjects_1606_00 m0 : 32|8@1+ (1,0) [0|8] "" Vector__XXX
 SG_ SubIndex_1606 m5638M : 24|8@1+ (1,0) [0|2] "" Vector__XXX
 SG_ PDO_Mapping_Entry_1605_02 m2 : 32|32@1+ (1,0) [0|4294967295] "" Vector__XXX
 SG_ PDO_Mapping_Entry_1605_01 m1 : 32|32@1+ (1,0) [0|4294967295] "" Vector__XXX
 SG_ NrOfMappedObjects_1605_00 m0 : 32|8@1+ (1,0) [0|8] "" Vector__XXX
 SG_ SubIndex_1605 m5637M : 24|8@1+ (1,0) [0|2] "" Vector__XXX
 SG_ PDO_Mapping_Entry_1604_02 m2 : 32|32@1+ (1,0) [0|4294967295] "" Vector__XXX
 SG_ PDO_Mapping_Entry_1604_01 m1 : 32|32@1+ (1,0) [0|4294967295] "" Vector__XXX
 SG_ NrOfMappedObjects_1604_00 m0 : 32|8@1+ (1,0) [0|8] "" Vector__XXX
 SG_ SubIndex_1604 m5636M : 24|8@1+ (1,0) [0|2] "" Vector__XXX
 SG_ PDO_Mapping_Entry_1603_02 m2 : 32|32@1+ (1,0) [0|4294967295] "" Vector__XXX
 SG_ PDO_Mapping_Entry_1603_01 m1 : 32|32@1+ (1,0) [0|4294967295] "" Vector__XXX
 SG_ NrOfMappedObjects_1603_00 m0 : 32|8@1+ (1,0) [0|8] "" Vector__XXX
 SG_ SubIndex_1603 m5635M : 24|8@1+ (1,0) [0|2] "" Vector__XXX
 SG_ PDO_Mapping_Entry_1602_02 m2 : 32|32@1+ (1,0) [0|4294967295] "" Vector__XXX
 SG_ PDO_Mapping_Entry_1602_01 m1 : 32|32@1+ (1,0) [0|4294967295] "" Vector__XXX
 SG_ NrOfMappedObjects_1602_00 m0 : 32|8@1+ (1,0) [0|8] "" Vector__XXX
 SG_ SubIndex_1602 m5634M : 24|8@1+ (1,0) [0|2] "" Vector__XXX
 SG_ PDO_Mapping_Entry_1601_02 m2 : 32|32@1+ (1,0) [0|4294967295] "" Vector__XXX
 SG_ PDO_Mapping_Entry_1601_01 m1 : 32|32@1+ (1,0) [0|4294967295] "" Vector__XXX
 SG_ NrOfMappedObjects_1601_00 m0 : 32|8@1+ (1,0) [0|8] "" Vector__XXX
 SG_ SubIndex_1601 m5633M : 24|8@1+ (1,0) [0|2] "" Vector__XXX
 SG_ PDO_Mapping_Entry_1600_04 m4 : 32|32@1+ (1,0) [0|4294967295] "" Vector__XXX
 SG_ PDO_Mapping_Entry_1600_03 m3 : 32|32@1+ (1,0) [0|4294967295] "" Vector__XXX
 SG_ mappedObj2_1600_02 m2 : 32|32@1+ (1,0) [0|4294967295] "" Vector__XXX
 SG_ mappedObj1_1600_01 m1 : 32|32@1+ (1,0) [0|4294967295] "" Vector__XXX
 SG_ NrOfMappedObjects_1600_00 m0 : 32|8@1+ (1,0) [0|8] "" Vector__XXX
 SG_ SubIndex_1600 m5632M : 24|8@1+ (1,0) [0|4] "" Vector__XXX
 SG_ TransmissionType_1407_02 m2 : 32|8@1+ (1,0) [0|255] "" Vector__XXX
 SG_ COB_ID_1407_01 m1 : 32|32@1+ (1,0) [128|4294967295] "" Vector__XXX
 SG_ Highest_sub_index_supported_1407 m0 : 32|8@1+ (1,0) [2|5] "" Vector__XXX
 SG_ SubIndex_1407 m5127M : 24|8@1+ (1,0) [0|2] "" Vector__XXX
 SG_ TransmissionType_1406_02 m2 : 32|8@1+ (1,0) [0|255] "" Vector__XXX
 SG_ COB_ID_1406_01 m1 : 32|32@1+ (1,0) [128|4294967295] "" Vector__XXX
 SG_ Highest_sub_index_supported_1406 m0 : 32|8@1+ (1,0) [2|5] "" Vector__XXX
 SG_ SubIndex_1406 m5126M : 24|8@1+ (1,0) [0|2] "" Vector__XXX
 SG_ TransmissionType_1405_02 m2 : 32|8@1+ (1,0) [0|255] "" Vector__XXX
 SG_ COB_ID_1405_01 m1 : 32|32@1+ (1,0) [128|4294967295] "" Vector__XXX
 SG_ Highest_sub_index_supported_1405 m0 : 32|8@1+ (1,0) [2|5] "" Vector__XXX
 SG_ SubIndex_1405 m5125M : 24|8@1+ (1,0) [0|2] "" Vector__XXX
 SG_ TransmissionType_1404_02 m2 : 32|8@1+ (1,0) [0|255] "" Vector__XXX
 SG_ COB_ID_1404_01 m1 : 32|32@1+ (1,0) [128|4294967295] "" Vector__XXX
 SG_ Highest_sub_index_supported_0032 m0 : 32|8@1+ (1,0) [2|5] "" Vector__XXX
 SG_ SubIndex_1404 m5124M : 24|8@1+ (1,0) [0|2] "" Vector__XXX
 SG_ TransmissionType_1403_02 m2 : 32|8@1+ (1,0) [0|255] "" Vector__XXX
 SG_ COB_ID_1403_01 m1 : 32|32@1+ (1,0) [128|4294967295] "" Vector__XXX
 SG_ Highest_sub_index_supported_0033 m0 : 32|8@1+ (1,0) [2|5] "" Vector__XXX
 SG_ SubIndex_1403 m5123M : 24|8@1+ (1,0) [0|2] "" Vector__XXX
 SG_ TransmissionType_1402_02 m2 : 32|8@1+ (1,0) [0|255] "" Vector__XXX
 SG_ COB_ID_1402_01 m1 : 32|32@1+ (1,0) [128|4294967295] "" Vector__XXX
 SG_ Highest_sub_index_supported_0034 m0 : 32|8@1+ (1,0) [2|5] "" Vector__XXX
 SG_ SubIndex_1402 m5122M : 24|8@1+ (1,0) [0|2] "" Vector__XXX
 SG_ TransmissionType_1401_02 m2 : 32|8@1+ (1,0) [0|255] "" Vector__XXX
 SG_ COB_ID_1401_01 m1 : 32|32@1+ (1,0) [128|4294967295] "" Vector__XXX
 SG_ Highest_sub_index_supported_0035 m0 : 32|8@1+ (1,0) [2|5] "" Vector__XXX
 SG_ SubIndex_1401 m5121M : 24|8@1+ (1,0) [0|2] "" Vector__XXX
 SG_ TransmissionType_1400_02 m2 : 32|8@1+ (1,0) [0|255] "" Vector__XXX
 SG_ COB_ID_1400_01 m1 : 32|32@1+ (1,0) [128|4294967295] "" Vector__XXX
 SG_ Highest_sub_index_supported_0036 m0 : 32|8@1+ (1,0) [2|5] "" Vector__XXX
 SG_ SubIndex_1400 m5120M : 24|8@1+ (1,0) [0|2] "" Vector__XXX
 SG_ Serial_number_1018_04 m4 : 32|32@1+ (1,0) [0|4294967295] "" Vector__XXX
 SG_ Revision_number_1018_03 m3 : 32|32@1+ (1,0) [0|4294967295] "" Vector__XXX
 SG_ Product_Code_1018_02 m2 : 32|32@1+ (1,0) [0|4294967295] "" Vector__XXX
 SG_ Vendor_Id_1018_01 m1 : 32|32@1+ (1,0) [0|4294967295] "" Vector__XXX
 SG_ Highest_sub_index_supported_0037 m0 : 32|8@1+ (1,0) [1|4] "" Vector__XXX
 SG_ SubIndex_1018 m4120M : 24|8@1+ (1,0) [0|4] "" Vector__XXX
 SG_ Producer_Heartbeat_Time_1017 m0 : 32|16@1+ (1,0) [0|65535] "" Vector__XXX
 SG_ SubIndex_1017 m4119M : 24|8@1+ (1,0) [0|0] "" Vector__XXX
 SG_ Consumer_Heartbeat_Time_1016_7E m126 : 32|32@1+ (1,0) [0|4294967295] "" Vector__XXX
 SG_ Consumer_Heartbeat_Time_1016_7D m125 : 32|32@1+ (1,0) [0|4294967295] "" Vector__XXX
 SG_ Consumer_Heartbeat_Time_1016_7C m124 : 32|32@1+ (1,0) [0|4294967295] "" Vector__XXX
 SG_ Consumer_Heartbeat_Time_1016_7B m123 : 32|32@1+ (1,0) [0|4294967295] "" Vector__XXX
 SG_ Consumer_Heartbeat_Time_1016_7A m122 : 32|32@1+ (1,0) [0|4294967295] "" Vector__XXX
 SG_ Consumer_Heartbeat_Time_1016_79 m121 : 32|32@1+ (1,0) [0|4294967295] "" Vector__XXX
 SG_ Consumer_Heartbeat_Time_1016_78 m120 : 32|32@1+ (1,0) [0|4294967295] "" Vector__XXX
 SG_ Consumer_Heartbeat_Time_1016_77 m119 : 32|32@1+ (1,0) [0|4294967295] "" Vector__XXX
 SG_ Consumer_Heartbeat_Time_1016_76 m118 : 32|32@1+ (1,0) [0|4294967295] "" Vector__XXX
 SG_ Consumer_Heartbeat_Time_1016_75 m117 : 32|32@1+ (1,0) [0|4294967295] "" Vector__XXX
 SG_ Consumer_Heartbeat_Time_1016_74 m116 : 32|32@1+ (1,0) [0|4294967295] "" Vector__XXX
 SG_ Consumer_Heartbeat_Time_1016_73 m115 : 32|32@1+ (1,0) [0|4294967295] "" Vector__XXX
 SG_ Consumer_Heartbeat_Time_1016_72 m114 : 32|32@1+ (1,0) [0|4294967295] "" Vector__XXX
 SG_ Consumer_Heartbeat_Time_1016_71 m113 : 32|32@1+ (1,0) [0|4294967295] "" Vector__XXX
 SG_ Consumer_Heartbeat_Time_1016_70 m112 : 32|32@1+ (1,0) [0|4294967295] "" Vector__XXX
 SG_ Consumer_Heartbeat_Time_1016_6F m111 : 32|32@1+ (1,0) [0|4294967295] "" Vector__XXX
 SG_ Consumer_Heartbeat_Time_1016_6E m110 : 32|32@1+ (1,0) [0|4294967295] "" Vector__XXX
 SG_ Consumer_Heartbeat_Time_1016_6D m109 : 32|32@1+ (1,0) [0|4294967295] "" Vector__XXX
 SG_ Consumer_Heartbeat_Time_1016_6C m108 : 32|32@1+ (1,0) [0|4294967295] "" Vector__XXX
 SG_ Consumer_Heartbeat_Time_1016_6B m107 : 32|32@1+ (1,0) [0|4294967295] "" Vector__XXX
 SG_ Consumer_Heartbeat_Time_1016_6A m106 : 32|32@1+ (1,0) [0|4294967295] "" Vector__XXX
 SG_ Consumer_Heartbeat_Time_1016_69 m105 : 32|32@1+ (1,0) [0|4294967295] "" Vector__XXX
 SG_ Consumer_Heartbeat_Time_1016_68 m104 : 32|32@1+ (1,0) [0|4294967295] "" Vector__XXX
 SG_ Consumer_Heartbeat_Time_1016_67 m103 : 32|32@1+ (1,0) [0|4294967295] "" Vector__XXX
 SG_ Consumer_Heartbeat_Time_1016_66 m102 : 32|32@1+ (1,0) [0|4294967295] "" Vector__XXX
 SG_ Consumer_Heartbeat_Time_1016_65 m101 : 32|32@1+ (1,0) [0|4294967295] "" Vector__XXX
 SG_ Consumer_Heartbeat_Time_1016_64 m100 : 32|32@1+ (1,0) [0|4294967295] "" Vector__XXX
 SG_ Consumer_Heartbeat_Time_1016_63 m99 : 32|32@1+ (1,0) [0|4294967295] "" Vector__XXX
 SG_ Consumer_Heartbeat_Time_1016_62 m98 : 32|32@1+ (1,0) [0|4294967295] "" Vector__XXX
 SG_ Consumer_Heartbeat_Time_1016_61 m97 : 32|32@1+ (1,0) [0|4294967295] "" Vector__XXX
 SG_ Consumer_Heartbeat_Time_1016_60 m96 : 32|32@1+ (1,0) [0|4294967295] "" Vector__XXX
 SG_ Consumer_Heartbeat_Time_1016_5F m95 : 32|32@1+ (1,0) [0|4294967295] "" Vector__XXX
 SG_ Consumer_Heartbeat_Time_1016_5E m94 : 32|32@1+ (1,0) [0|4294967295] "" Vector__XXX
 SG_ Consumer_Heartbeat_Time_1016_5D m93 : 32|32@1+ (1,0) [0|4294967295] "" Vector__XXX
 SG_ Consumer_Heartbeat_Time_1016_5C m92 : 32|32@1+ (1,0) [0|4294967295] "" Vector__XXX
 SG_ Consumer_Heartbeat_Time_1016_5B m91 : 32|32@1+ (1,0) [0|4294967295] "" Vector__XXX
 SG_ Consumer_Heartbeat_Time_1016_5A m90 : 32|32@1+ (1,0) [0|4294967295] "" Vector__XXX
 SG_ Consumer_Heartbeat_Time_1016_59 m89 : 32|32@1+ (1,0) [0|4294967295] "" Vector__XXX
 SG_ Consumer_Heartbeat_Time_1016_58 m88 : 32|32@1+ (1,0) [0|4294967295] "" Vector__XXX
 SG_ Consumer_Heartbeat_Time_1016_57 m87 : 32|32@1+ (1,0) [0|4294967295] "" Vector__XXX
 SG_ Consumer_Heartbeat_Time_1016_56 m86 : 32|32@1+ (1,0) [0|4294967295] "" Vector__XXX
 SG_ Consumer_Heartbeat_Time_1016_55 m85 : 32|32@1+ (1,0) [0|4294967295] "" Vector__XXX
 SG_ Consumer_Heartbeat_Time_1016_54 m84 : 32|32@1+ (1,0) [0|4294967295] "" Vector__XXX
 SG_ Consumer_Heartbeat_Time_1016_53 m83 : 32|32@1+ (1,0) [0|4294967295] "" Vector__XXX
 SG_ Consumer_Heartbeat_Time_1016_52 m82 : 32|32@1+ (1,0) [0|4294967295] "" Vector__XXX
 SG_ Consumer_Heartbeat_Time_1016_51 m81 : 32|32@1+ (1,0) [0|4294967295] "" Vector__XXX
 SG_ Consumer_Heartbeat_Time_1016_50 m80 : 32|32@1+ (1,0) [0|4294967295] "" Vector__XXX
 SG_ Consumer_Heartbeat_Time_1016_4F m79 : 32|32@1+ (1,0) [0|4294967295] "" Vector__XXX
 SG_ Consumer_Heartbeat_Time_1016_4E m78 : 32|32@1+ (1,0) [0|4294967295] "" Vector__XXX
 SG_ Consumer_Heartbeat_Time_1016_4D m77 : 32|32@1+ (1,0) [0|4294967295] "" Vector__XXX
 SG_ Consumer_Heartbeat_Time_1016_4C m76 : 32|32@1+ (1,0) [0|4294967295] "" Vector__XXX
 SG_ Consumer_Heartbeat_Time_1016_4B m75 : 32|32@1+ (1,0) [0|4294967295] "" Vector__XXX
 SG_ Consumer_Heartbeat_Time_1016_4A m74 : 32|32@1+ (1,0) [0|4294967295] "" Vector__XXX
 SG_ Consumer_Heartbeat_Time_1016_49 m73 : 32|32@1+ (1,0) [0|4294967295] "" Vector__XXX
 SG_ Consumer_Heartbeat_Time_1016_48 m72 : 32|32@1+ (1,0) [0|4294967295] "" Vector__XXX
 SG_ Consumer_Heartbeat_Time_1016_47 m71 : 32|32@1+ (1,0) [0|4294967295] "" Vector__XXX
 SG_ Consumer_Heartbeat_Time_1016_46 m70 : 32|32@1+ (1,0) [0|4294967295] "" Vector__XXX
 SG_ Consumer_Heartbeat_Time_1016_45 m69 : 32|32@1+ (1,0) [0|4294967295] "" Vector__XXX
 SG_ Consumer_Heartbeat_Time_1016_44 m68 : 32|32@1+ (1,0) [0|4294967295] "" Vector__XXX
 SG_ Consumer_Heartbeat_Time_1016_43 m67 : 32|32@1+ (1,0) [0|4294967295] "" Vector__XXX
 SG_ Consumer_Heartbeat_Time_1016_42 m66 : 32|32@1+ (1,0) [0|4294967295] "" Vector__XXX
 SG_ Consumer_Heartbeat_Time_1016_41 m65 : 32|32@1+ (1,0) [0|4294967295] "" Vector__XXX
 SG_ Consumer_Heartbeat_Time_1016_40 m64 : 32|32@1+ (1,0) [0|4294967295] "" Vector__XXX
 SG_ Consumer_Heartbeat_Time_1016_3F m63 : 32|32@1+ (1,0) [0|4294967295] "" Vector__XXX
 SG_ Consumer_Heartbeat_Time_1016_3E m62 : 32|32@1+ (1,0) [0|4294967295] "" Vector__XXX
 SG_ Consumer_Heartbeat_Time_1016_3D m61 : 32|32@1+ (1,0) [0|4294967295] "" Vector__XXX
 SG_ Consumer_Heartbeat_Time_1016_3C m60 : 32|32@1+ (1,0) [0|4294967295] "" Vector__XXX
 SG_ Consumer_Heartbeat_Time_1016_3B m59 : 32|32@1+ (1,0) [0|4294967295] "" Vector__XXX
 SG_ Consumer_Heartbeat_Time_1016_3A m58 : 32|32@1+ (1,0) [0|4294967295] "" Vector__XXX
 SG_ Consumer_Heartbeat_Time_1016_39 m57 : 32|32@1+ (1,0) [0|4294967295] "" Vector__XXX
 SG_ Consumer_Heartbeat_Time_1016_38 m56 : 32|32@1+ (1,0) [0|4294967295] "" Vector__XXX
 SG_ Consumer_Heartbeat_Time_1016_37 m55 : 32|32@1+ (1,0) [0|4294967295] "" Vector__XXX
 SG_ Consumer_Heartbeat_Time_1016_36 m54 : 32|32@1+ (1,0) [0|4294967295] "" Vector__XXX
 SG_ Consumer_Heartbeat_Time_1016_35 m53 : 32|32@1+ (1,0) [0|4294967295] "" Vector__XXX
 SG_ Consumer_Heartbeat_Time_1016_34 m52 : 32|32@1+ (1,0) [0|4294967295] "" Vector__XXX
 SG_ Consumer_Heartbeat_Time_1016_33 m51 : 32|32@1+ (1,0) [0|4294967295] "" Vector__XXX
 SG_ Consumer_Heartbeat_Time_1016_32 m50 : 32|32@1+ (1,0) [0|4294967295] "" Vector__XXX
 SG_ Consumer_Heartbeat_Time_1016_31 m49 : 32|32@1+ (1,0) [0|4294967295] "" Vector__XXX
 SG_ Consumer_Heartbeat_Time_1016_30 m48 : 32|32@1+ (1,0) [0|4294967295] "" Vector__XXX
 SG_ Consumer_Heartbeat_Time_1016_2F m47 : 32|32@1+ (1,0) [0|4294967295] "" Vector__XXX
 SG_ Consumer_Heartbeat_Time_1016_2E m46 : 32|32@1+ (1,0) [0|4294967295] "" Vector__XXX
 SG_ Consumer_Heartbeat_Time_1016_2D m45 : 32|32@1+ (1,0) [0|4294967295] "" Vector__XXX
 SG_ Consumer_Heartbeat_Time_1016_2C m44 : 32|32@1+ (1,0) [0|4294967295] "" Vector__XXX
 SG_ Consumer_Heartbeat_Time_1016_2B m43 : 32|32@1+ (1,0) [0|4294967295] "" Vector__XXX
 SG_ Consumer_Heartbeat_Time_1016_2A m42 : 32|32@1+ (1,0) [0|4294967295] "" Vector__XXX
 SG_ Consumer_Heartbeat_Time_1016_29 m41 : 32|32@1+ (1,0) [0|4294967295] "" Vector__XXX
 SG_ Consumer_Heartbeat_Time_1016_28 m40 : 32|32@1+ (1,0) [0|4294967295] "" Vector__XXX
 SG_ Consumer_Heartbeat_Time_1016_27 m39 : 32|32@1+ (1,0) [0|4294967295] "" Vector__XXX
 SG_ Consumer_Heartbeat_Time_1016_26 m38 : 32|32@1+ (1,0) [0|4294967295] "" Vector__XXX
 SG_ Consumer_Heartbeat_Time_1016_25 m37 : 32|32@1+ (1,0) [0|4294967295] "" Vector__XXX
 SG_ Consumer_Heartbeat_Time_1016_24 m36 : 32|32@1+ (1,0) [0|4294967295] "" Vector__XXX
 SG_ Consumer_Heartbeat_Time_1016_23 m35 : 32|32@1+ (1,0) [0|4294967295] "" Vector__XXX
 SG_ Consumer_Heartbeat_Time_1016_22 m34 : 32|32@1+ (1,0) [0|4294967295] "" Vector__XXX
 SG_ Consumer_Heartbeat_Time_1016_21 m33 : 32|32@1+ (1,0) [0|4294967295] "" Vector__XXX
 SG_ Consumer_Heartbeat_Time_1016_20 m32 : 32|32@1+ (1,0) [0|4294967295] "" Vector__XXX
 SG_ Consumer_Heartbeat_Time_1016_1F m31 : 32|32@1+ (1,0) [0|4294967295] "" Vector__XXX
 SG_ Consumer_Heartbeat_Time_1016_1E m30 : 32|32@1+ (1,0) [0|4294967295] "" Vector__XXX
 SG_ Consumer_Heartbeat_Time_1016_1D m29 : 32|32@1+ (1,0) [0|4294967295] "" Vector__XXX
 SG_ Consumer_Heartbeat_Time_1016_1C m28 : 32|32@1+ (1,0) [0|4294967295] "" Vector__XXX
 SG_ Consumer_Heartbeat_Time_1016_1B m27 : 32|32@1+ (1,0) [0|4294967295] "" Vector__XXX
 SG_ Consumer_Heartbeat_Time_1016_1A m26 : 32|32@1+ (1,0) [0|4294967295] "" Vector__XXX
 SG_ Consumer_Heartbeat_Time_1016_19 m25 : 32|32@1+ (1,0) [0|4294967295] "" Vector__XXX
 SG_ Consumer_Heartbeat_Time_1016_18 m24 : 32|32@1+ (1,0) [0|4294967295] "" Vector__XXX
 SG_ Consumer_Heartbeat_Time_1016_17 m23 : 32|32@1+ (1,0) [0|4294967295] "" Vector__XXX
 SG_ Consumer_Heartbeat_Time_1016_16 m22 : 32|32@1+ (1,0) [0|4294967295] "" Vector__XXX
 SG_ Consumer_Heartbeat_Time_1016_15 m21 : 32|32@1+ (1,0) [0|4294967295] "" Vector__XXX
 SG_ Consumer_Heartbeat_Time_1016_14 m20 : 32|32@1+ (1,0) [0|4294967295] "" Vector__XXX
 SG_ Consumer_Heartbeat_Time_1016_13 m19 : 32|32@1+ (1,0) [0|4294967295] "" Vector__XXX
 SG_ Consumer_Heartbeat_Time_1016_12 m18 : 32|32@1+ (1,0) [0|4294967295] "" Vector__XXX
 SG_ Consumer_Heartbeat_Time_1016_11 m17 : 32|32@1+ (1,0) [0|4294967295] "" Vector__XXX
 SG_ Consumer_Heartbeat_Time_1016_10 m16 : 32|32@1+ (1,0) [0|4294967295] "" Vector__XXX
 SG_ Consumer_Heartbeat_Time_1016_0F m15 : 32|32@1+ (1,0) [0|4294967295] "" Vector__XXX
 SG_ Consumer_Heartbeat_Time_1016_0E m14 : 32|32@1+ (1,0) [0|4294967295] "" Vector__XXX
 SG_ Consumer_Heartbeat_Time_1016_0D m13 : 32|32@1+ (1,0) [0|4294967295] "" Vector__XXX
 SG_ Consumer_Heartbeat_Time_1016_0C m12 : 32|32@1+ (1,0) [0|4294967295] "" Vector__XXX
 SG_ Consumer_Heartbeat_Time_1016_0B m11 : 32|32@1+ (1,0) [0|4294967295] "" Vector__XXX
 SG_ Consumer_Heartbeat_Time_1016_0A m10 : 32|32@1+ (1,0) [0|4294967295] "" Vector__XXX
 SG_ Consumer_Heartbeat_Time_1016_09 m9 : 32|32@1+ (1,0) [0|4294967295] "" Vector__XXX
 SG_ Consumer_Heartbeat_Time_1016_08 m8 : 32|32@1+ (1,0) [0|4294967295] "" Vector__XXX
 SG_ Consumer_Heartbeat_Time_1016_07 m7 : 32|32@1+ (1,0) [0|4294967295] "" Vector__XXX
 SG_ Consumer_Heartbeat_Time_1016_06 m6 : 32|32@1+ (1,0) [0|4294967295] "" Vector__XXX
 SG_ Consumer_Heartbeat_Time_1016_05 m5 : 32|32@1+ (1,0) [0|4294967295] "" Vector__XXX
 SG_ Consumer_Heartbeat_Time_1016_04 m4 : 32|32@1+ (1,0) [0|4294967295] "" Vector__XXX
 SG_ Consumer_Heartbeat_Time_1016_03 m3 : 32|32@1+ (1,0) [0|4294967295] "" Vector__XXX
 SG_ Consumer_Heartbeat_Time_1016_02 m2 : 32|32@1+ (1,0) [0|4294967295] "" Vector__XXX
 SG_ Consumer_Heartbeat_Time_1016_01 m1 : 32|32@1+ (1,0) [0|4294967295] "" Vector__XXX
 SG_ NrOfObjects_1016_00 m0 : 32|8@1+ (1,0) [0|255] "" Vector__XXX
 SG_ SubIndex_1016 m4118M : 24|8@1+ (1,0) [0|126] "" Vector__XXX
 SG_ Save_all_Parameters_1010_01 m1 : 32|32@1+ (1,0) [0|4294967295] "" Vector__XXX
 SG_ Highest_sub_index_supported_0038 m0 : 32|8@1+ (1,0) [0|255] "" Vector__XXX
 SG_ SubIndex_1010 m4112M : 24|8@1+ (1,0) [0|1] "" Vector__XXX
 SG_ Life_Time_Factor_100D m0 : 32|8@1+ (1,0) [0|255] "" Vector__XXX
 SG_ SubIndex_100D m4109M : 24|8@1+ (1,0) [0|0] "" Vector__XXX
 SG_ Guard_Time_100C m0 : 32|16@1+ (1,0) [0|65535] "" Vector__XXX
 SG_ SubIndex_100C m4108M : 24|8@1+ (1,0) [0|0] "" Vector__XXX
 SG_ Sync_Window_Length_1007 m0 : 32|32@1+ (1,0) [0|4294967295] "" Vector__XXX
 SG_ SubIndex_1007 m4103M : 24|8@1+ (1,0) [0|0] "" Vector__XXX
 SG_ Communication_Cycle_Period_1006 m0 : 32|32@1+ (1,0) [0|4294967295] "" Vector__XXX
 SG_ SubIndex_1006 m4102M : 24|8@1+ (1,0) [0|0] "" Vector__XXX
 SG_ COB_ID_SYNC_1005 m0 : 32|32@1+ (1,0) [128|4294967295] "" Vector__XXX
 SG_ SubIndex_1005 m4101M : 24|8@1+ (1,0) [0|0] "" Vector__XXX
 SG_ Manufacturer_Status_Registe_0001 m0 : 32|32@1+ (1,0) [0|4294967295] "" Vector__XXX
 SG_ SubIndex_1002 m4098M : 24|8@1+ (1,0) [0|0] "" Vector__XXX
 SG_ Error_Register_1001 m0 : 32|8@1+ (1,0) [0|255] "" Vector__XXX
 SG_ SubIndex_1001 m4097M : 24|8@1+ (1,0) [0|0] "" Vector__XXX
 SG_ Device_Type_1000 m0 : 32|32@1+ (1,0) [0|4294967295] "" Vector__XXX
 SG_ SubIndex_1000 m4096M : 24|8@1+ (1,0) [0|0] "" Vector__XXX
 SG_ Index m1M : 8|16@1+ (1,0) [4096|25861] "" Vector__XXX
 SG_ TransferType m1M : 1|1@1+ (1,0) [0|1] "" Vector__XXX
 SG_ NotUsedBytes m1 : 2|2@1+ (1,0) [0|3] "" Vector__XXX
 SG_ SizeIndicator m1 : 0|1@1+ (1,0) [0|1] "" Vector__XXX
 SG_ SCS M : 5|3@1+ (1,0) [0|6] "" Vector__XXX

BA_DEF_ BO_  "GenMsgSendType" ENUM  "Cyclic","SendType1","SendType2","SendType3","SendType4","SendType5","SendType6","SendType7","SendType8","SendType9";
BA_DEF_ BO_  "GenMsgCycleTime" INT 0 0;
BA_DEF_ SG_  "GenSigStartValue" INT 0 0;
BA_DEF_ BO_  "CO_MsgCategory" INT 0 0;
BA_DEF_ SG_  "SystemSignalLongSymbol" STRING ;
BA_DEF_DEF_  "GenMsgSendType" "";
BA_DEF_DEF_  "GenMsgCycleTime" 0;
BA_DEF_DEF_  "GenSigStartValue" 0;
BA_DEF_DEF_  "CO_MsgCategory" 0;
BA_DEF_DEF_  "SystemSignalLongSymbol" "";
BA_ "CO_MsgCategory" BO_ 129 205;
BA_ "GenMsgSendType" BO_ 1804 0;
BA_ "GenMsgCycleTime" BO_ 1804 500;
BA_ "CO_MsgCategory" BO_ 1804 505;
BA_ "CO_MsgCategory" BO_ 1420 410;
BA_ "GenSigStartValue" SG_ 1537 Highest_sub_index_supported_0013 128;
BA_ "SystemSignalLongSymbol" SG_ 1537 Highest_sub_index_supported_0013 "Highest_sub_index_supported_1F82_00";
BA_ "GenSigStartValue" SG_ 1537 SlaveAssignment_1F81_0D 13;
BA_ "GenSigStartValue" SG_ 1537 SlaveAssignment_1F81_0C 13;
BA_ "GenSigStartValue" SG_ 1537 SlaveAssignment_1F81_0B 13;
BA_ "GenSigStartValue" SG_ 1537 SlaveAssignment_1F81_0A 13;
BA_ "GenSigStartValue" SG_ 1537 SlaveAssignment_1F81_02 9;
BA_ "GenSigStartValue" SG_ 1537 NrOfObjects_1F81_00 127;
BA_ "GenSigStartValue" SG_ 1537 NMTStartup_1F80 3;
BA_ "GenSigStartValue" SG_ 1537 NrOfObjects_1F25_00 128;
BA_ "GenSigStartValue" SG_ 1537 NrOfObjects_1F22_00 127;
BA_ "GenSigStartValue" SG_ 1537 GENERATED_1A04_03 2696938512;
BA_ "GenSigStartValue" SG_ 1537 GENERATED_1A04_02 2688549896;
BA_ "GenSigStartValue" SG_ 1537 GENERATED_1A04_01 2688549640;
BA_ "GenSigStartValue" SG_ 1537 NrOfMappedObjects_1A04_00 3;
BA_ "GenSigStartValue" SG_ 1537 GENERATED_1A03_03 2688549384;
BA_ "GenSigStartValue" SG_ 1537 mappedObj2_1A03_02 2688551176;
BA_ "GenSigStartValue" SG_ 1537 mappedObj1_1A03_01 2688549128;
BA_ "GenSigStartValue" SG_ 1537 NrOfMappedObjects_1A03_00 3;
BA_ "GenSigStartValue" SG_ 1537 mappedObj2_1A02_02 2701132560;
BA_ "GenSigStartValue" SG_ 1537 mappedObj1_1A02_01 2696938256;
BA_ "GenSigStartValue" SG_ 1537 NrOfMappedObjects_1A02_00 2;
BA_ "GenSigStartValue" SG_ 1537 mappedObj2_1A01_02 2701132304;
BA_ "GenSigStartValue" SG_ 1537 mappedObj1_1A01_01 2696938000;
BA_ "GenSigStartValue" SG_ 1537 NrOfMappedObjects_1A01_00 2;
BA_ "GenSigStartValue" SG_ 1537 mappedObj2_1A00_02 2701132048;
BA_ "GenSigStartValue" SG_ 1537 mappedObj1_1A00_01 2696937744;
BA_ "GenSigStartValue" SG_ 1537 NrOfMappedObjects_1A00_00 2;
BA_ "GenSigStartValue" SG_ 1537 TransmissionType_1804_02 255;
BA_ "GenSigStartValue" SG_ 1537 COB_ID_1804_01 1320;
BA_ "GenSigStartValue" SG_ 1537 Highest_sub_index_supported_0014 5;
BA_ "SystemSignalLongSymbol" SG_ 1537 Highest_sub_index_supported_0014 "Highest_sub_index_supported_1804_00";
BA_ "GenSigStartValue" SG_ 1537 EventTimer_1803_05 1000;
BA_ "GenSigStartValue" SG_ 1537 TransmissionType_1803_02 255;
BA_ "GenSigStartValue" SG_ 1537 COB_ID_1803_01 1153;
BA_ "GenSigStartValue" SG_ 1537 Highest_sub_index_supported_0015 5;
BA_ "SystemSignalLongSymbol" SG_ 1537 Highest_sub_index_supported_0015 "Highest_sub_index_supported_1803_00";
BA_ "GenSigStartValue" SG_ 1537 TransmissionType_1802_02 255;
BA_ "GenSigStartValue" SG_ 1537 COB_ID_1802_01 897;
BA_ "GenSigStartValue" SG_ 1537 Highest_sub_index_supported_0016 5;
BA_ "SystemSignalLongSymbol" SG_ 1537 Highest_sub_index_supported_0016 "Highest_sub_index_supported_1802_00";
BA_ "GenSigStartValue" SG_ 1537 TransmissionType_1801_02 255;
BA_ "GenSigStartValue" SG_ 1537 COB_ID_1801_01 641;
BA_ "GenSigStartValue" SG_ 1537 Highest_sub_index_supported_0017 5;
BA_ "SystemSignalLongSymbol" SG_ 1537 Highest_sub_index_supported_0017 "Highest_sub_index_supported_1801_00";
BA_ "GenSigStartValue" SG_ 1537 TransmissionType_1800_02 255;
BA_ "GenSigStartValue" SG_ 1537 COB_ID_1800_01 385;
BA_ "GenSigStartValue" SG_ 1537 Highest_sub_index_supported_0018 5;
BA_ "SystemSignalLongSymbol" SG_ 1537 Highest_sub_index_supported_0018 "Highest_sub_index_supported_1800_00";
BA_ "GenSigStartValue" SG_ 1537 GENERATED_1604_05 2776631056;
BA_ "GenSigStartValue" SG_ 1537 GENERATED_1604_04 2776630800;
BA_ "GenSigStartValue" SG_ 1537 GENERATED_1604_03 2764047880;
BA_ "GenSigStartValue" SG_ 1537 GENERATED_1604_02 2764047624;
BA_ "GenSigStartValue" SG_ 1537 GENERATED_1604_01 2759853576;
BA_ "GenSigStartValue" SG_ 1537 NrOfMappedObjects_1604_00 5;
BA_ "GenSigStartValue" SG_ 1537 mappedObj2_1603_02 2772435216;
BA_ "GenSigStartValue" SG_ 1537 mappedObj1_1603_01 2776630032;
BA_ "GenSigStartValue" SG_ 1537 NrOfMappedObjects_1603_00 3;
BA_ "GenSigStartValue" SG_ 1537 mappedObj2_1602_02 2789212704;
BA_ "GenSigStartValue" SG_ 1537 mappedObj1_1602_01 2776629776;
BA_ "GenSigStartValue" SG_ 1537 NrOfMappedObjects_1602_00 2;
BA_ "GenSigStartValue" SG_ 1537 GENERATED_1601_03 2789212448;
BA_ "GenSigStartValue" SG_ 1537 mappedObj2_1601_02 2772435216;
BA_ "GenSigStartValue" SG_ 1537 mappedObj1_1601_01 2776629520;
BA_ "GenSigStartValue" SG_ 1537 NrOfMappedObjects_1601_00 3;
BA_ "GenSigStartValue" SG_ 1537 GENERATED_1600_05 2764047368;
BA_ "GenSigStartValue" SG_ 1537 mappedObj4_1600_04 2764047112;
BA_ "GenSigStartValue" SG_ 1537 mappedObj3_1600_03 2764046856;
BA_ "GenSigStartValue" SG_ 1537 mappedObj2_1600_02 2764048648;
BA_ "GenSigStartValue" SG_ 1537 mappedObj1_1600_01 2764046600;
BA_ "GenSigStartValue" SG_ 1537 NrOfMappedObjects_1600_00 5;
BA_ "GenSigStartValue" SG_ 1537 TransmissionType_1404_02 255;
BA_ "GenSigStartValue" SG_ 1537 COB_ID_1404_01 662;
BA_ "GenSigStartValue" SG_ 1537 Highest_sub_index_supported_0019 2;
BA_ "SystemSignalLongSymbol" SG_ 1537 Highest_sub_index_supported_0019 "Highest_sub_index_supported_1404_00";
BA_ "GenSigStartValue" SG_ 1537 TransmissionType_1403_02 255;
BA_ "GenSigStartValue" SG_ 1537 COB_ID_1403_01 653;
BA_ "GenSigStartValue" SG_ 1537 Highest_sub_index_supported_0020 2;
BA_ "SystemSignalLongSymbol" SG_ 1537 Highest_sub_index_supported_0020 "Highest_sub_index_supported_1403_00";
BA_ "GenSigStartValue" SG_ 1537 TransmissionType_1402_02 255;
BA_ "GenSigStartValue" SG_ 1537 COB_ID_1402_01 652;
BA_ "GenSigStartValue" SG_ 1537 Highest_sub_index_supported_0021 2;
BA_ "SystemSignalLongSymbol" SG_ 1537 Highest_sub_index_supported_0021 "Highest_sub_index_supported_1402_00";
BA_ "GenSigStartValue" SG_ 1537 TransmissionType_1401_02 255;
BA_ "GenSigStartValue" SG_ 1537 COB_ID_1401_01 651;
BA_ "GenSigStartValue" SG_ 1537 Highest_sub_index_supported_0022 2;
BA_ "SystemSignalLongSymbol" SG_ 1537 Highest_sub_index_supported_0022 "Highest_sub_index_supported_1401_00";
BA_ "GenSigStartValue" SG_ 1537 TransmissionType_1400_02 255;
BA_ "GenSigStartValue" SG_ 1537 COB_ID_1400_01 394;
BA_ "GenSigStartValue" SG_ 1537 Highest_sub_index_supported_0023 2;
BA_ "SystemSignalLongSymbol" SG_ 1537 Highest_sub_index_supported_0023 "Highest_sub_index_supported_1400_00";
BA_ "GenSigStartValue" SG_ 1537 NrOfObjects_1020_00 2;
BA_ "GenSigStartValue" SG_ 1537 Revision_number_1018_03 1;
BA_ "GenSigStartValue" SG_ 1537 Product_Code_1018_02 3213;
BA_ "GenSigStartValue" SG_ 1537 Highest_sub_index_supported_0024 4;
BA_ "SystemSignalLongSymbol" SG_ 1537 Highest_sub_index_supported_0024 "Highest_sub_index_supported_1018_00";
BA_ "GenSigStartValue" SG_ 1537 Producer_Heartbeat_Time_1017 500;
BA_ "GenSigStartValue" SG_ 1537 Consumer_Heartbeat_Time_1016_04 852968;
BA_ "GenSigStartValue" SG_ 1537 Consumer_Heartbeat_Time_1016_03 787432;
BA_ "GenSigStartValue" SG_ 1537 Consumer_Heartbeat_Time_1016_02 721896;
BA_ "GenSigStartValue" SG_ 1537 Consumer_Heartbeat_Time_1016_01 656360;
BA_ "GenSigStartValue" SG_ 1537 NrOfObjects_1016_00 126;
BA_ "SystemSignalLongSymbol" SG_ 1537 Restore_all_Default_Paramet_0000 "Restore_all_Default_Parameters_1011_01";
BA_ "GenSigStartValue" SG_ 1537 Highest_sub_index_supported_0025 1;
BA_ "SystemSignalLongSymbol" SG_ 1537 Highest_sub_index_supported_0025 "Highest_sub_index_supported_1011_00";
BA_ "GenSigStartValue" SG_ 1537 Highest_sub_index_supported_0026 1;
BA_ "SystemSignalLongSymbol" SG_ 1537 Highest_sub_index_supported_0026 "Highest_sub_index_supported_1010_00";
BA_ "GenSigStartValue" SG_ 1537 Sync_Window_Length_1007 100;
BA_ "GenSigStartValue" SG_ 1537 Communication_Cycle_Period_1006 200000;
BA_ "GenSigStartValue" SG_ 1537 COB_ID_SYNC_1005 1073741952;
BA_ "SystemSignalLongSymbol" SG_ 1537 Manufacturer_Status_Registe_0000 "Manufacturer_Status_Register_1002";
BA_ "GenSigStartValue" SG_ 1537 Device_Type_1000 405;
BA_ "GenSigStartValue" SG_ 1537 Index 4096;
BA_ "GenSigStartValue" SG_ 1420 supported_drive_modes_6502 2;
BA_ "GenSigStartValue" SG_ 1420 motor_service_period_6407 1000;
BA_ "GenSigStartValue" SG_ 1420 digital_outputs_highest_subindex 2;
BA_ "SystemSignalLongSymbol" SG_ 1420 digital_outputs_highest_subindex "digital_outputs_highest_subindex_60FE_00";
BA_ "SystemSignalLongSymbol" SG_ 1420 position_actual_internal_value_6 "position_actual_internal_value_6063";
BA_ "SystemSignalLongSymbol" SG_ 1420 disable_operation_option_code_60 "disable_operation_option_code_605C";
BA_ "GenSigStartValue" SG_ 1420 delta_time_6049_02 1;
BA_ "GenSigStartValue" SG_ 1420 delta_speed_6049_01 1000;
BA_ "GenSigStartValue" SG_ 1420 NrOfObjects_6049_00 2;
BA_ "GenSigStartValue" SG_ 1420 delta_time_6048_02 1;
BA_ "GenSigStartValue" SG_ 1420 delta_speed_6048_01 500;
BA_ "GenSigStartValue" SG_ 1420 NrOfObjects_6048_00 2;
BA_ "GenSigStartValue" SG_ 1420 vl_velocity_max_amount_6046_02 1000;
BA_ "GenSigStartValue" SG_ 1420 vl_velocity_min_max_amount_highe 2;
BA_ "SystemSignalLongSymbol" SG_ 1420 vl_velocity_min_max_amount_highe "vl_velocity_min_max_amount_highest_subindex_6046_00";
BA_ "GenSigStartValue" SG_ 1420 statusword_6041 39;
BA_ "GenSigStartValue" SG_ 1420 controlword_6040 43;
BA_ "SystemSignalLongSymbol" SG_ 1420 abort_connection_option_code_600 "abort_connection_option_code_6007";
BA_ "GenSigStartValue" SG_ 1420 PDO_Mapping_Entry_1A06_02 1627193376;
BA_ "GenSigStartValue" SG_ 1420 PDO_Mapping_Entry_1A06_01 1614872592;
BA_ "GenSigStartValue" SG_ 1420 PDO_Mapping_Entry_1A05_02 1615069200;
BA_ "GenSigStartValue" SG_ 1420 PDO_Mapping_Entry_1A05_01 1614872592;
BA_ "GenSigStartValue" SG_ 1420 PDO_Mapping_Entry_1A04_02 1618411536;
BA_ "GenSigStartValue" SG_ 1420 PDO_Mapping_Entry_1A04_01 1614872592;
BA_ "GenSigStartValue" SG_ 1420 PDO_Mapping_Entry_1A03_02 1617690656;
BA_ "GenSigStartValue" SG_ 1420 PDO_Mapping_Entry_1A03_01 1614872592;
BA_ "GenSigStartValue" SG_ 1420 mappedObj2_1A02_02 1617166368;
BA_ "GenSigStartValue" SG_ 1420 mappedObj1_1A02_01 1614872592;
BA_ "GenSigStartValue" SG_ 1420 mappedObj2_1A01_02 1617166368;
BA_ "GenSigStartValue" SG_ 1420 mappedObj1_1A01_01 1614872592;
BA_ "GenSigStartValue" SG_ 1420 NrOfMappedObjects_1A01_00 2;
BA_ "GenSigStartValue" SG_ 1420 mappedObj1_1A00_01 1617166368;
BA_ "GenSigStartValue" SG_ 1420 NrOfMappedObjects_1A00_00 1;
BA_ "GenSigStartValue" SG_ 1420 TransmissionType_1806_02 255;
BA_ "GenSigStartValue" SG_ 1420 COB_ID_1806_01 2147484966;
BA_ "GenSigStartValue" SG_ 1420 Highest_sub_index_supported_1806 5;
BA_ "SystemSignalLongSymbol" SG_ 1420 Highest_sub_index_supported_1806 "Highest_sub_index_supported_1806_00";
BA_ "GenSigStartValue" SG_ 1420 TransmissionType_1805_02 255;
BA_ "GenSigStartValue" SG_ 1420 COB_ID_1805_01 2147484967;
BA_ "GenSigStartValue" SG_ 1420 Highest_sub_index_supported_1805 5;
BA_ "SystemSignalLongSymbol" SG_ 1420 Highest_sub_index_supported_1805 "Highest_sub_index_supported_1805_00";
BA_ "GenSigStartValue" SG_ 1420 TransmissionType_1804_02 255;
BA_ "GenSigStartValue" SG_ 1420 COB_ID_1804_01 2147484968;
BA_ "GenSigStartValue" SG_ 1420 Highest_sub_index_supported_0027 5;
BA_ "SystemSignalLongSymbol" SG_ 1420 Highest_sub_index_supported_0027 "Highest_sub_index_supported_1804_00";
BA_ "GenSigStartValue" SG_ 1420 TransmissionType_1803_02 255;
BA_ "GenSigStartValue" SG_ 1420 COB_ID_1803_01 2147484812;
BA_ "GenSigStartValue" SG_ 1420 Highest_sub_index_supported_0028 5;
BA_ "SystemSignalLongSymbol" SG_ 1420 Highest_sub_index_supported_0028 "Highest_sub_index_supported_1803_00";
BA_ "GenSigStartValue" SG_ 1420 TransmissionType_1802_02 255;
BA_ "GenSigStartValue" SG_ 1420 COB_ID_1802_01 2147484556;
BA_ "GenSigStartValue" SG_ 1420 Highest_sub_index_supported_0029 5;
BA_ "SystemSignalLongSymbol" SG_ 1420 Highest_sub_index_supported_0029 "Highest_sub_index_supported_1802_00";
BA_ "GenSigStartValue" SG_ 1420 TransmissionType_1801_02 255;
BA_ "GenSigStartValue" SG_ 1420 COB_ID_1801_01 652;
BA_ "GenSigStartValue" SG_ 1420 Highest_sub_index_supported_0030 5;
BA_ "SystemSignalLongSymbol" SG_ 1420 Highest_sub_index_supported_0030 "Highest_sub_index_supported_1801_00";
BA_ "GenSigStartValue" SG_ 1420 TransmissionType_1800_02 1;
BA_ "GenSigStartValue" SG_ 1420 COB_ID_1800_01 396;
BA_ "GenSigStartValue" SG_ 1420 Highest_sub_index_supported_0031 5;
BA_ "SystemSignalLongSymbol" SG_ 1420 Highest_sub_index_supported_0031 "Highest_sub_index_supported_1800_00";
BA_ "GenSigStartValue" SG_ 1420 PDO_Mapping_Entry_1607_02 1616904200;
BA_ "GenSigStartValue" SG_ 1420 PDO_Mapping_Entry_1607_01 1614807056;
BA_ "GenSigStartValue" SG_ 1420 PDO_Mapping_Entry_1606_02 1627259168;
BA_ "GenSigStartValue" SG_ 1420 PDO_Mapping_Entry_1606_01 1614807056;
BA_ "GenSigStartValue" SG_ 1420 PDO_Mapping_Entry_1605_02 1614938128;
BA_ "GenSigStartValue" SG_ 1420 PDO_Mapping_Entry_1605_01 1614807056;
BA_ "GenSigStartValue" SG_ 1420 PDO_Mapping_Entry_1604_02 1618018320;
BA_ "GenSigStartValue" SG_ 1420 PDO_Mapping_Entry_1604_01 1614807056;
BA_ "GenSigStartValue" SG_ 1420 PDO_Mapping_Entry_1603_02 1627324448;
BA_ "GenSigStartValue" SG_ 1420 PDO_Mapping_Entry_1603_01 1614807056;
BA_ "GenSigStartValue" SG_ 1420 PDO_Mapping_Entry_1602_02 1618608160;
BA_ "GenSigStartValue" SG_ 1420 PDO_Mapping_Entry_1602_01 1614807056;
BA_ "GenSigStartValue" SG_ 1420 PDO_Mapping_Entry_1601_02 1616904200;
BA_ "GenSigStartValue" SG_ 1420 PDO_Mapping_Entry_1601_01 1614807056;
BA_ "GenSigStartValue" SG_ 1420 mappedObj2_1600_02 1614807056;
BA_ "GenSigStartValue" SG_ 1420 mappedObj1_1600_01 1614938128;
BA_ "GenSigStartValue" SG_ 1420 NrOfMappedObjects_1600_00 2;
BA_ "GenSigStartValue" SG_ 1420 TransmissionType_1407_02 255;
BA_ "GenSigStartValue" SG_ 1420 COB_ID_1407_01 2147484962;
BA_ "GenSigStartValue" SG_ 1420 Highest_sub_index_supported_1407 2;
BA_ "SystemSignalLongSymbol" SG_ 1420 Highest_sub_index_supported_1407 "Highest_sub_index_supported_1407_00";
BA_ "GenSigStartValue" SG_ 1420 TransmissionType_1406_02 255;
BA_ "GenSigStartValue" SG_ 1420 COB_ID_1406_01 2147484963;
BA_ "GenSigStartValue" SG_ 1420 Highest_sub_index_supported_1406 2;
BA_ "SystemSignalLongSymbol" SG_ 1420 Highest_sub_index_supported_1406 "Highest_sub_index_supported_1406_00";
BA_ "GenSigStartValue" SG_ 1420 TransmissionType_1405_02 255;
BA_ "GenSigStartValue" SG_ 1420 COB_ID_1405_01 2147484964;
BA_ "GenSigStartValue" SG_ 1420 Highest_sub_index_supported_1405 2;
BA_ "SystemSignalLongSymbol" SG_ 1420 Highest_sub_index_supported_1405 "Highest_sub_index_supported_1405_00";
BA_ "GenSigStartValue" SG_ 1420 TransmissionType_1404_02 255;
BA_ "GenSigStartValue" SG_ 1420 COB_ID_1404_01 2147484965;
BA_ "GenSigStartValue" SG_ 1420 Highest_sub_index_supported_0032 2;
BA_ "SystemSignalLongSymbol" SG_ 1420 Highest_sub_index_supported_0032 "Highest_sub_index_supported_1404_00";
BA_ "GenSigStartValue" SG_ 1420 TransmissionType_1403_02 255;
BA_ "GenSigStartValue" SG_ 1420 COB_ID_1403_01 2147484940;
BA_ "GenSigStartValue" SG_ 1420 Highest_sub_index_supported_0033 2;
BA_ "SystemSignalLongSymbol" SG_ 1420 Highest_sub_index_supported_0033 "Highest_sub_index_supported_1403_00";
BA_ "GenSigStartValue" SG_ 1420 TransmissionType_1402_02 255;
BA_ "GenSigStartValue" SG_ 1420 COB_ID_1402_01 2147484684;
BA_ "GenSigStartValue" SG_ 1420 Highest_sub_index_supported_0034 2;
BA_ "SystemSignalLongSymbol" SG_ 1420 Highest_sub_index_supported_0034 "Highest_sub_index_supported_1402_00";
BA_ "GenSigStartValue" SG_ 1420 TransmissionType_1401_02 255;
BA_ "GenSigStartValue" SG_ 1420 COB_ID_1401_01 2147484428;
BA_ "GenSigStartValue" SG_ 1420 Highest_sub_index_supported_0035 2;
BA_ "SystemSignalLongSymbol" SG_ 1420 Highest_sub_index_supported_0035 "Highest_sub_index_supported_1401_00";
BA_ "GenSigStartValue" SG_ 1420 TransmissionType_1400_02 255;
BA_ "GenSigStartValue" SG_ 1420 COB_ID_1400_01 641;
BA_ "GenSigStartValue" SG_ 1420 Highest_sub_index_supported_0036 2;
BA_ "SystemSignalLongSymbol" SG_ 1420 Highest_sub_index_supported_0036 "Highest_sub_index_supported_1400_00";
BA_ "GenSigStartValue" SG_ 1420 Serial_number_1018_04 1;
BA_ "GenSigStartValue" SG_ 1420 Revision_number_1018_03 1;
BA_ "GenSigStartValue" SG_ 1420 Product_Code_1018_02 14789;
BA_ "GenSigStartValue" SG_ 1420 Vendor_Id_1018_01 5;
BA_ "GenSigStartValue" SG_ 1420 Highest_sub_index_supported_0037 4;
BA_ "SystemSignalLongSymbol" SG_ 1420 Highest_sub_index_supported_0037 "Highest_sub_index_supported_1018_00";
BA_ "GenSigStartValue" SG_ 1420 Producer_Heartbeat_Time_1017 500;
BA_ "GenSigStartValue" SG_ 1420 NrOfObjects_1016_00 126;
BA_ "GenSigStartValue" SG_ 1420 Highest_sub_index_supported_0038 1;
BA_ "SystemSignalLongSymbol" SG_ 1420 Highest_sub_index_supported_0038 "Highest_sub_index_supported_1010_00";
BA_ "GenSigStartValue" SG_ 1420 Life_Time_Factor_100D 3;
BA_ "GenSigStartValue" SG_ 1420 Guard_Time_100C 500;
BA_ "GenSigStartValue" SG_ 1420 Sync_Window_Length_1007 100;
BA_ "GenSigStartValue" SG_ 1420 Communication_Cycle_Period_1006 200000;
BA_ "GenSigStartValue" SG_ 1420 COB_ID_SYNC_1005 2147483776;
BA_ "SystemSignalLongSymbol" SG_ 1420 Manufacturer_Status_Registe_0001 "Manufacturer_Status_Register_1002";
BA_ "GenSigStartValue" SG_ 1420 Device_Type_1000 402;
BA_ "GenSigStartValue" SG_ 1420 Index 4096;
VAL_ 1537 SubIndex_1F82 128 "RequestNMT All" 127 "RequestNMT" 126 "RequestNMT" 125 "RequestNMT" 124 "RequestNMT" 123 "RequestNMT" 122 "RequestNMT" 121 "RequestNMT" 120 "RequestNMT" 119 "RequestNMT" 118 "RequestNMT" 117 "RequestNMT" 116 "RequestNMT" 115 "RequestNMT" 114 "RequestNMT" 113 "RequestNMT" 112 "RequestNMT" 111 "RequestNMT" 110 "RequestNMT" 109 "RequestNMT" 108 "RequestNMT" 107 "RequestNMT" 106 "RequestNMT" 105 "RequestNMT" 104 "RequestNMT" 103 "RequestNMT" 102 "RequestNMT" 101 "RequestNMT" 100 "RequestNMT" 99 "RequestNMT" 98 "RequestNMT" 97 "RequestNMT" 96 "RequestNMT" 95 "RequestNMT" 94 "RequestNMT" 93 "RequestNMT" 92 "RequestNMT" 91 "RequestNMT" 90 "RequestNMT" 89 "RequestNMT" 88 "RequestNMT" 87 "RequestNMT" 86 "RequestNMT" 85 "RequestNMT" 84 "RequestNMT" 83 "RequestNMT" 82 "RequestNMT" 81 "RequestNMT" 80 "RequestNMT" 79 "RequestNMT" 78 "RequestNMT" 77 "RequestNMT" 76 "RequestNMT" 75 "RequestNMT" 74 "RequestNMT" 73 "RequestNMT" 72 "RequestNMT" 71 "RequestNMT" 70 "RequestNMT" 69 "RequestNMT" 68 "RequestNMT" 67 "RequestNMT" 66 "RequestNMT" 65 "RequestNMT" 64 "RequestNMT" 63 "RequestNMT" 62 "RequestNMT" 61 "RequestNMT" 60 "RequestNMT" 59 "RequestNMT" 58 "RequestNMT" 57 "RequestNMT" 56 "RequestNMT" 55 "RequestNMT" 54 "RequestNMT" 53 "RequestNMT" 52 "RequestNMT" 51 "RequestNMT" 50 "RequestNMT" 49 "RequestNMT" 48 "RequestNMT" 47 "RequestNMT" 46 "RequestNMT" 45 "RequestNMT" 44 "RequestNMT" 43 "RequestNMT" 42 "RequestNMT" 41 "RequestNMT" 40 "RequestNMT" 39 "RequestNMT" 38 "RequestNMT" 37 "RequestNMT" 36 "RequestNMT" 35 "RequestNMT" 34 "RequestNMT" 33 "RequestNMT" 32 "RequestNMT" 31 "RequestNMT" 30 "RequestNMT" 29 "RequestNMT" 28 "RequestNMT" 27 "RequestNMT" 26 "RequestNMT" 25 "RequestNMT" 24 "RequestNMT" 23 "RequestNMT" 22 "RequestNMT" 21 "RequestNMT" 20 "RequestNMT" 19 "RequestNMT" 18 "RequestNMT" 17 "RequestNMT" 16 "RequestNMT" 15 "RequestNMT" 14 "RequestNMT" 13 "RequestNMT" 12 "RequestNMT" 11 "RequestNMT" 10 "RequestNMT" 9 "RequestNMT" 8 "RequestNMT" 7 "RequestNMT" 6 "RequestNMT" 5 "RequestNMT" 4 "RequestNMT" 3 "RequestNMT" 2 "RequestNMT" 1 "RequestNMT" 0 "Highest sub-index supported" ;
VAL_ 1537 SubIndex_1F81 127 "SlaveAssignment" 126 "SlaveAssignment" 125 "SlaveAssignment" 124 "SlaveAssignment" 123 "SlaveAssignment" 122 "SlaveAssignment" 121 "SlaveAssignment" 120 "SlaveAssignment" 119 "SlaveAssignment" 118 "SlaveAssignment" 117 "SlaveAssignment" 116 "SlaveAssignment" 115 "SlaveAssignment" 114 "SlaveAssignment" 113 "SlaveAssignment" 112 "SlaveAssignment" 111 "SlaveAssignment" 110 "SlaveAssignment" 109 "SlaveAssignment" 108 "SlaveAssignment" 107 "SlaveAssignment" 106 "SlaveAssignment" 105 "SlaveAssignment" 104 "SlaveAssignment" 103 "SlaveAssignment" 102 "SlaveAssignment" 101 "SlaveAssignment" 100 "SlaveAssignment" 99 "SlaveAssignment" 98 "SlaveAssignment" 97 "SlaveAssignment" 96 "SlaveAssignment" 95 "SlaveAssignment" 94 "SlaveAssignment" 93 "SlaveAssignment" 92 "SlaveAssignment" 91 "SlaveAssignment" 90 "SlaveAssignment" 89 "SlaveAssignment" 88 "SlaveAssignment" 87 "SlaveAssignment" 86 "SlaveAssignment" 85 "SlaveAssignment" 84 "SlaveAssignment" 83 "SlaveAssignment" 82 "SlaveAssignment" 81 "SlaveAssignment" 80 "SlaveAssignment" 79 "SlaveAssignment" 78 "SlaveAssignment" 77 "SlaveAssignment" 76 "SlaveAssignment" 75 "SlaveAssignment" 74 "SlaveAssignment" 73 "SlaveAssignment" 72 "SlaveAssignment" 71 "SlaveAssignment" 70 "SlaveAssignment" 69 "SlaveAssignment" 68 "SlaveAssignment" 67 "SlaveAssignment" 66 "SlaveAssignment" 65 "SlaveAssignment" 64 "SlaveAssignment" 63 "SlaveAssignment" 62 "SlaveAssignment" 61 "SlaveAssignment" 60 "SlaveAssignment" 59 "SlaveAssignment" 58 "SlaveAssignment" 57 "SlaveAssignment" 56 "SlaveAssignment" 55 "SlaveAssignment" 54 "SlaveAssignment" 53 "SlaveAssignment" 52 "SlaveAssignment" 51 "SlaveAssignment" 50 "SlaveAssignment" 49 "SlaveAssignment" 48 "SlaveAssignment" 47 "SlaveAssignment" 46 "SlaveAssignment" 45 "SlaveAssignment" 44 "SlaveAssignment" 43 "SlaveAssignment" 42 "SlaveAssignment" 41 "SlaveAssignment" 40 "SlaveAssignment" 39 "SlaveAssignment" 38 "SlaveAssignment" 37 "SlaveAssignment" 36 "SlaveAssignment" 35 "SlaveAssignment" 34 "SlaveAssignment" 33 "SlaveAssignment" 32 "SlaveAssignment" 31 "SlaveAssignment" 30 "SlaveAssignment" 29 "SlaveAssignment" 28 "SlaveAssignment" 27 "SlaveAssignment" 26 "SlaveAssignment" 25 "SlaveAssignment" 24 "SlaveAssignment" 23 "SlaveAssignment" 22 "SlaveAssignment" 21 "SlaveAssignment" 20 "SlaveAssignment" 19 "SlaveAssignment" 18 "SlaveAssignment" 17 "SlaveAssignment" 16 "SlaveAssignment" 15 "SlaveAssignment" 14 "SlaveAssignment" 13 "SlaveAssignment" 12 "SlaveAssignment" 11 "SlaveAssignment" 10 "SlaveAssignment" 9 "SlaveAssignment" 8 "SlaveAssignment" 7 "SlaveAssignment" 6 "SlaveAssignment" 5 "SlaveAssignment" 4 "SlaveAssignment" 3 "SlaveAssignment" 2 "SlaveAssignment" 1 "SlaveAssignment" 0 "NrOfObjects" ;
VAL_ 1537 SubIndex_1F80 0 "NMTStartup" ;
VAL_ 1537 SubIndex_1F25 128 "Configure Slave" 127 "Configure Slave" 126 "Configure Slave" 125 "Configure Slave" 124 "Configure Slave" 123 "Configure Slave" 122 "Configure Slave" 121 "Configure Slave" 120 "Configure Slave" 119 "Configure Slave" 118 "Configure Slave" 117 "Configure Slave" 116 "Configure Slave" 115 "Configure Slave" 114 "Configure Slave" 113 "Configure Slave" 112 "Configure Slave" 111 "Configure Slave" 110 "Configure Slave" 109 "Configure Slave" 108 "Configure Slave" 107 "Configure Slave" 106 "Configure Slave" 105 "Configure Slave" 104 "Configure Slave" 103 "Configure Slave" 102 "Configure Slave" 101 "Configure Slave" 100 "Configure Slave" 99 "Configure Slave" 98 "Configure Slave" 97 "Configure Slave" 96 "Configure Slave" 95 "Configure Slave" 94 "Configure Slave" 93 "Configure Slave" 92 "Configure Slave" 91 "Configure Slave" 90 "Configure Slave" 89 "Configure Slave" 88 "Configure Slave" 87 "Configure Slave" 86 "Configure Slave" 85 "Configure Slave" 84 "Configure Slave" 83 "Configure Slave" 82 "Configure Slave" 81 "Configure Slave" 80 "Configure Slave" 79 "Configure Slave" 78 "Configure Slave" 77 "Configure Slave" 76 "Configure Slave" 75 "Configure Slave" 74 "Configure Slave" 73 "Configure Slave" 72 "Configure Slave" 71 "Configure Slave" 70 "Configure Slave" 69 "Configure Slave" 68 "Configure Slave" 67 "Configure Slave" 66 "Configure Slave" 65 "Configure Slave" 64 "Configure Slave" 63 "Configure Slave" 62 "Configure Slave" 61 "Configure Slave" 60 "Configure Slave" 59 "Configure Slave" 58 "Configure Slave" 57 "Configure Slave" 56 "Configure Slave" 55 "Configure Slave" 54 "Configure Slave" 53 "Configure Slave" 52 "Configure Slave" 51 "Configure Slave" 50 "Configure Slave" 49 "Configure Slave" 48 "Configure Slave" 47 "Configure Slave" 46 "Configure Slave" 45 "Configure Slave" 44 "Configure Slave" 43 "Configure Slave" 42 "Configure Slave" 41 "Configure Slave" 40 "Configure Slave" 39 "Configure Slave" 38 "Configure Slave" 37 "Configure Slave" 36 "Configure Slave" 35 "Configure Slave" 34 "Configure Slave" 33 "Configure Slave" 32 "Configure Slave" 31 "Configure Slave" 30 "Configure Slave" 29 "Configure Slave" 28 "Configure Slave" 27 "Configure Slave" 26 "Configure Slave" 25 "Configure Slave" 24 "Configure Slave" 23 "Configure Slave" 22 "Configure Slave" 21 "Configure Slave" 20 "Configure Slave" 19 "Configure Slave" 18 "Configure Slave" 17 "Configure Slave" 16 "Configure Slave" 15 "Configure Slave" 14 "Configure Slave" 13 "Configure Slave" 12 "Configure Slave" 11 "Configure Slave" 10 "Configure Slave" 9 "Configure Slave" 8 "Configure Slave" 7 "Configure Slave" 6 "Configure Slave" 5 "Configure Slave" 4 "Configure Slave" 3 "Configure Slave" 2 "Configure Slave" 1 "Configure Network" 0 "NrOfObjects" ;
VAL_ 1537 SubIndex_1F22 0 "NrOfObjects" ;
VAL_ 1537 SubIndex_1A04 3 "GENERATED" 2 "GENERATED" 1 "GENERATED" 0 "NrOfMappedObjects" ;
VAL_ 1537 SubIndex_1A03 3 "GENERATED" 2 "mappedObj2" 1 "mappedObj1" 0 "NrOfMappedObjects" ;
VAL_ 1537 SubIndex_1A02 2 "mappedObj2" 1 "mappedObj1" 0 "NrOfMappedObjects" ;
VAL_ 1537 SubIndex_1A01 2 "mappedObj2" 1 "mappedObj1" 0 "NrOfMappedObjects" ;
VAL_ 1537 SubIndex_1A00 2 "mappedObj2" 1 "mappedObj1" 0 "NrOfMappedObjects" ;
VAL_ 1537 SubIndex_1804 5 "EventTimer" 2 "TransmissionType" 1 "COB-ID" 0 "Highest sub-index supported" ;
VAL_ 1537 SubIndex_1803 5 "EventTimer" 2 "TransmissionType" 1 "COB-ID" 0 "Highest sub-index supported" ;
VAL_ 1537 SubIndex_1802 5 "EventTimer" 2 "TransmissionType" 1 "COB-ID" 0 "Highest sub-index supported" ;
VAL_ 1537 SubIndex_1801 5 "EventTimer" 2 "TransmissionType" 1 "COB-ID" 0 "Highest sub-index supported" ;
VAL_ 1537 SubIndex_1800 5 "EventTimer" 2 "TransmissionType" 1 "COB-ID" 0 "Highest sub-index supported" ;
VAL_ 1537 SubIndex_1604 5 "GENERATED" 4 "GENERATED" 3 "GENERATED" 2 "GENERATED" 1 "GENERATED" 0 "NrOfMappedObjects" ;
VAL_ 1537 SubIndex_1603 2 "mappedObj2" 1 "mappedObj1" 0 "NrOfMappedObjects" ;
VAL_ 1537 SubIndex_1602 2 "mappedObj2" 1 "mappedObj1" 0 "NrOfMappedObjects" ;
VAL_ 1537 SubIndex_1601 3 "GENERATED" 2 "mappedObj2" 1 "mappedObj1" 0 "NrOfMappedObjects" ;
VAL_ 1537 SubIndex_1600 5 "GENERATED" 4 "mappedObj4" 3 "mappedObj3" 2 "mappedObj2" 1 "mappedObj1" 0 "NrOfMappedObjects" ;
VAL_ 1537 SubIndex_1404 2 "TransmissionType" 1 "COB-ID" 0 "Highest sub-index supported" ;
VAL_ 1537 SubIndex_1403 2 "TransmissionType" 1 "COB-ID" 0 "Highest sub-index supported" ;
VAL_ 1537 SubIndex_1402 2 "TransmissionType" 1 "COB-ID" 0 "Highest sub-index supported" ;
VAL_ 1537 SubIndex_1401 2 "TransmissionType" 1 "COB-ID" 0 "Highest sub-index supported" ;
VAL_ 1537 SubIndex_1400 2 "TransmissionType" 1 "COB-ID" 0 "Highest sub-index supported" ;
VAL_ 1537 SubIndex_1020 2 "Configuration time" 1 "Configuration date" 0 "NrOfObjects" ;
VAL_ 1537 SubIndex_1018 4 "Serial number" 3 "Revision number" 2 "Product Code" 1 "Vendor Id" 0 "Highest sub-index supported" ;
VAL_ 1537 SubIndex_1017 0 "Producer Heartbeat Time" ;
VAL_ 1537 SubIndex_1016 126 "Consumer Heartbeat Time" 125 "Consumer Heartbeat Time" 124 "Consumer Heartbeat Time" 123 "Consumer Heartbeat Time" 122 "Consumer Heartbeat Time" 121 "Consumer Heartbeat Time" 120 "Consumer Heartbeat Time" 119 "Consumer Heartbeat Time" 118 "Consumer Heartbeat Time" 117 "Consumer Heartbeat Time" 116 "Consumer Heartbeat Time" 115 "Consumer Heartbeat Time" 114 "Consumer Heartbeat Time" 113 "Consumer Heartbeat Time" 112 "Consumer Heartbeat Time" 111 "Consumer Heartbeat Time" 110 "Consumer Heartbeat Time" 109 "Consumer Heartbeat Time" 108 "Consumer Heartbeat Time" 107 "Consumer Heartbeat Time" 106 "Consumer Heartbeat Time" 105 "Consumer Heartbeat Time" 104 "Consumer Heartbeat Time" 103 "Consumer Heartbeat Time" 102 "Consumer Heartbeat Time" 101 "Consumer Heartbeat Time" 100 "Consumer Heartbeat Time" 99 "Consumer Heartbeat Time" 98 "Consumer Heartbeat Time" 97 "Consumer Heartbeat Time" 96 "Consumer Heartbeat Time" 95 "Consumer Heartbeat Time" 94 "Consumer Heartbeat Time" 93 "Consumer Heartbeat Time" 92 "Consumer Heartbeat Time" 91 "Consumer Heartbeat Time" 90 "Consumer Heartbeat Time" 89 "Consumer Heartbeat Time" 88 "Consumer Heartbeat Time" 87 "Consumer Heartbeat Time" 86 "Consumer Heartbeat Time" 85 "Consumer Heartbeat Time" 84 "Consumer Heartbeat Time" 83 "Consumer Heartbeat Time" 82 "Consumer Heartbeat Time" 81 "Consumer Heartbeat Time" 80 "Consumer Heartbeat Time" 79 "Consumer Heartbeat Time" 78 "Consumer Heartbeat Time" 77 "Consumer Heartbeat Time" 76 "Consumer Heartbeat Time" 75 "Consumer Heartbeat Time" 74 "Consumer Heartbeat Time" 73 "Consumer Heartbeat Time" 72 "Consumer Heartbeat Time" 71 "Consumer Heartbeat Time" 70 "Consumer Heartbeat Time" 69 "Consumer Heartbeat Time" 68 "Consumer Heartbeat Time" 67 "Consumer Heartbeat Time" 66 "Consumer Heartbeat Time" 65 "Consumer Heartbeat Time" 64 "Consumer Heartbeat Time" 63 "Consumer Heartbeat Time" 62 "Consumer Heartbeat Time" 61 "Consumer Heartbeat Time" 60 "Consumer Heartbeat Time" 59 "Consumer Heartbeat Time" 58 "Consumer Heartbeat Time" 57 "Consumer Heartbeat Time" 56 "Consumer Heartbeat Time" 55 "Consumer Heartbeat Time" 54 "Consumer Heartbeat Time" 53 "Consumer Heartbeat Time" 52 "Consumer Heartbeat Time" 51 "Consumer Heartbeat Time" 50 "Consumer Heartbeat Time" 49 "Consumer Heartbeat Time" 48 "Consumer Heartbeat Time" 47 "Consumer Heartbeat Time" 46 "Consumer Heartbeat Time" 45 "Consumer Heartbeat Time" 44 "Consumer Heartbeat Time" 43 "Consumer Heartbeat Time" 42 "Consumer Heartbeat Time" 41 "Consumer Heartbeat Time" 40 "Consumer Heartbeat Time" 39 "Consumer Heartbeat Time" 38 "Consumer Heartbeat Time" 37 "Consumer Heartbeat Time" 36 "Consumer Heartbeat Time" 35 "Consumer Heartbeat Time" 34 "Consumer Heartbeat Time" 33 "Consumer Heartbeat Time" 32 "Consumer Heartbeat Time" 31 "Consumer Heartbeat Time" 30 "Consumer Heartbeat Time" 29 "Consumer Heartbeat Time" 28 "Consumer Heartbeat Time" 27 "Consumer Heartbeat Time" 26 "Consumer Heartbeat Time" 25 "Consumer Heartbeat Time" 24 "Consumer Heartbeat Time" 23 "Consumer Heartbeat Time" 22 "Consumer Heartbeat Time" 21 "Consumer Heartbeat Time" 20 "Consumer Heartbeat Time" 19 "Consumer Heartbeat Time" 18 "Consumer Heartbeat Time" 17 "Consumer Heartbeat Time" 16 "Consumer Heartbeat Time" 15 "Consumer Heartbeat Time" 14 "Consumer Heartbeat Time" 13 "Consumer Heartbeat Time" 12 "Consumer Heartbeat Time" 11 "Consumer Heartbeat Time" 10 "Consumer Heartbeat Time" 9 "Consumer Heartbeat Time" 8 "Consumer Heartbeat Time" 7 "Consumer Heartbeat Time" 6 "Consumer Heartbeat Time" 5 "Consumer Heartbeat Time" 4 "Consumer Heartbeat Time" 3 "Consumer Heartbeat Time" 2 "Consumer Heartbeat Time" 1 "Consumer Heartbeat Time" 0 "NrOfObjects" ;
VAL_ 1537 SubIndex_1011 1 "Restore all Default Parameters" 0 "Highest sub-index supported" ;
VAL_ 1537 SubIndex_1010 1 "Save all Parameters" 0 "Highest sub-index supported" ;
VAL_ 1537 SubIndex_100D 0 "Life Time Factor" ;
VAL_ 1537 SubIndex_100C 0 "Guard Time" ;
VAL_ 1537 SubIndex_1007 0 "Sync_Window Length" ;
VAL_ 1537 SubIndex_1006 0 "Communication Cycle Period" ;
VAL_ 1537 SubIndex_1005 0 "COB-ID SYNC" ;
VAL_ 1537 SubIndex_1002 0 "Manufacturer Status Register" ;
VAL_ 1537 SubIndex_1001 0 "Error Register" ;
VAL_ 1537 SubIndex_1000 0 "Device Type" ;
VAL_ 1537 Index 42624 "NetVarUInt32Out" 42560 "NetVarInt32Out" 42368 "NetVarUInt16Out" 42304 "NetVarInt16Out" 42176 "NetVarUInt8Out" 42112 "MyGateway" 41472 "NetVarUInt32In" 41408 "NetVarInt32In" 41216 "NetVarUInt16In" 41152 "NetVarInt16In" 41024 "NetVarUInt8In" 40960 "GatewayInfirst" 8072 "SerialNumber" 8069 "VendorIdentification" 8067 "RequestGuarding" 8066 "RequestNMT" 8065 "Slave Assignment" 8064 "NMTStartup" 7973 "Configure Slaves" 7970 "Concise DCF" 6660 "TxPDOMapping" 6659 "TxPDOMapping" 6658 "TxPDOMapping" 6657 "TxPDOMapping" 6656 "TxPDOMapping" 6148 "TxPDOComPar" 6147 "TxPDOComPar" 6146 "TxPDOComPar" 6145 "TxPDOComPar" 6144 "TxPDOComPar" 5636 "RxPDOMapping" 5635 "RxPDOMapping" 5634 "RxPDOMapping" 5633 "RxPDOMapping" 5632 "RxPDOMapping" 5124 "RxPDOComPar" 5123 "RxPDOComPar" 5122 "RxPDOComPar" 5121 "RxPDOComPar" 5120 "RxPDOComPar" 4128 "Verify Configuration" 4120 "Identity Object" 4119 "Producer Heartbeat Time" 4118 "Consumer Heartbeat Time" 4113 "Restore Default Parameters" 4112 "Store Parameter Field" 4109 "Life Time Factor" 4108 "Guard Time" 4103 "Sync_Window Length" 4102 "Communication Cycle Period" 4101 "COB-ID SYNC" 4098 "Manufacturer Status Register" 4097 "Error Register" 4096 "Device Type" ;
VAL_ 1537 TransferType 1 "Expedited transfer" 0 "Normal transfer" ;
VAL_ 1537 SizeIndicator 1 "Size is indicated" 0 "Size is not indicated" ;
VAL_ 1537 CCS 2 "Upload" 1 "Download" ;
VAL_ 129 ErrorCode 33360 "RPDO timeout" 33344 "Unexpected SYNC data length" 33328 "DAM MPDO not processed, destination object not available" 33312 "PDO length exceeded" 33296 "PDO not processed due to length error" 33104 "Transmit COB-ID collision" 33088 "Recovered from bus off state" 33072 "Life guard error or heartbeat error" 33056 "CAN in error passive mode" 33040 "CAN overrun (objects lost)" ;
VAL_ 1804 State 127 "PreOperational" 5 "Operational" 4 "Stopped" 0 "Bootup" ;
VAL_ 1420 SubIndex_6502 0 "supported_drive_modes" ;
VAL_ 1420 SubIndex_6407 0 "motor_service_period" ;
VAL_ 1420 SubIndex_6402 0 "motor_type" ;
VAL_ 1420 SubIndex_60FF 0 "target_velocity" ;
VAL_ 1420 SubIndex_60FE 2 "bitmask" 1 "physical_outputs" 0 "digital_outputs_highest_subindex" ;
VAL_ 1420 SubIndex_60FD 0 "digital_inputs" ;
VAL_ 1420 SubIndex_607E 0 "polarity" ;
VAL_ 1420 SubIndex_607A 0 "target_position" ;
VAL_ 1420 SubIndex_6077 0 "torque_actual_value" ;
VAL_ 1420 SubIndex_6071 0 "target_torque" ;
VAL_ 1420 SubIndex_606C 0 "velocity_actual_value" ;
VAL_ 1420 SubIndex_6067 0 "position_window" ;
VAL_ 1420 SubIndex_6064 0 "position_actual_value" ;
VAL_ 1420 SubIndex_6063 0 "position_actual_internal_value" ;
VAL_ 1420 SubIndex_6062 0 "position_demand_value" ;
VAL_ 1420 SubIndex_6061 0 "modes_of_operation_display" ;
VAL_ 1420 SubIndex_6060 0 "modes_of_operation" ;
VAL_ 1420 SubIndex_605E 0 "fault_reaction_option_code" ;
VAL_ 1420 SubIndex_605D 0 "stop_option_code" ;
VAL_ 1420 SubIndex_605C 0 "disable_operation_option_code" ;
VAL_ 1420 SubIndex_605B 0 "shutdown_option_code" ;
VAL_ 1420 SubIndex_605A 0 "quick_stop_option_code" ;
VAL_ 1420 SubIndex_6049 2 "delta_time" 1 "delta_speed" 0 "NrOfObjects" ;
VAL_ 1420 SubIndex_6048 2 "delta_time" 1 "delta_speed" 0 "NrOfObjects" ;
VAL_ 1420 SubIndex_6046 2 "vl_velocity_max_amount" 1 "vl_velocity_min_amount" 0 "vl_velocity_min_max_amount_highest_subindex" ;
VAL_ 1420 SubIndex_6044 0 "vl_control_effort" ;
VAL_ 1420 SubIndex_6043 0 "vl_velocity_demand" ;
VAL_ 1420 SubIndex_6042 0 "vl_target_velocity" ;
VAL_ 1420 SubIndex_6041 0 "statusword" ;
VAL_ 1420 SubIndex_6040 0 "controlword" ;
VAL_ 1420 SubIndex_603F 0 "error_code" ;
VAL_ 1420 SubIndex_6007 0 "abort_connection_option_code" ;
VAL_ 1420 SubIndex_1A06 2 "PDO Mapping Entry" 1 "PDO Mapping Entry" 0 "NrOfMappedObjects" ;
VAL_ 1420 SubIndex_1A05 2 "PDO Mapping Entry" 1 "PDO Mapping Entry" 0 "NrOfMappedObjects" ;
VAL_ 1420 SubIndex_1A04 2 "PDO Mapping Entry" 1 "PDO Mapping Entry" 0 "NrOfMappedObjects" ;
VAL_ 1420 SubIndex_1A03 2 "PDO Mapping Entry" 1 "PDO Mapping Entry" 0 "NrOfMappedObjects" ;
VAL_ 1420 SubIndex_1A02 2 "mappedObj2" 1 "mappedObj1" 0 "NrOfMappedObjects" ;
VAL_ 1420 SubIndex_1A01 2 "mappedObj2" 1 "mappedObj1" 0 "NrOfMappedObjects" ;
VAL_ 1420 SubIndex_1A00 1 "mappedObj1" 0 "NrOfMappedObjects" ;
VAL_ 1420 SubIndex_1806 5 "EventTimer" 2 "TransmissionType" 1 "COB-ID" 0 "Highest sub-index supported" ;
VAL_ 1420 SubIndex_1805 5 "EventTimer" 2 "TransmissionType" 1 "COB-ID" 0 "Highest sub-index supported" ;
VAL_ 1420 SubIndex_1804 5 "EventTimer" 2 "TransmissionType" 1 "COB-ID" 0 "Highest sub-index supported" ;
VAL_ 1420 SubIndex_1803 5 "EventTimer" 2 "TransmissionType" 1 "COB-ID" 0 "Highest sub-index supported" ;
VAL_ 1420 SubIndex_1802 5 "EventTimer" 2 "TransmissionType" 1 "COB-ID" 0 "Highest sub-index supported" ;
VAL_ 1420 SubIndex_1801 5 "EventTimer" 2 "TransmissionType" 1 "COB-ID" 0 "Highest sub-index supported" ;
VAL_ 1420 SubIndex_1800 5 "EventTimer" 2 "TransmissionType" 1 "COB-ID" 0 "Highest sub-index supported" ;
VAL_ 1420 SubIndex_1607 2 "PDO Mapping Entry" 1 "PDO Mapping Entry" 0 "NrOfMappedObjects" ;
VAL_ 1420 SubIndex_1606 2 "PDO Mapping Entry" 1 "PDO Mapping Entry" 0 "NrOfMappedObjects" ;
VAL_ 1420 SubIndex_1605 2 "PDO Mapping Entry" 1 "PDO Mapping Entry" 0 "NrOfMappedObjects" ;
VAL_ 1420 SubIndex_1604 2 "PDO Mapping Entry" 1 "PDO Mapping Entry" 0 "NrOfMappedObjects" ;
VAL_ 1420 SubIndex_1603 2 "PDO Mapping Entry" 1 "PDO Mapping Entry" 0 "NrOfMappedObjects" ;
VAL_ 1420 SubIndex_1602 2 "PDO Mapping Entry" 1 "PDO Mapping Entry" 0 "NrOfMappedObjects" ;
VAL_ 1420 SubIndex_1601 2 "PDO Mapping Entry" 1 "PDO Mapping Entry" 0 "NrOfMappedObjects" ;
VAL_ 1420 SubIndex_1600 4 "PDO Mapping Entry" 3 "PDO Mapping Entry" 2 "mappedObj2" 1 "mappedObj1" 0 "NrOfMappedObjects" ;
VAL_ 1420 SubIndex_1407 2 "TransmissionType" 1 "COB-ID" 0 "Highest sub-index supported" ;
VAL_ 1420 SubIndex_1406 2 "TransmissionType" 1 "COB-ID" 0 "Highest sub-index supported" ;
VAL_ 1420 SubIndex_1405 2 "TransmissionType" 1 "COB-ID" 0 "Highest sub-index supported" ;
VAL_ 1420 SubIndex_1404 2 "TransmissionType" 1 "COB-ID" 0 "Highest sub-index supported" ;
VAL_ 1420 SubIndex_1403 2 "TransmissionType" 1 "COB-ID" 0 "Highest sub-index supported" ;
VAL_ 1420 SubIndex_1402 2 "TransmissionType" 1 "COB-ID" 0 "Highest sub-index supported" ;
VAL_ 1420 SubIndex_1401 2 "TransmissionType" 1 "COB-ID" 0 "Highest sub-index supported" ;
VAL_ 1420 SubIndex_1400 2 "TransmissionType" 1 "COB-ID" 0 "Highest sub-index supported" ;
VAL_ 1420 SubIndex_1018 4 "Serial number" 3 "Revision number" 2 "Product Code" 1 "Vendor Id" 0 "Highest sub-index supported" ;
VAL_ 1420 SubIndex_1017 0 "Producer Heartbeat Time" ;
VAL_ 1420 SubIndex_1016 126 "Consumer Heartbeat Time" 125 "Consumer Heartbeat Time" 124 "Consumer Heartbeat Time" 123 "Consumer Heartbeat Time" 122 "Consumer Heartbeat Time" 121 "Consumer Heartbeat Time" 120 "Consumer Heartbeat Time" 119 "Consumer Heartbeat Time" 118 "Consumer Heartbeat Time" 117 "Consumer Heartbeat Time" 116 "Consumer Heartbeat Time" 115 "Consumer Heartbeat Time" 114 "Consumer Heartbeat Time" 113 "Consumer Heartbeat Time" 112 "Consumer Heartbeat Time" 111 "Consumer Heartbeat Time" 110 "Consumer Heartbeat Time" 109 "Consumer Heartbeat Time" 108 "Consumer Heartbeat Time" 107 "Consumer Heartbeat Time" 106 "Consumer Heartbeat Time" 105 "Consumer Heartbeat Time" 104 "Consumer Heartbeat Time" 103 "Consumer Heartbeat Time" 102 "Consumer Heartbeat Time" 101 "Consumer Heartbeat Time" 100 "Consumer Heartbeat Time" 99 "Consumer Heartbeat Time" 98 "Consumer Heartbeat Time" 97 "Consumer Heartbeat Time" 96 "Consumer Heartbeat Time" 95 "Consumer Heartbeat Time" 94 "Consumer Heartbeat Time" 93 "Consumer Heartbeat Time" 92 "Consumer Heartbeat Time" 91 "Consumer Heartbeat Time" 90 "Consumer Heartbeat Time" 89 "Consumer Heartbeat Time" 88 "Consumer Heartbeat Time" 87 "Consumer Heartbeat Time" 86 "Consumer Heartbeat Time" 85 "Consumer Heartbeat Time" 84 "Consumer Heartbeat Time" 83 "Consumer Heartbeat Time" 82 "Consumer Heartbeat Time" 81 "Consumer Heartbeat Time" 80 "Consumer Heartbeat Time" 79 "Consumer Heartbeat Time" 78 "Consumer Heartbeat Time" 77 "Consumer Heartbeat Time" 76 "Consumer Heartbeat Time" 75 "Consumer Heartbeat Time" 74 "Consumer Heartbeat Time" 73 "Consumer Heartbeat Time" 72 "Consumer Heartbeat Time" 71 "Consumer Heartbeat Time" 70 "Consumer Heartbeat Time" 69 "Consumer Heartbeat Time" 68 "Consumer Heartbeat Time" 67 "Consumer Heartbeat Time" 66 "Consumer Heartbeat Time" 65 "Consumer Heartbeat Time" 64 "Consumer Heartbeat Time" 63 "Consumer Heartbeat Time" 62 "Consumer Heartbeat Time" 61 "Consumer Heartbeat Time" 60 "Consumer Heartbeat Time" 59 "Consumer Heartbeat Time" 58 "Consumer Heartbeat Time" 57 "Consumer Heartbeat Time" 56 "Consumer Heartbeat Time" 55 "Consumer Heartbeat Time" 54 "Consumer Heartbeat Time" 53 "Consumer Heartbeat Time" 52 "Consumer Heartbeat Time" 51 "Consumer Heartbeat Time" 50 "Consumer Heartbeat Time" 49 "Consumer Heartbeat Time" 48 "Consumer Heartbeat Time" 47 "Consumer Heartbeat Time" 46 "Consumer Heartbeat Time" 45 "Consumer Heartbeat Time" 44 "Consumer Heartbeat Time" 43 "Consumer Heartbeat Time" 42 "Consumer Heartbeat Time" 41 "Consumer Heartbeat Time" 40 "Consumer Heartbeat Time" 39 "Consumer Heartbeat Time" 38 "Consumer Heartbeat Time" 37 "Consumer Heartbeat Time" 36 "Consumer Heartbeat Time" 35 "Consumer Heartbeat Time" 34 "Consumer Heartbeat Time" 33 "Consumer Heartbeat Time" 32 "Consumer Heartbeat Time" 31 "Consumer Heartbeat Time" 30 "Consumer Heartbeat Time" 29 "Consumer Heartbeat Time" 28 "Consumer Heartbeat Time" 27 "Consumer Heartbeat Time" 26 "Consumer Heartbeat Time" 25 "Consumer Heartbeat Time" 24 "Consumer Heartbeat Time" 23 "Consumer Heartbeat Time" 22 "Consumer Heartbeat Time" 21 "Consumer Heartbeat Time" 20 "Consumer Heartbeat Time" 19 "Consumer Heartbeat Time" 18 "Consumer Heartbeat Time" 17 "Consumer Heartbeat Time" 16 "Consumer Heartbeat Time" 15 "Consumer Heartbeat Time" 14 "Consumer Heartbeat Time" 13 "Consumer Heartbeat Time" 12 "Consumer Heartbeat Time" 11 "Consumer Heartbeat Time" 10 "Consumer Heartbeat Time" 9 "Consumer Heartbeat Time" 8 "Consumer Heartbeat Time" 7 "Consumer Heartbeat Time" 6 "Consumer Heartbeat Time" 5 "Consumer Heartbeat Time" 4 "Consumer Heartbeat Time" 3 "Consumer Heartbeat Time" 2 "Consumer Heartbeat Time" 1 "Consumer Heartbeat Time" 0 "NrOfObjects" ;
VAL_ 1420 SubIndex_1010 1 "Save all Parameters" 0 "Highest sub-index supported" ;
VAL_ 1420 SubIndex_100D 0 "Life Time Factor" ;
VAL_ 1420 SubIndex_100C 0 "Guard Time" ;
VAL_ 1420 SubIndex_1007 0 "Sync_Window Length" ;
VAL_ 1420 SubIndex_1006 0 "Communication Cycle Period" ;
VAL_ 1420 SubIndex_1005 0 "COB-ID SYNC" ;
VAL_ 1420 SubIndex_1002 0 "Manufacturer Status Register" ;
VAL_ 1420 SubIndex_1001 0 "Error Register" ;
VAL_ 1420 SubIndex_1000 0 "Device Type" ;
VAL_ 1420 Index 25858 "supported_drive_modes" 25607 "motor_service_period" 25602 "motor_type" 24831 "target_velocity" 24830 "digital_outputs" 24829 "digital_inputs" 24702 "polarity" 24698 "target_position" 24695 "torque_actual_value" 24689 "target_torque" 24684 "velocity_actual_value" 24679 "position_window" 24676 "position_actual_value" 24675 "position_actual_internal_value" 24674 "position_demand_value" 24673 "modes_of_operation_display" 24672 "modes_of_operation" 24670 "fault_reaction_option_code" 24669 "stop_option_code" 24668 "disable_operation_option_code" 24667 "shutdown_option_code" 24666 "quick_stop_option_code" 24649 "vl_velocity_deceleration" 24648 "vl_velocity_acceleration" 24646 "vl_velocity_min_max_amount" 24644 "vl_control_effort" 24643 "vl_velocity_demand" 24642 "vl_target_velocity" 24641 "statusword" 24640 "controlword" 24639 "error_code" 24583 "abort_connection_option_code" 6662 "TxPDOMapping" 6661 "TxPDOMapping" 6660 "TxPDOMapping" 6659 "TxPDOMapping" 6658 "TxPDOMapping" 6657 "TxPDOMapping" 6656 "TxPDOMapping" 6150 "TxPDOComPar" 6149 "TxPDOComPar" 6148 "TxPDOComPar" 6147 "TxPDOComPar" 6146 "TxPDOComPar" 6145 "TxPDOComPar" 6144 "TxPDOComPar" 5639 "RxPDOMapping" 5638 "RxPDOMapping" 5637 "RxPDOMapping" 5636 "RxPDOMapping" 5635 "RxPDOMapping" 5634 "RxPDOMapping" 5633 "RxPDOMapping" 5632 "RxPDOMapping" 5127 "RxPDOComPar" 5126 "RxPDOComPar" 5125 "RxPDOComPar" 5124 "RxPDOComPar" 5123 "RxPDOComPar" 5122 "RxPDOComPar" 5121 "RxPDOComPar" 5120 "RxPDOComPar" 4120 "Identity Object" 4119 "Producer Heartbeat Time" 4118 "Consumer Heartbeat Time" 4112 "Store Parameter Field" 4109 "Life Time Factor" 4108 "Guard Time" 4103 "Sync_Window Length" 4102 "Communication Cycle Period" 4101 "COB-ID SYNC" 4098 "Manufacturer Status Register" 4097 "Error Register" 4096 "Device Type" ;
VAL_ 1420 TransferType 1 "Expedited transfer" 0 "Normal transfer" ;
VAL_ 1420 SizeIndicator 1 "Size is indicated" 0 "Size is not indicated" ;
VAL_ 1420 SCS 2 "Upload" 1 "Download" ;
SG_MUL_VAL_ 1537 RequestNMT_1F82_5E SubIndex_1F82 94-94;
SG_MUL_VAL_ 1537 RequestNMT_1F82_5D SubIndex_1F82 93-93;
SG_MUL_VAL_ 1537 RequestNMT_1F82_5C SubIndex_1F82 92-92;
SG_MUL_VAL_ 1537 RequestNMT_1F82_5B SubIndex_1F82 91-91;
SG_MUL_VAL_ 1537 RequestNMT_1F82_5A SubIndex_1F82 90-90;
SG_MUL_VAL_ 1537 RequestNMT_1F82_59 SubIndex_1F82 89-89;
SG_MUL_VAL_ 1537 RequestNMT_1F82_58 SubIndex_1F82 88-88;
SG_MUL_VAL_ 1537 RequestNMT_1F82_57 SubIndex_1F82 87-87;
SG_MUL_VAL_ 1537 RequestNMT_1F82_56 SubIndex_1F82 86-86;
SG_MUL_VAL_ 1537 RequestNMT_1F82_55 SubIndex_1F82 85-85;
SG_MUL_VAL_ 1537 RequestNMT_1F82_54 SubIndex_1F82 84-84;
SG_MUL_VAL_ 1537 RequestNMT_1F82_53 SubIndex_1F82 83-83;
SG_MUL_VAL_ 1537 RequestNMT_1F82_52 SubIndex_1F82 82-82;
SG_MUL_VAL_ 1537 RequestNMT_1F82_51 SubIndex_1F82 81-81;
SG_MUL_VAL_ 1537 RequestNMT_1F82_50 SubIndex_1F82 80-80;
SG_MUL_VAL_ 1537 RequestNMT_1F82_4F SubIndex_1F82 79-79;
SG_MUL_VAL_ 1537 RequestNMT_1F82_4E SubIndex_1F82 78-78;
SG_MUL_VAL_ 1537 RequestNMT_1F82_4D SubIndex_1F82 77-77;
SG_MUL_VAL_ 1537 RequestNMT_1F82_4C SubIndex_1F82 76-76;
SG_MUL_VAL_ 1537 RequestNMT_1F82_4B SubIndex_1F82 75-75;
SG_MUL_VAL_ 1537 RequestNMT_1F82_4A SubIndex_1F82 74-74;
SG_MUL_VAL_ 1537 RequestNMT_1F82_49 SubIndex_1F82 73-73;
SG_MUL_VAL_ 1537 RequestNMT_1F82_48 SubIndex_1F82 72-72;
SG_MUL_VAL_ 1537 RequestNMT_1F82_47 SubIndex_1F82 71-71;
SG_MUL_VAL_ 1537 RequestNMT_1F82_46 SubIndex_1F82 70-70;
SG_MUL_VAL_ 1537 RequestNMT_1F82_45 SubIndex_1F82 69-69;
SG_MUL_VAL_ 1537 RequestNMT_1F82_44 SubIndex_1F82 68-68;
SG_MUL_VAL_ 1537 RequestNMT_1F82_43 SubIndex_1F82 67-67;
SG_MUL_VAL_ 1537 RequestNMT_1F82_42 SubIndex_1F82 66-66;
SG_MUL_VAL_ 1537 RequestNMT_1F82_41 SubIndex_1F82 65-65;
SG_MUL_VAL_ 1537 RequestNMT_1F82_40 SubIndex_1F82 64-64;
SG_MUL_VAL_ 1537 RequestNMT_1F82_3F SubIndex_1F82 63-63;
SG_MUL_VAL_ 1537 RequestNMT_1F82_3E SubIndex_1F82 62-62;
SG_MUL_VAL_ 1537 RequestNMT_1F82_3D SubIndex_1F82 61-61;
SG_MUL_VAL_ 1537 RequestNMT_1F82_3C SubIndex_1F82 60-60;
SG_MUL_VAL_ 1537 RequestNMT_1F82_3B SubIndex_1F82 59-59;
SG_MUL_VAL_ 1537 RequestNMT_1F82_3A SubIndex_1F82 58-58;
SG_MUL_VAL_ 1537 RequestNMT_1F82_39 SubIndex_1F82 57-57;
SG_MUL_VAL_ 1537 RequestNMT_1F82_38 SubIndex_1F82 56-56;
SG_MUL_VAL_ 1537 RequestNMT_1F82_37 SubIndex_1F82 55-55;
SG_MUL_VAL_ 1537 RequestNMT_1F82_36 SubIndex_1F82 54-54;
SG_MUL_VAL_ 1537 RequestNMT_1F82_35 SubIndex_1F82 53-53;
SG_MUL_VAL_ 1537 RequestNMT_1F82_34 SubIndex_1F82 52-52;
SG_MUL_VAL_ 1537 RequestNMT_1F82_33 SubIndex_1F82 51-51;
SG_MUL_VAL_ 1537 RequestNMT_1F82_32 SubIndex_1F82 50-50;
SG_MUL_VAL_ 1537 RequestNMT_1F82_31 SubIndex_1F82 49-49;
SG_MUL_VAL_ 1537 RequestNMT_1F82_30 SubIndex_1F82 48-48;
SG_MUL_VAL_ 1537 RequestNMT_1F82_2F SubIndex_1F82 47-47;
SG_MUL_VAL_ 1537 RequestNMT_1F82_2E SubIndex_1F82 46-46;
SG_MUL_VAL_ 1537 RequestNMT_1F82_2D SubIndex_1F82 45-45;
SG_MUL_VAL_ 1537 RequestNMT_1F82_2C SubIndex_1F82 44-44;
SG_MUL_VAL_ 1537 RequestNMT_1F82_2B SubIndex_1F82 43-43;
SG_MUL_VAL_ 1537 RequestNMT_1F82_2A SubIndex_1F82 42-42;
SG_MUL_VAL_ 1537 RequestNMT_1F82_29 SubIndex_1F82 41-41;
SG_MUL_VAL_ 1537 RequestNMT_1F82_28 SubIndex_1F82 40-40;
SG_MUL_VAL_ 1537 RequestNMT_1F82_27 SubIndex_1F82 39-39;
SG_MUL_VAL_ 1537 RequestNMT_1F82_26 SubIndex_1F82 38-38;
SG_MUL_VAL_ 1537 RequestNMT_1F82_25 SubIndex_1F82 37-37;
SG_MUL_VAL_ 1537 RequestNMT_1F82_24 SubIndex_1F82 36-36;
SG_MUL_VAL_ 1537 RequestNMT_1F82_23 SubIndex_1F82 35-35;
SG_MUL_VAL_ 1537 RequestNMT_1F82_22 SubIndex_1F82 34-34;
SG_MUL_VAL_ 1537 RequestNMT_1F82_21 SubIndex_1F82 33-33;
SG_MUL_VAL_ 1537 RequestNMT_1F82_20 SubIndex_1F82 32-32;
SG_MUL_VAL_ 1537 RequestNMT_1F82_1F SubIndex_1F82 31-31;
SG_MUL_VAL_ 1537 RequestNMT_1F82_1E SubIndex_1F82 30-30;
SG_MUL_VAL_ 1537 RequestNMT_1F82_1D SubIndex_1F82 29-29;
SG_MUL_VAL_ 1537 RequestNMT_1F82_1C SubIndex_1F82 28-28;
SG_MUL_VAL_ 1537 RequestNMT_1F82_1B SubIndex_1F82 27-27;
SG_MUL_VAL_ 1537 RequestNMT_1F82_1A SubIndex_1F82 26-26;
SG_MUL_VAL_ 1537 RequestNMT_1F82_19 SubIndex_1F82 25-25;
SG_MUL_VAL_ 1537 RequestNMT_1F82_18 SubIndex_1F82 24-24;
SG_MUL_VAL_ 1537 RequestNMT_1F82_17 SubIndex_1F82 23-23;
SG_MUL_VAL_ 1537 RequestNMT_1F82_16 SubIndex_1F82 22-22;
SG_MUL_VAL_ 1537 RequestNMT_1F82_15 SubIndex_1F82 21-21;
SG_MUL_VAL_ 1537 RequestNMT_1F82_14 SubIndex_1F82 20-20;
SG_MUL_VAL_ 1537 RequestNMT_1F82_13 SubIndex_1F82 19-19;
SG_MUL_VAL_ 1537 RequestNMT_1F82_12 SubIndex_1F82 18-18;
SG_MUL_VAL_ 1537 RequestNMT_1F82_11 SubIndex_1F82 17-17;
SG_MUL_VAL_ 1537 RequestNMT_1F82_10 SubIndex_1F82 16-16;
SG_MUL_VAL_ 1537 RequestNMT_1F82_0F SubIndex_1F82 15-15;
SG_MUL_VAL_ 1537 RequestNMT_1F82_0E SubIndex_1F82 14-14;
SG_MUL_VAL_ 1537 RequestNMT_1F82_0D SubIndex_1F82 13-13;
SG_MUL_VAL_ 1537 RequestNMT_1F82_0C SubIndex_1F82 12-12;
SG_MUL_VAL_ 1537 RequestNMT_1F82_0B SubIndex_1F82 11-11;
SG_MUL_VAL_ 1537 RequestNMT_1F82_0A SubIndex_1F82 10-10;
SG_MUL_VAL_ 1537 RequestNMT_1F82_09 SubIndex_1F82 9-9;
SG_MUL_VAL_ 1537 RequestNMT_1F82_08 SubIndex_1F82 8-8;
SG_MUL_VAL_ 1537 RequestNMT_1F82_07 SubIndex_1F82 7-7;
SG_MUL_VAL_ 1537 RequestNMT_1F82_06 SubIndex_1F82 6-6;
SG_MUL_VAL_ 1537 RequestNMT_1F82_05 SubIndex_1F82 5-5;
SG_MUL_VAL_ 1537 RequestNMT_1F82_04 SubIndex_1F82 4-4;
SG_MUL_VAL_ 1537 RequestNMT_1F82_03 SubIndex_1F82 3-3;
SG_MUL_VAL_ 1537 RequestNMT_1F82_02 SubIndex_1F82 2-2;
SG_MUL_VAL_ 1537 RequestNMT_1F82_01 SubIndex_1F82 1-1;
SG_MUL_VAL_ 1537 Highest_sub_index_supported_0013 SubIndex_1F82 0-0;
SG_MUL_VAL_ 1537 SubIndex_1F82 Index 8066-8066;
SG_MUL_VAL_ 1537 SlaveAssignment_1F81_7F SubIndex_1F81 127-127;
SG_MUL_VAL_ 1537 SlaveAssignment_1F81_7E SubIndex_1F81 126-126;
SG_MUL_VAL_ 1537 SlaveAssignment_1F81_7D SubIndex_1F81 125-125;
SG_MUL_VAL_ 1537 SlaveAssignment_1F81_7C SubIndex_1F81 124-124;
SG_MUL_VAL_ 1537 SlaveAssignment_1F81_7B SubIndex_1F81 123-123;
SG_MUL_VAL_ 1537 SlaveAssignment_1F81_7A SubIndex_1F81 122-122;
SG_MUL_VAL_ 1537 SlaveAssignment_1F81_79 SubIndex_1F81 121-121;
SG_MUL_VAL_ 1537 SlaveAssignment_1F81_78 SubIndex_1F81 120-120;
SG_MUL_VAL_ 1537 SlaveAssignment_1F81_77 SubIndex_1F81 119-119;
SG_MUL_VAL_ 1537 SlaveAssignment_1F81_76 SubIndex_1F81 118-118;
SG_MUL_VAL_ 1537 SlaveAssignment_1F81_75 SubIndex_1F81 117-117;
SG_MUL_VAL_ 1537 SlaveAssignment_1F81_74 SubIndex_1F81 116-116;
SG_MUL_VAL_ 1537 SlaveAssignment_1F81_73 SubIndex_1F81 115-115;
SG_MUL_VAL_ 1537 SlaveAssignment_1F81_72 SubIndex_1F81 114-114;
SG_MUL_VAL_ 1537 SlaveAssignment_1F81_71 SubIndex_1F81 113-113;
SG_MUL_VAL_ 1537 SlaveAssignment_1F81_70 SubIndex_1F81 112-112;
SG_MUL_VAL_ 1537 SlaveAssignment_1F81_6F SubIndex_1F81 111-111;
SG_MUL_VAL_ 1537 SlaveAssignment_1F81_6E SubIndex_1F81 110-110;
SG_MUL_VAL_ 1537 SlaveAssignment_1F81_6D SubIndex_1F81 109-109;
SG_MUL_VAL_ 1537 SlaveAssignment_1F81_6C SubIndex_1F81 108-108;
SG_MUL_VAL_ 1537 SlaveAssignment_1F81_6B SubIndex_1F81 107-107;
SG_MUL_VAL_ 1537 SlaveAssignment_1F81_6A SubIndex_1F81 106-106;
SG_MUL_VAL_ 1537 SlaveAssignment_1F81_69 SubIndex_1F81 105-105;
SG_MUL_VAL_ 1537 SlaveAssignment_1F81_68 SubIndex_1F81 104-104;
SG_MUL_VAL_ 1537 SlaveAssignment_1F81_67 SubIndex_1F81 103-103;
SG_MUL_VAL_ 1537 SlaveAssignment_1F81_66 SubIndex_1F81 102-102;
SG_MUL_VAL_ 1537 SlaveAssignment_1F81_65 SubIndex_1F81 101-101;
SG_MUL_VAL_ 1537 SlaveAssignment_1F81_64 SubIndex_1F81 100-100;
SG_MUL_VAL_ 1537 SlaveAssignment_1F81_63 SubIndex_1F81 99-99;
SG_MUL_VAL_ 1537 SlaveAssignment_1F81_62 SubIndex_1F81 98-98;
SG_MUL_VAL_ 1537 SlaveAssignment_1F81_61 SubIndex_1F81 97-97;
SG_MUL_VAL_ 1537 SlaveAssignment_1F81_60 SubIndex_1F81 96-96;
SG_MUL_VAL_ 1537 SlaveAssignment_1F81_5F SubIndex_1F81 95-95;
SG_MUL_VAL_ 1537 SlaveAssignment_1F81_5E SubIndex_1F81 94-94;
SG_MUL_VAL_ 1537 SlaveAssignment_1F81_5D SubIndex_1F81 93-93;
SG_MUL_VAL_ 1537 SlaveAssignment_1F81_5C SubIndex_1F81 92-92;
SG_MUL_VAL_ 1537 SlaveAssignment_1F81_5B SubIndex_1F81 91-91;
SG_MUL_VAL_ 1537 SlaveAssignment_1F81_5A SubIndex_1F81 90-90;
SG_MUL_VAL_ 1537 SlaveAssignment_1F81_59 SubIndex_1F81 89-89;
SG_MUL_VAL_ 1537 SlaveAssignment_1F81_58 SubIndex_1F81 88-88;
SG_MUL_VAL_ 1537 SlaveAssignment_1F81_57 SubIndex_1F81 87-87;
SG_MUL_VAL_ 1537 SlaveAssignment_1F81_56 SubIndex_1F81 86-86;
SG_MUL_VAL_ 1537 SlaveAssignment_1F81_55 SubIndex_1F81 85-85;
SG_MUL_VAL_ 1537 SlaveAssignment_1F81_54 SubIndex_1F81 84-84;
SG_MUL_VAL_ 1537 SlaveAssignment_1F81_53 SubIndex_1F81 83-83;
SG_MUL_VAL_ 1537 SlaveAssignment_1F81_52 SubIndex_1F81 82-82;
SG_MUL_VAL_ 1537 SlaveAssignment_1F81_51 SubIndex_1F81 81-81;
SG_MUL_VAL_ 1537 SlaveAssignment_1F81_50 SubIndex_1F81 80-80;
SG_MUL_VAL_ 1537 SlaveAssignment_1F81_4F SubIndex_1F81 79-79;
SG_MUL_VAL_ 1537 SlaveAssignment_1F81_4E SubIndex_1F81 78-78;
SG_MUL_VAL_ 1537 SlaveAssignment_1F81_4D SubIndex_1F81 77-77;
SG_MUL_VAL_ 1537 SlaveAssignment_1F81_4C SubIndex_1F81 76-76;
SG_MUL_VAL_ 1537 SlaveAssignment_1F81_4B SubIndex_1F81 75-75;
SG_MUL_VAL_ 1537 SlaveAssignment_1F81_4A SubIndex_1F81 74-74;
SG_MUL_VAL_ 1537 SlaveAssignment_1F81_49 SubIndex_1F81 73-73;
SG_MUL_VAL_ 1537 SlaveAssignment_1F81_48 SubIndex_1F81 72-72;
SG_MUL_VAL_ 1537 SlaveAssignment_1F81_47 SubIndex_1F81 71-71;
SG_MUL_VAL_ 1537 SlaveAssignment_1F81_46 SubIndex_1F81 70-70;
SG_MUL_VAL_ 1537 SlaveAssignment_1F81_45 SubIndex_1F81 69-69;
SG_MUL_VAL_ 1537 SlaveAssignment_1F81_44 SubIndex_1F81 68-68;
SG_MUL_VAL_ 1537 SlaveAssignment_1F81_43 SubIndex_1F81 67-67;
SG_MUL_VAL_ 1537 SlaveAssignment_1F81_42 SubIndex_1F81 66-66;
SG_MUL_VAL_ 1537 SlaveAssignment_1F81_41 SubIndex_1F81 65-65;
SG_MUL_VAL_ 1537 SlaveAssignment_1F81_40 SubIndex_1F81 64-64;
SG_MUL_VAL_ 1537 SlaveAssignment_1F81_3F SubIndex_1F81 63-63;
SG_MUL_VAL_ 1537 SlaveAssignment_1F81_3E SubIndex_1F81 62-62;
SG_MUL_VAL_ 1537 SlaveAssignment_1F81_3D SubIndex_1F81 61-61;
SG_MUL_VAL_ 1537 SlaveAssignment_1F81_3C SubIndex_1F81 60-60;
SG_MUL_VAL_ 1537 SlaveAssignment_1F81_3B SubIndex_1F81 59-59;
SG_MUL_VAL_ 1537 SlaveAssignment_1F81_3A SubIndex_1F81 58-58;
SG_MUL_VAL_ 1537 SlaveAssignment_1F81_39 SubIndex_1F81 57-57;
SG_MUL_VAL_ 1537 SlaveAssignment_1F81_38 SubIndex_1F81 56-56;
SG_MUL_VAL_ 1537 SlaveAssignment_1F81_37 SubIndex_1F81 55-55;
SG_MUL_VAL_ 1537 SlaveAssignment_1F81_36 SubIndex_1F81 54-54;
SG_MUL_VAL_ 1537 SlaveAssignment_1F81_35 SubIndex_1F81 53-53;
SG_MUL_VAL_ 1537 SlaveAssignment_1F81_34 SubIndex_1F81 52-52;
SG_MUL_VAL_ 1537 SlaveAssignment_1F81_33 SubIndex_1F81 51-51;
SG_MUL_VAL_ 1537 SlaveAssignment_1F81_32 SubIndex_1F81 50-50;
SG_MUL_VAL_ 1537 SlaveAssignment_1F81_31 SubIndex_1F81 49-49;
SG_MUL_VAL_ 1537 SlaveAssignment_1F81_30 SubIndex_1F81 48-48;
SG_MUL_VAL_ 1537 SlaveAssignment_1F81_2F SubIndex_1F81 47-47;
SG_MUL_VAL_ 1537 SlaveAssignment_1F81_2E SubIndex_1F81 46-46;
SG_MUL_VAL_ 1537 SlaveAssignment_1F81_2D SubIndex_1F81 45-45;
SG_MUL_VAL_ 1537 SlaveAssignment_1F81_2C SubIndex_1F81 44-44;
SG_MUL_VAL_ 1537 SlaveAssignment_1F81_2B SubIndex_1F81 43-43;
SG_MUL_VAL_ 1537 SlaveAssignment_1F81_2A SubIndex_1F81 42-42;
SG_MUL_VAL_ 1537 SlaveAssignment_1F81_29 SubIndex_1F81 41-41;
SG_MUL_VAL_ 1537 SlaveAssignment_1F81_28 SubIndex_1F81 40-40;
SG_MUL_VAL_ 1537 SlaveAssignment_1F81_27 SubIndex_1F81 39-39;
SG_MUL_VAL_ 1537 SlaveAssignment_1F81_26 SubIndex_1F81 38-38;
SG_MUL_VAL_ 1537 SlaveAssignment_1F81_25 SubIndex_1F81 37-37;
SG_MUL_VAL_ 1537 SlaveAssignment_1F81_24 SubIndex_1F81 36-36;
SG_MUL_VAL_ 1537 SlaveAssignment_1F81_23 SubIndex_1F81 35-35;
SG_MUL_VAL_ 1537 SlaveAssignment_1F81_22 SubIndex_1F81 34-34;
SG_MUL_VAL_ 1537 SlaveAssignment_1F81_21 SubIndex_1F81 33-33;
SG_MUL_VAL_ 1537 SlaveAssignment_1F81_20 SubIndex_1F81 32-32;
SG_MUL_VAL_ 1537 SlaveAssignment_1F81_1F SubIndex_1F81 31-31;
SG_MUL_VAL_ 1537 SlaveAssignment_1F81_1E SubIndex_1F81 30-30;
SG_MUL_VAL_ 1537 SlaveAssignment_1F81_1D SubIndex_1F81 29-29;
SG_MUL_VAL_ 1537 SlaveAssignment_1F81_1C SubIndex_1F81 28-28;
SG_MUL_VAL_ 1537 SlaveAssignment_1F81_1B SubIndex_1F81 27-27;
SG_MUL_VAL_ 1537 SlaveAssignment_1F81_1A SubIndex_1F81 26-26;
SG_MUL_VAL_ 1537 SlaveAssignment_1F81_19 SubIndex_1F81 25-25;
SG_MUL_VAL_ 1537 SlaveAssignment_1F81_18 SubIndex_1F81 24-24;
SG_MUL_VAL_ 1537 SlaveAssignment_1F81_17 SubIndex_1F81 23-23;
SG_MUL_VAL_ 1537 SlaveAssignment_1F81_16 SubIndex_1F81 22-22;
SG_MUL_VAL_ 1537 SlaveAssignment_1F81_15 SubIndex_1F81 21-21;
SG_MUL_VAL_ 1537 SlaveAssignment_1F81_14 SubIndex_1F81 20-20;
SG_MUL_VAL_ 1537 SlaveAssignment_1F81_13 SubIndex_1F81 19-19;
SG_MUL_VAL_ 1537 SlaveAssignment_1F81_12 SubIndex_1F81 18-18;
SG_MUL_VAL_ 1537 SlaveAssignment_1F81_11 SubIndex_1F81 17-17;
SG_MUL_VAL_ 1537 SlaveAssignment_1F81_10 SubIndex_1F81 16-16;
SG_MUL_VAL_ 1537 SlaveAssignment_1F81_0F SubIndex_1F81 15-15;
SG_MUL_VAL_ 1537 SlaveAssignment_1F81_0E SubIndex_1F81 14-14;
SG_MUL_VAL_ 1537 SlaveAssignment_1F81_0D SubIndex_1F81 13-13;
SG_MUL_VAL_ 1537 SlaveAssignment_1F81_0C SubIndex_1F81 12-12;
SG_MUL_VAL_ 1537 SlaveAssignment_1F81_0B SubIndex_1F81 11-11;
SG_MUL_VAL_ 1537 SlaveAssignment_1F81_0A SubIndex_1F81 10-10;
SG_MUL_VAL_ 1537 SlaveAssignment_1F81_09 SubIndex_1F81 9-9;
SG_MUL_VAL_ 1537 SlaveAssignment_1F81_08 SubIndex_1F81 8-8;
SG_MUL_VAL_ 1537 SlaveAssignment_1F81_07 SubIndex_1F81 7-7;
SG_MUL_VAL_ 1537 SlaveAssignment_1F81_06 SubIndex_1F81 6-6;
SG_MUL_VAL_ 1537 SlaveAssignment_1F81_05 SubIndex_1F81 5-5;
SG_MUL_VAL_ 1537 SlaveAssignment_1F81_04 SubIndex_1F81 4-4;
SG_MUL_VAL_ 1537 SlaveAssignment_1F81_03 SubIndex_1F81 3-3;
SG_MUL_VAL_ 1537 SlaveAssignment_1F81_02 SubIndex_1F81 2-2;
SG_MUL_VAL_ 1537 SlaveAssignment_1F81_01 SubIndex_1F81 1-1;
SG_MUL_VAL_ 1537 NrOfObjects_1F81_00 SubIndex_1F81 0-0;
SG_MUL_VAL_ 1537 SubIndex_1F81 Index 8065-8065;
SG_MUL_VAL_ 1537 NMTStartup_1F80 SubIndex_1F80 0-0;
SG_MUL_VAL_ 1537 SubIndex_1F80 Index 8064-8064;
SG_MUL_VAL_ 1537 Configure_Slave_1F25_80 SubIndex_1F25 128-128;
SG_MUL_VAL_ 1537 Configure_Slave_1F25_7F SubIndex_1F25 127-127;
SG_MUL_VAL_ 1537 Configure_Slave_1F25_7E SubIndex_1F25 126-126;
SG_MUL_VAL_ 1537 Configure_Slave_1F25_7D SubIndex_1F25 125-125;
SG_MUL_VAL_ 1537 Configure_Slave_1F25_7C SubIndex_1F25 124-124;
SG_MUL_VAL_ 1537 Configure_Slave_1F25_7B SubIndex_1F25 123-123;
SG_MUL_VAL_ 1537 Configure_Slave_1F25_7A SubIndex_1F25 122-122;
SG_MUL_VAL_ 1537 Configure_Slave_1F25_79 SubIndex_1F25 121-121;
SG_MUL_VAL_ 1537 Configure_Slave_1F25_78 SubIndex_1F25 120-120;
SG_MUL_VAL_ 1537 Configure_Slave_1F25_77 SubIndex_1F25 119-119;
SG_MUL_VAL_ 1537 Configure_Slave_1F25_76 SubIndex_1F25 118-118;
SG_MUL_VAL_ 1537 Configure_Slave_1F25_75 SubIndex_1F25 117-117;
SG_MUL_VAL_ 1537 Configure_Slave_1F25_74 SubIndex_1F25 116-116;
SG_MUL_VAL_ 1537 Configure_Slave_1F25_73 SubIndex_1F25 115-115;
SG_MUL_VAL_ 1537 Configure_Slave_1F25_72 SubIndex_1F25 114-114;
SG_MUL_VAL_ 1537 Configure_Slave_1F25_71 SubIndex_1F25 113-113;
SG_MUL_VAL_ 1537 Configure_Slave_1F25_70 SubIndex_1F25 112-112;
SG_MUL_VAL_ 1537 Configure_Slave_1F25_6F SubIndex_1F25 111-111;
SG_MUL_VAL_ 1537 Configure_Slave_1F25_6E SubIndex_1F25 110-110;
SG_MUL_VAL_ 1537 Configure_Slave_1F25_6D SubIndex_1F25 109-109;
SG_MUL_VAL_ 1537 Configure_Slave_1F25_6C SubIndex_1F25 108-108;
SG_MUL_VAL_ 1537 Configure_Slave_1F25_6B SubIndex_1F25 107-107;
SG_MUL_VAL_ 1537 Configure_Slave_1F25_6A SubIndex_1F25 106-106;
SG_MUL_VAL_ 1537 Configure_Slave_1F25_69 SubIndex_1F25 105-105;
SG_MUL_VAL_ 1537 Configure_Slave_1F25_68 SubIndex_1F25 104-104;
SG_MUL_VAL_ 1537 Configure_Slave_1F25_67 SubIndex_1F25 103-103;
SG_MUL_VAL_ 1537 Configure_Slave_1F25_66 SubIndex_1F25 102-102;
SG_MUL_VAL_ 1537 Configure_Slave_1F25_65 SubIndex_1F25 101-101;
SG_MUL_VAL_ 1537 Configure_Slave_1F25_64 SubIndex_1F25 100-100;
SG_MUL_VAL_ 1537 Configure_Slave_1F25_63 SubIndex_1F25 99-99;
SG_MUL_VAL_ 1537 Configure_Slave_1F25_62 SubIndex_1F25 98-98;
SG_MUL_VAL_ 1537 Configure_Slave_1F25_61 SubIndex_1F25 97-97;
SG_MUL_VAL_ 1537 Configure_Slave_1F25_60 SubIndex_1F25 96-96;
SG_MUL_VAL_ 1537 Configure_Slave_1F25_5F SubIndex_1F25 95-95;
SG_MUL_VAL_ 1537 Configure_Slave_1F25_5E SubIndex_1F25 94-94;
SG_MUL_VAL_ 1537 Configure_Slave_1F25_5D SubIndex_1F25 93-93;
SG_MUL_VAL_ 1537 Configure_Slave_1F25_5C SubIndex_1F25 92-92;
SG_MUL_VAL_ 1537 Configure_Slave_1F25_5B SubIndex_1F25 91-91;
SG_MUL_VAL_ 1537 Configure_Slave_1F25_5A SubIndex_1F25 90-90;
SG_MUL_VAL_ 1537 Configure_Slave_1F25_59 SubIndex_1F25 89-89;
SG_MUL_VAL_ 1537 Configure_Slave_1F25_58 SubIndex_1F25 88-88;
SG_MUL_VAL_ 1537 Configure_Slave_1F25_57 SubIndex_1F25 87-87;
SG_MUL_VAL_ 1537 Configure_Slave_1F25_56 SubIndex_1F25 86-86;
SG_MUL_VAL_ 1537 Configure_Slave_1F25_55 SubIndex_1F25 85-85;
SG_MUL_VAL_ 1537 Configure_Slave_1F25_54 SubIndex_1F25 84-84;
SG_MUL_VAL_ 1537 Configure_Slave_1F25_53 SubIndex_1F25 83-83;
SG_MUL_VAL_ 1537 Configure_Slave_1F25_52 SubIndex_1F25 82-82;
SG_MUL_VAL_ 1537 Configure_Slave_1F25_51 SubIndex_1F25 81-81;
SG_MUL_VAL_ 1537 Configure_Slave_1F25_50 SubIndex_1F25 80-80;
SG_MUL_VAL_ 1537 Configure_Slave_1F25_4F SubIndex_1F25 79-79;
SG_MUL_VAL_ 1537 Configure_Slave_1F25_4E SubIndex_1F25 78-78;
SG_MUL_VAL_ 1537 Configure_Slave_1F25_4D SubIndex_1F25 77-77;
SG_MUL_VAL_ 1537 Configure_Slave_1F25_4C SubIndex_1F25 76-76;
SG_MUL_VAL_ 1537 Configure_Slave_1F25_4B SubIndex_1F25 75-75;
SG_MUL_VAL_ 1537 Configure_Slave_1F25_4A SubIndex_1F25 74-74;
SG_MUL_VAL_ 1537 Configure_Slave_1F25_49 SubIndex_1F25 73-73;
SG_MUL_VAL_ 1537 Configure_Slave_1F25_48 SubIndex_1F25 72-72;
SG_MUL_VAL_ 1537 Configure_Slave_1F25_47 SubIndex_1F25 71-71;
SG_MUL_VAL_ 1537 Configure_Slave_1F25_46 SubIndex_1F25 70-70;
SG_MUL_VAL_ 1537 Configure_Slave_1F25_45 SubIndex_1F25 69-69;
SG_MUL_VAL_ 1537 Configure_Slave_1F25_44 SubIndex_1F25 68-68;
SG_MUL_VAL_ 1537 Configure_Slave_1F25_43 SubIndex_1F25 67-67;
SG_MUL_VAL_ 1537 Configure_Slave_1F25_42 SubIndex_1F25 66-66;
SG_MUL_VAL_ 1537 Configure_Slave_1F25_41 SubIndex_1F25 65-65;
SG_MUL_VAL_ 1537 Configure_Slave_1F25_40 SubIndex_1F25 64-64;
SG_MUL_VAL_ 1537 Configure_Slave_1F25_3F SubIndex_1F25 63-63;
SG_MUL_VAL_ 1537 Configure_Slave_1F25_3E SubIndex_1F25 62-62;
SG_MUL_VAL_ 1537 Configure_Slave_1F25_3D SubIndex_1F25 61-61;
SG_MUL_VAL_ 1537 Configure_Slave_1F25_3C SubIndex_1F25 60-60;
SG_MUL_VAL_ 1537 Configure_Slave_1F25_3B SubIndex_1F25 59-59;
SG_MUL_VAL_ 1537 Configure_Slave_1F25_3A SubIndex_1F25 58-58;
SG_MUL_VAL_ 1537 Configure_Slave_1F25_39 SubIndex_1F25 57-57;
SG_MUL_VAL_ 1537 Configure_Slave_1F25_38 SubIndex_1F25 56-56;
SG_MUL_VAL_ 1537 Configure_Slave_1F25_37 SubIndex_1F25 55-55;
SG_MUL_VAL_ 1537 Configure_Slave_1F25_36 SubIndex_1F25 54-54;
SG_MUL_VAL_ 1537 Configure_Slave_1F25_35 SubIndex_1F25 53-53;
SG_MUL_VAL_ 1537 Configure_Slave_1F25_34 SubIndex_1F25 52-52;
SG_MUL_VAL_ 1537 Configure_Slave_1F25_33 SubIndex_1F25 51-51;
SG_MUL_VAL_ 1537 Configure_Slave_1F25_32 SubIndex_1F25 50-50;
SG_MUL_VAL_ 1537 Configure_Slave_1F25_31 SubIndex_1F25 49-49;
SG_MUL_VAL_ 1537 Configure_Slave_1F25_30 SubIndex_1F25 48-48;
SG_MUL_VAL_ 1537 Configure_Slave_1F25_2F SubIndex_1F25 47-47;
SG_MUL_VAL_ 1537 Configure_Slave_1F25_2E SubIndex_1F25 46-46;
SG_MUL_VAL_ 1537 Configure_Slave_1F25_2D SubIndex_1F25 45-45;
SG_MUL_VAL_ 1537 Configure_Slave_1F25_2C SubIndex_1F25 44-44;
SG_MUL_VAL_ 1537 Configure_Slave_1F25_2B SubIndex_1F25 43-43;
SG_MUL_VAL_ 1537 Configure_Slave_1F25_2A SubIndex_1F25 42-42;
SG_MUL_VAL_ 1537 Configure_Slave_1F25_29 SubIndex_1F25 41-41;
SG_MUL_VAL_ 1537 Configure_Slave_1F25_28 SubIndex_1F25 40-40;
SG_MUL_VAL_ 1537 Configure_Slave_1F25_27 SubIndex_1F25 39-39;
SG_MUL_VAL_ 1537 Configure_Slave_1F25_26 SubIndex_1F25 38-38;
SG_MUL_VAL_ 1537 Configure_Slave_1F25_25 SubIndex_1F25 37-37;
SG_MUL_VAL_ 1537 Configure_Slave_1F25_24 SubIndex_1F25 36-36;
SG_MUL_VAL_ 1537 Configure_Slave_1F25_23 SubIndex_1F25 35-35;
SG_MUL_VAL_ 1537 Configure_Slave_1F25_22 SubIndex_1F25 34-34;
SG_MUL_VAL_ 1537 Configure_Slave_1F25_21 SubIndex_1F25 33-33;
SG_MUL_VAL_ 1537 Configure_Slave_1F25_20 SubIndex_1F25 32-32;
SG_MUL_VAL_ 1537 Configure_Slave_1F25_1F SubIndex_1F25 31-31;
SG_MUL_VAL_ 1537 Configure_Slave_1F25_1E SubIndex_1F25 30-30;
SG_MUL_VAL_ 1537 Configure_Slave_1F25_1D SubIndex_1F25 29-29;
SG_MUL_VAL_ 1537 Configure_Slave_1F25_1C SubIndex_1F25 28-28;
SG_MUL_VAL_ 1537 Configure_Slave_1F25_1B SubIndex_1F25 27-27;
SG_MUL_VAL_ 1537 Configure_Slave_1F25_1A SubIndex_1F25 26-26;
SG_MUL_VAL_ 1537 Configure_Slave_1F25_19 SubIndex_1F25 25-25;
SG_MUL_VAL_ 1537 Configure_Slave_1F25_18 SubIndex_1F25 24-24;
SG_MUL_VAL_ 1537 Configure_Slave_1F25_17 SubIndex_1F25 23-23;
SG_MUL_VAL_ 1537 Configure_Slave_1F25_16 SubIndex_1F25 22-22;
SG_MUL_VAL_ 1537 Configure_Slave_1F25_15 SubIndex_1F25 21-21;
SG_MUL_VAL_ 1537 Configure_Slave_1F25_14 SubIndex_1F25 20-20;
SG_MUL_VAL_ 1537 Configure_Slave_1F25_13 SubIndex_1F25 19-19;
SG_MUL_VAL_ 1537 Configure_Slave_1F25_12 SubIndex_1F25 18-18;
SG_MUL_VAL_ 1537 Configure_Slave_1F25_11 SubIndex_1F25 17-17;
SG_MUL_VAL_ 1537 Configure_Slave_1F25_10 SubIndex_1F25 16-16;
SG_MUL_VAL_ 1537 Configure_Slave_1F25_0F SubIndex_1F25 15-15;
SG_MUL_VAL_ 1537 Configure_Slave_1F25_0E SubIndex_1F25 14-14;
SG_MUL_VAL_ 1537 Configure_Slave_1F25_0D SubIndex_1F25 13-13;
SG_MUL_VAL_ 1537 Configure_Slave_1F25_0C SubIndex_1F25 12-12;
SG_MUL_VAL_ 1537 Configure_Slave_1F25_0B SubIndex_1F25 11-11;
SG_MUL_VAL_ 1537 Configure_Slave_1F25_0A SubIndex_1F25 10-10;
SG_MUL_VAL_ 1537 Configure_Slave_1F25_09 SubIndex_1F25 9-9;
SG_MUL_VAL_ 1537 Configure_Slave_1F25_08 SubIndex_1F25 8-8;
SG_MUL_VAL_ 1537 Configure_Slave_1F25_07 SubIndex_1F25 7-7;
SG_MUL_VAL_ 1537 Configure_Slave_1F25_06 SubIndex_1F25 6-6;
SG_MUL_VAL_ 1537 Configure_Slave_1F25_05 SubIndex_1F25 5-5;
SG_MUL_VAL_ 1537 Configure_Slave_1F25_04 SubIndex_1F25 4-4;
SG_MUL_VAL_ 1537 Configure_Slave_1F25_03 SubIndex_1F25 3-3;
SG_MUL_VAL_ 1537 Configure_Slave_1F25_02 SubIndex_1F25 2-2;
SG_MUL_VAL_ 1537 Configure_Network_1F25_01 SubIndex_1F25 1-1;
SG_MUL_VAL_ 1537 NrOfObjects_1F25_00 SubIndex_1F25 0-0;
SG_MUL_VAL_ 1537 SubIndex_1F25 Index 7973-7973;
SG_MUL_VAL_ 1537 NrOfObjects_1F22_00 SubIndex_1F22 0-0;
SG_MUL_VAL_ 1537 SubIndex_1F22 Index 7970-7970;
SG_MUL_VAL_ 1537 GENERATED_1A04_03 SubIndex_1A04 3-3;
SG_MUL_VAL_ 1537 GENERATED_1A04_02 SubIndex_1A04 2-2;
SG_MUL_VAL_ 1537 GENERATED_1A04_01 SubIndex_1A04 1-1;
SG_MUL_VAL_ 1537 NrOfMappedObjects_1A04_00 SubIndex_1A04 0-0;
SG_MUL_VAL_ 1537 SubIndex_1A04 Index 6660-6660;
SG_MUL_VAL_ 1537 GENERATED_1A03_03 SubIndex_1A03 3-3;
SG_MUL_VAL_ 1537 mappedObj2_1A03_02 SubIndex_1A03 2-2;
SG_MUL_VAL_ 1537 mappedObj1_1A03_01 SubIndex_1A03 1-1;
SG_MUL_VAL_ 1537 NrOfMappedObjects_1A03_00 SubIndex_1A03 0-0;
SG_MUL_VAL_ 1537 SubIndex_1A03 Index 6659-6659;
SG_MUL_VAL_ 1537 mappedObj2_1A02_02 SubIndex_1A02 2-2;
SG_MUL_VAL_ 1537 mappedObj1_1A02_01 SubIndex_1A02 1-1;
SG_MUL_VAL_ 1537 NrOfMappedObjects_1A02_00 SubIndex_1A02 0-0;
SG_MUL_VAL_ 1537 SubIndex_1A02 Index 6658-6658;
SG_MUL_VAL_ 1537 mappedObj2_1A01_02 SubIndex_1A01 2-2;
SG_MUL_VAL_ 1537 mappedObj1_1A01_01 SubIndex_1A01 1-1;
SG_MUL_VAL_ 1537 NrOfMappedObjects_1A01_00 SubIndex_1A01 0-0;
SG_MUL_VAL_ 1537 SubIndex_1A01 Index 6657-6657;
SG_MUL_VAL_ 1537 mappedObj2_1A00_02 SubIndex_1A00 2-2;
SG_MUL_VAL_ 1537 mappedObj1_1A00_01 SubIndex_1A00 1-1;
SG_MUL_VAL_ 1537 NrOfMappedObjects_1A00_00 SubIndex_1A00 0-0;
SG_MUL_VAL_ 1537 SubIndex_1A00 Index 6656-6656;
SG_MUL_VAL_ 1537 EventTimer_1804_05 SubIndex_1804 5-5;
SG_MUL_VAL_ 1537 TransmissionType_1804_02 SubIndex_1804 2-2;
SG_MUL_VAL_ 1537 COB_ID_1804_01 SubIndex_1804 1-1;
SG_MUL_VAL_ 1537 Highest_sub_index_supported_0014 SubIndex_1804 0-0;
SG_MUL_VAL_ 1537 SubIndex_1804 Index 6148-6148;
SG_MUL_VAL_ 1537 EventTimer_1803_05 SubIndex_1803 5-5;
SG_MUL_VAL_ 1537 TransmissionType_1803_02 SubIndex_1803 2-2;
SG_MUL_VAL_ 1537 COB_ID_1803_01 SubIndex_1803 1-1;
SG_MUL_VAL_ 1537 Highest_sub_index_supported_0015 SubIndex_1803 0-0;
SG_MUL_VAL_ 1537 SubIndex_1803 Index 6147-6147;
SG_MUL_VAL_ 1537 EventTimer_1802_05 SubIndex_1802 5-5;
SG_MUL_VAL_ 1537 TransmissionType_1802_02 SubIndex_1802 2-2;
SG_MUL_VAL_ 1537 COB_ID_1802_01 SubIndex_1802 1-1;
SG_MUL_VAL_ 1537 Highest_sub_index_supported_0016 SubIndex_1802 0-0;
SG_MUL_VAL_ 1537 SubIndex_1802 Index 6146-6146;
SG_MUL_VAL_ 1537 EventTimer_1801_05 SubIndex_1801 5-5;
SG_MUL_VAL_ 1537 TransmissionType_1801_02 SubIndex_1801 2-2;
SG_MUL_VAL_ 1537 COB_ID_1801_01 SubIndex_1801 1-1;
SG_MUL_VAL_ 1537 Highest_sub_index_supported_0017 SubIndex_1801 0-0;
SG_MUL_VAL_ 1537 SubIndex_1801 Index 6145-6145;
SG_MUL_VAL_ 1537 EventTimer_1800_05 SubIndex_1800 5-5;
SG_MUL_VAL_ 1537 TransmissionType_1800_02 SubIndex_1800 2-2;
SG_MUL_VAL_ 1537 COB_ID_1800_01 SubIndex_1800 1-1;
SG_MUL_VAL_ 1537 Highest_sub_index_supported_0018 SubIndex_1800 0-0;
SG_MUL_VAL_ 1537 SubIndex_1800 Index 6144-6144;
SG_MUL_VAL_ 1537 GENERATED_1604_05 SubIndex_1604 5-5;
SG_MUL_VAL_ 1537 GENERATED_1604_04 SubIndex_1604 4-4;
SG_MUL_VAL_ 1537 GENERATED_1604_03 SubIndex_1604 3-3;
SG_MUL_VAL_ 1537 GENERATED_1604_02 SubIndex_1604 2-2;
SG_MUL_VAL_ 1537 GENERATED_1604_01 SubIndex_1604 1-1;
SG_MUL_VAL_ 1537 NrOfMappedObjects_1604_00 SubIndex_1604 0-0;
SG_MUL_VAL_ 1537 SubIndex_1604 Index 5636-5636;
SG_MUL_VAL_ 1537 mappedObj2_1603_02 SubIndex_1603 2-2;
SG_MUL_VAL_ 1537 mappedObj1_1603_01 SubIndex_1603 1-1;
SG_MUL_VAL_ 1537 NrOfMappedObjects_1603_00 SubIndex_1603 0-0;
SG_MUL_VAL_ 1537 SubIndex_1603 Index 5635-5635;
SG_MUL_VAL_ 1537 mappedObj2_1602_02 SubIndex_1602 2-2;
SG_MUL_VAL_ 1537 mappedObj1_1602_01 SubIndex_1602 1-1;
SG_MUL_VAL_ 1537 NrOfMappedObjects_1602_00 SubIndex_1602 0-0;
SG_MUL_VAL_ 1537 SubIndex_1602 Index 5634-5634;
SG_MUL_VAL_ 1537 GENERATED_1601_03 SubIndex_1601 3-3;
SG_MUL_VAL_ 1537 mappedObj2_1601_02 SubIndex_1601 2-2;
SG_MUL_VAL_ 1537 mappedObj1_1601_01 SubIndex_1601 1-1;
SG_MUL_VAL_ 1537 NrOfMappedObjects_1601_00 SubIndex_1601 0-0;
SG_MUL_VAL_ 1537 SubIndex_1601 Index 5633-5633;
SG_MUL_VAL_ 1537 GENERATED_1600_05 SubIndex_1600 5-5;
SG_MUL_VAL_ 1537 mappedObj4_1600_04 SubIndex_1600 4-4;
SG_MUL_VAL_ 1537 mappedObj3_1600_03 SubIndex_1600 3-3;
SG_MUL_VAL_ 1537 mappedObj2_1600_02 SubIndex_1600 2-2;
SG_MUL_VAL_ 1537 mappedObj1_1600_01 SubIndex_1600 1-1;
SG_MUL_VAL_ 1537 NrOfMappedObjects_1600_00 SubIndex_1600 0-0;
SG_MUL_VAL_ 1537 SubIndex_1600 Index 5632-5632;
SG_MUL_VAL_ 1537 TransmissionType_1404_02 SubIndex_1404 2-2;
SG_MUL_VAL_ 1537 COB_ID_1404_01 SubIndex_1404 1-1;
SG_MUL_VAL_ 1537 Highest_sub_index_supported_0019 SubIndex_1404 0-0;
SG_MUL_VAL_ 1537 SubIndex_1404 Index 5124-5124;
SG_MUL_VAL_ 1537 TransmissionType_1403_02 SubIndex_1403 2-2;
SG_MUL_VAL_ 1537 COB_ID_1403_01 SubIndex_1403 1-1;
SG_MUL_VAL_ 1537 Highest_sub_index_supported_0020 SubIndex_1403 0-0;
SG_MUL_VAL_ 1537 SubIndex_1403 Index 5123-5123;
SG_MUL_VAL_ 1537 TransmissionType_1402_02 SubIndex_1402 2-2;
SG_MUL_VAL_ 1537 COB_ID_1402_01 SubIndex_1402 1-1;
SG_MUL_VAL_ 1537 Highest_sub_index_supported_0021 SubIndex_1402 0-0;
SG_MUL_VAL_ 1537 SubIndex_1402 Index 5122-5122;
SG_MUL_VAL_ 1537 TransmissionType_1401_02 SubIndex_1401 2-2;
SG_MUL_VAL_ 1537 COB_ID_1401_01 SubIndex_1401 1-1;
SG_MUL_VAL_ 1537 Highest_sub_index_supported_0022 SubIndex_1401 0-0;
SG_MUL_VAL_ 1537 SubIndex_1401 Index 5121-5121;
SG_MUL_VAL_ 1537 TransmissionType_1400_02 SubIndex_1400 2-2;
SG_MUL_VAL_ 1537 COB_ID_1400_01 SubIndex_1400 1-1;
SG_MUL_VAL_ 1537 Highest_sub_index_supported_0023 SubIndex_1400 0-0;
SG_MUL_VAL_ 1537 SubIndex_1400 Index 5120-5120;
SG_MUL_VAL_ 1537 Configuration_time_1020_02 SubIndex_1020 2-2;
SG_MUL_VAL_ 1537 Configuration_date_1020_01 SubIndex_1020 1-1;
SG_MUL_VAL_ 1537 NrOfObjects_1020_00 SubIndex_1020 0-0;
SG_MUL_VAL_ 1537 SubIndex_1020 Index 4128-4128;
SG_MUL_VAL_ 1537 Serial_number_1018_04 SubIndex_1018 4-4;
SG_MUL_VAL_ 1537 Revision_number_1018_03 SubIndex_1018 3-3;
SG_MUL_VAL_ 1537 Product_Code_1018_02 SubIndex_1018 2-2;
SG_MUL_VAL_ 1537 Vendor_Id_1018_01 SubIndex_1018 1-1;
SG_MUL_VAL_ 1537 Highest_sub_index_supported_0024 SubIndex_1018 0-0;
SG_MUL_VAL_ 1537 SubIndex_1018 Index 4120-4120;
SG_MUL_VAL_ 1537 Producer_Heartbeat_Time_1017 SubIndex_1017 0-0;
SG_MUL_VAL_ 1537 SubIndex_1017 Index 4119-4119;
SG_MUL_VAL_ 1537 Consumer_Heartbeat_Time_1016_7E SubIndex_1016 126-126;
SG_MUL_VAL_ 1537 Consumer_Heartbeat_Time_1016_7D SubIndex_1016 125-125;
SG_MUL_VAL_ 1537 Consumer_Heartbeat_Time_1016_7C SubIndex_1016 124-124;
SG_MUL_VAL_ 1537 Consumer_Heartbeat_Time_1016_7B SubIndex_1016 123-123;
SG_MUL_VAL_ 1537 Consumer_Heartbeat_Time_1016_7A SubIndex_1016 122-122;
SG_MUL_VAL_ 1537 Consumer_Heartbeat_Time_1016_79 SubIndex_1016 121-121;
SG_MUL_VAL_ 1537 Consumer_Heartbeat_Time_1016_78 SubIndex_1016 120-120;
SG_MUL_VAL_ 1537 Consumer_Heartbeat_Time_1016_77 SubIndex_1016 119-119;
SG_MUL_VAL_ 1537 Consumer_Heartbeat_Time_1016_76 SubIndex_1016 118-118;
SG_MUL_VAL_ 1537 Consumer_Heartbeat_Time_1016_75 SubIndex_1016 117-117;
SG_MUL_VAL_ 1537 Consumer_Heartbeat_Time_1016_74 SubIndex_1016 116-116;
SG_MUL_VAL_ 1537 Consumer_Heartbeat_Time_1016_73 SubIndex_1016 115-115;
SG_MUL_VAL_ 1537 Consumer_Heartbeat_Time_1016_72 SubIndex_1016 114-114;
SG_MUL_VAL_ 1537 Consumer_Heartbeat_Time_1016_71 SubIndex_1016 113-113;
SG_MUL_VAL_ 1537 Consumer_Heartbeat_Time_1016_70 SubIndex_1016 112-112;
SG_MUL_VAL_ 1537 Consumer_Heartbeat_Time_1016_6F SubIndex_1016 111-111;
SG_MUL_VAL_ 1537 Consumer_Heartbeat_Time_1016_6E SubIndex_1016 110-110;
SG_MUL_VAL_ 1537 Consumer_Heartbeat_Time_1016_6D SubIndex_1016 109-109;
SG_MUL_VAL_ 1537 Consumer_Heartbeat_Time_1016_6C SubIndex_1016 108-108;
SG_MUL_VAL_ 1537 Consumer_Heartbeat_Time_1016_6B SubIndex_1016 107-107;
SG_MUL_VAL_ 1537 Consumer_Heartbeat_Time_1016_6A SubIndex_1016 106-106;
SG_MUL_VAL_ 1537 Consumer_Heartbeat_Time_1016_69 SubIndex_1016 105-105;
SG_MUL_VAL_ 1537 Consumer_Heartbeat_Time_1016_68 SubIndex_1016 104-104;
SG_MUL_VAL_ 1537 Consumer_Heartbeat_Time_1016_67 SubIndex_1016 103-103;
SG_MUL_VAL_ 1537 Consumer_Heartbeat_Time_1016_66 SubIndex_1016 102-102;
SG_MUL_VAL_ 1537 Consumer_Heartbeat_Time_1016_65 SubIndex_1016 101-101;
SG_MUL_VAL_ 1537 Consumer_Heartbeat_Time_1016_64 SubIndex_1016 100-100;
SG_MUL_VAL_ 1537 Consumer_Heartbeat_Time_1016_63 SubIndex_1016 99-99;
SG_MUL_VAL_ 1537 Consumer_Heartbeat_Time_1016_62 SubIndex_1016 98-98;
SG_MUL_VAL_ 1537 Consumer_Heartbeat_Time_1016_61 SubIndex_1016 97-97;
SG_MUL_VAL_ 1537 Consumer_Heartbeat_Time_1016_60 SubIndex_1016 96-96;
SG_MUL_VAL_ 1537 Consumer_Heartbeat_Time_1016_5F SubIndex_1016 95-95;
SG_MUL_VAL_ 1537 Consumer_Heartbeat_Time_1016_5E SubIndex_1016 94-94;
SG_MUL_VAL_ 1537 Consumer_Heartbeat_Time_1016_5D SubIndex_1016 93-93;
SG_MUL_VAL_ 1537 Consumer_Heartbeat_Time_1016_5C SubIndex_1016 92-92;
SG_MUL_VAL_ 1537 Consumer_Heartbeat_Time_1016_5B SubIndex_1016 91-91;
SG_MUL_VAL_ 1537 Consumer_Heartbeat_Time_1016_5A SubIndex_1016 90-90;
SG_MUL_VAL_ 1537 Consumer_Heartbeat_Time_1016_59 SubIndex_1016 89-89;
SG_MUL_VAL_ 1537 Consumer_Heartbeat_Time_1016_58 SubIndex_1016 88-88;
SG_MUL_VAL_ 1537 Consumer_Heartbeat_Time_1016_57 SubIndex_1016 87-87;
SG_MUL_VAL_ 1537 Consumer_Heartbeat_Time_1016_56 SubIndex_1016 86-86;
SG_MUL_VAL_ 1537 Consumer_Heartbeat_Time_1016_55 SubIndex_1016 85-85;
SG_MUL_VAL_ 1537 Consumer_Heartbeat_Time_1016_54 SubIndex_1016 84-84;
SG_MUL_VAL_ 1537 Consumer_Heartbeat_Time_1016_53 SubIndex_1016 83-83;
SG_MUL_VAL_ 1537 Consumer_Heartbeat_Time_1016_52 SubIndex_1016 82-82;
SG_MUL_VAL_ 1537 Consumer_Heartbeat_Time_1016_51 SubIndex_1016 81-81;
SG_MUL_VAL_ 1537 Consumer_Heartbeat_Time_1016_50 SubIndex_1016 80-80;
SG_MUL_VAL_ 1537 Consumer_Heartbeat_Time_1016_4F SubIndex_1016 79-79;
SG_MUL_VAL_ 1537 Consumer_Heartbeat_Time_1016_4E SubIndex_1016 78-78;
SG_MUL_VAL_ 1537 Consumer_Heartbeat_Time_1016_4D SubIndex_1016 77-77;
SG_MUL_VAL_ 1537 Consumer_Heartbeat_Time_1016_4C SubIndex_1016 76-76;
SG_MUL_VAL_ 1537 Consumer_Heartbeat_Time_1016_4B SubIndex_1016 75-75;
SG_MUL_VAL_ 1537 Consumer_Heartbeat_Time_1016_4A SubIndex_1016 74-74;
SG_MUL_VAL_ 1537 Consumer_Heartbeat_Time_1016_49 SubIndex_1016 73-73;
SG_MUL_VAL_ 1537 Consumer_Heartbeat_Time_1016_48 SubIndex_1016 72-72;
SG_MUL_VAL_ 1537 Consumer_Heartbeat_Time_1016_47 SubIndex_1016 71-71;
SG_MUL_VAL_ 1537 Consumer_Heartbeat_Time_1016_46 SubIndex_1016 70-70;
SG_MUL_VAL_ 1537 Consumer_Heartbeat_Time_1016_45 SubIndex_1016 69-69;
SG_MUL_VAL_ 1537 Consumer_Heartbeat_Time_1016_44 SubIndex_1016 68-68;
SG_MUL_VAL_ 1537 Consumer_Heartbeat_Time_1016_43 SubIndex_1016 67-67;
SG_MUL_VAL_ 1537 Consumer_Heartbeat_Time_1016_42 SubIndex_1016 66-66;
SG_MUL_VAL_ 1537 Consumer_Heartbeat_Time_1016_41 SubIndex_1016 65-65;
SG_MUL_VAL_ 1537 Consumer_Heartbeat_Time_1016_40 SubIndex_1016 64-64;
SG_MUL_VAL_ 1537 Consumer_Heartbeat_Time_1016_3F SubIndex_1016 63-63;
SG_MUL_VAL_ 1537 Consumer_Heartbeat_Time_1016_3E SubIndex_1016 62-62;
SG_MUL_VAL_ 1537 Consumer_Heartbeat_Time_1016_3D SubIndex_1016 61-61;
SG_MUL_VAL_ 1537 Consumer_Heartbeat_Time_1016_3C SubIndex_1016 60-60;
SG_MUL_VAL_ 1537 Consumer_Heartbeat_Time_1016_3B SubIndex_1016 59-59;
SG_MUL_VAL_ 1537 Consumer_Heartbeat_Time_1016_3A SubIndex_1016 58-58;
SG_MUL_VAL_ 1537 Consumer_Heartbeat_Time_1016_39 SubIndex_1016 57-57;
SG_MUL_VAL_ 1537 Consumer_Heartbeat_Time_1016_38 SubIndex_1016 56-56;
SG_MUL_VAL_ 1537 Consumer_Heartbeat_Time_1016_37 SubIndex_1016 55-55;
SG_MUL_VAL_ 1537 Consumer_Heartbeat_Time_1016_36 SubIndex_1016 54-54;
SG_MUL_VAL_ 1537 Consumer_Heartbeat_Time_1016_35 SubIndex_1016 53-53;
SG_MUL_VAL_ 1537 Consumer_Heartbeat_Time_1016_34 SubIndex_1016 52-52;
SG_MUL_VAL_ 1537 Consumer_Heartbeat_Time_1016_33 SubIndex_1016 51-51;
SG_MUL_VAL_ 1537 Consumer_Heartbeat_Time_1016_32 SubIndex_1016 50-50;
SG_MUL_VAL_ 1537 Consumer_Heartbeat_Time_1016_31 SubIndex_1016 49-49;
SG_MUL_VAL_ 1537 Consumer_Heartbeat_Time_1016_30 SubIndex_1016 48-48;
SG_MUL_VAL_ 1537 Consumer_Heartbeat_Time_1016_2F SubIndex_1016 47-47;
SG_MUL_VAL_ 1537 Consumer_Heartbeat_Time_1016_2E SubIndex_1016 46-46;
SG_MUL_VAL_ 1537 Consumer_Heartbeat_Time_1016_2D SubIndex_1016 45-45;
SG_MUL_VAL_ 1537 Consumer_Heartbeat_Time_1016_2C SubIndex_1016 44-44;
SG_MUL_VAL_ 1537 Consumer_Heartbeat_Time_1016_2B SubIndex_1016 43-43;
SG_MUL_VAL_ 1537 Consumer_Heartbeat_Time_1016_2A SubIndex_1016 42-42;
SG_MUL_VAL_ 1537 Consumer_Heartbeat_Time_1016_29 SubIndex_1016 41-41;
SG_MUL_VAL_ 1537 Consumer_Heartbeat_Time_1016_28 SubIndex_1016 40-40;
SG_MUL_VAL_ 1537 Consumer_Heartbeat_Time_1016_27 SubIndex_1016 39-39;
SG_MUL_VAL_ 1537 Consumer_Heartbeat_Time_1016_26 SubIndex_1016 38-38;
SG_MUL_VAL_ 1537 Consumer_Heartbeat_Time_1016_25 SubIndex_1016 37-37;
SG_MUL_VAL_ 1537 Consumer_Heartbeat_Time_1016_24 SubIndex_1016 36-36;
SG_MUL_VAL_ 1537 Consumer_Heartbeat_Time_1016_23 SubIndex_1016 35-35;
SG_MUL_VAL_ 1537 Consumer_Heartbeat_Time_1016_22 SubIndex_1016 34-34;
SG_MUL_VAL_ 1537 Consumer_Heartbeat_Time_1016_21 SubIndex_1016 33-33;
SG_MUL_VAL_ 1537 Consumer_Heartbeat_Time_1016_20 SubIndex_1016 32-32;
SG_MUL_VAL_ 1537 Consumer_Heartbeat_Time_1016_1F SubIndex_1016 31-31;
SG_MUL_VAL_ 1537 Consumer_Heartbeat_Time_1016_1E SubIndex_1016 30-30;
SG_MUL_VAL_ 1537 Consumer_Heartbeat_Time_1016_1D SubIndex_1016 29-29;
SG_MUL_VAL_ 1537 Consumer_Heartbeat_Time_1016_1C SubIndex_1016 28-28;
SG_MUL_VAL_ 1537 Consumer_Heartbeat_Time_1016_1B SubIndex_1016 27-27;
SG_MUL_VAL_ 1537 Consumer_Heartbeat_Time_1016_1A SubIndex_1016 26-26;
SG_MUL_VAL_ 1537 Consumer_Heartbeat_Time_1016_19 SubIndex_1016 25-25;
SG_MUL_VAL_ 1537 Consumer_Heartbeat_Time_1016_18 SubIndex_1016 24-24;
SG_MUL_VAL_ 1537 Consumer_Heartbeat_Time_1016_17 SubIndex_1016 23-23;
SG_MUL_VAL_ 1537 Consumer_Heartbeat_Time_1016_16 SubIndex_1016 22-22;
SG_MUL_VAL_ 1537 Consumer_Heartbeat_Time_1016_15 SubIndex_1016 21-21;
SG_MUL_VAL_ 1537 Consumer_Heartbeat_Time_1016_14 SubIndex_1016 20-20;
SG_MUL_VAL_ 1537 Consumer_Heartbeat_Time_1016_13 SubIndex_1016 19-19;
SG_MUL_VAL_ 1537 Consumer_Heartbeat_Time_1016_12 SubIndex_1016 18-18;
SG_MUL_VAL_ 1537 Consumer_Heartbeat_Time_1016_11 SubIndex_1016 17-17;
SG_MUL_VAL_ 1537 Consumer_Heartbeat_Time_1016_10 SubIndex_1016 16-16;
SG_MUL_VAL_ 1537 Consumer_Heartbeat_Time_1016_0F SubIndex_1016 15-15;
SG_MUL_VAL_ 1537 Consumer_Heartbeat_Time_1016_0E SubIndex_1016 14-14;
SG_MUL_VAL_ 1537 Consumer_Heartbeat_Time_1016_0D SubIndex_1016 13-13;
SG_MUL_VAL_ 1537 Consumer_Heartbeat_Time_1016_0C SubIndex_1016 12-12;
SG_MUL_VAL_ 1537 Consumer_Heartbeat_Time_1016_0B SubIndex_1016 11-11;
SG_MUL_VAL_ 1537 Consumer_Heartbeat_Time_1016_0A SubIndex_1016 10-10;
SG_MUL_VAL_ 1537 Consumer_Heartbeat_Time_1016_09 SubIndex_1016 9-9;
SG_MUL_VAL_ 1537 Consumer_Heartbeat_Time_1016_08 SubIndex_1016 8-8;
SG_MUL_VAL_ 1537 Consumer_Heartbeat_Time_1016_07 SubIndex_1016 7-7;
SG_MUL_VAL_ 1537 Consumer_Heartbeat_Time_1016_06 SubIndex_1016 6-6;
SG_MUL_VAL_ 1537 Consumer_Heartbeat_Time_1016_05 SubIndex_1016 5-5;
SG_MUL_VAL_ 1537 Consumer_Heartbeat_Time_1016_04 SubIndex_1016 4-4;
SG_MUL_VAL_ 1537 Consumer_Heartbeat_Time_1016_03 SubIndex_1016 3-3;
SG_MUL_VAL_ 1537 Consumer_Heartbeat_Time_1016_02 SubIndex_1016 2-2;
SG_MUL_VAL_ 1537 Consumer_Heartbeat_Time_1016_01 SubIndex_1016 1-1;
SG_MUL_VAL_ 1537 NrOfObjects_1016_00 SubIndex_1016 0-0;
SG_MUL_VAL_ 1537 SubIndex_1016 Index 4118-4118;
SG_MUL_VAL_ 1537 Restore_all_Default_Paramet_0000 SubIndex_1011 1-1;
SG_MUL_VAL_ 1537 Highest_sub_index_supported_0025 SubIndex_1011 0-0;
SG_MUL_VAL_ 1537 SubIndex_1011 Index 4113-4113;
SG_MUL_VAL_ 1537 Save_all_Parameters_1010_01 SubIndex_1010 1-1;
SG_MUL_VAL_ 1537 Highest_sub_index_supported_0026 SubIndex_1010 0-0;
SG_MUL_VAL_ 1537 SubIndex_1010 Index 4112-4112;
SG_MUL_VAL_ 1537 Life_Time_Factor_100D SubIndex_100D 0-0;
SG_MUL_VAL_ 1537 SubIndex_100D Index 4109-4109;
SG_MUL_VAL_ 1537 Guard_Time_100C SubIndex_100C 0-0;
SG_MUL_VAL_ 1537 SubIndex_100C Index 4108-4108;
SG_MUL_VAL_ 1537 Sync_Window_Length_1007 SubIndex_1007 0-0;
SG_MUL_VAL_ 1537 SubIndex_1007 Index 4103-4103;
SG_MUL_VAL_ 1537 Communication_Cycle_Period_1006 SubIndex_1006 0-0;
SG_MUL_VAL_ 1537 SubIndex_1006 Index 4102-4102;
SG_MUL_VAL_ 1537 COB_ID_SYNC_1005 SubIndex_1005 0-0;
SG_MUL_VAL_ 1537 SubIndex_1005 Index 4101-4101;
SG_MUL_VAL_ 1537 Manufacturer_Status_Registe_0000 SubIndex_1002 0-0;
SG_MUL_VAL_ 1537 SubIndex_1002 Index 4098-4098;
SG_MUL_VAL_ 1537 Error_Register_1001 SubIndex_1001 0-0;
SG_MUL_VAL_ 1537 SubIndex_1001 Index 4097-4097;
SG_MUL_VAL_ 1537 Device_Type_1000 SubIndex_1000 0-0;
SG_MUL_VAL_ 1537 SubIndex_1000 Index 4096-4096;
SG_MUL_VAL_ 1537 Index TransferType 1-1;
SG_MUL_VAL_ 1537 TransferType CCS 1-2;
SG_MUL_VAL_ 1537 NotUsedBytes CCS 1-2;
SG_MUL_VAL_ 1537 SizeIndicator CCS 1-2;
SG_MUL_VAL_ 1420 supported_drive_modes_6502 SubIndex_6502 0-0;
SG_MUL_VAL_ 1420 SubIndex_6502 Index 25858-25858;
SG_MUL_VAL_ 1420 motor_service_period_6407 SubIndex_6407 0-0;
SG_MUL_VAL_ 1420 SubIndex_6407 Index 25607-25607;
SG_MUL_VAL_ 1420 motor_type_6402 SubIndex_6402 0-0;
SG_MUL_VAL_ 1420 SubIndex_6402 Index 25602-25602;
SG_MUL_VAL_ 1420 target_velocity_60FF SubIndex_60FF 0-0;
SG_MUL_VAL_ 1420 SubIndex_60FF Index 24831-24831;
SG_MUL_VAL_ 1420 bitmask_60FE_02 SubIndex_60FE 2-2;
SG_MUL_VAL_ 1420 physical_outputs_60FE_01 SubIndex_60FE 1-1;
SG_MUL_VAL_ 1420 digital_outputs_highest_subindex SubIndex_60FE 0-0;
SG_MUL_VAL_ 1420 SubIndex_60FE Index 24830-24830;
SG_MUL_VAL_ 1420 digital_inputs_60FD SubIndex_60FD 0-0;
SG_MUL_VAL_ 1420 SubIndex_60FD Index 24829-24829;
SG_MUL_VAL_ 1420 polarity_607E SubIndex_607E 0-0;
SG_MUL_VAL_ 1420 SubIndex_607E Index 24702-24702;
SG_MUL_VAL_ 1420 target_position_607A SubIndex_607A 0-0;
SG_MUL_VAL_ 1420 SubIndex_607A Index 24698-24698;
SG_MUL_VAL_ 1420 torque_actual_value_6077 SubIndex_6077 0-0;
SG_MUL_VAL_ 1420 SubIndex_6077 Index 24695-24695;
SG_MUL_VAL_ 1420 target_torque_6071 SubIndex_6071 0-0;
SG_MUL_VAL_ 1420 SubIndex_6071 Index 24689-24689;
SG_MUL_VAL_ 1420 velocity_actual_value_606C SubIndex_606C 0-0;
SG_MUL_VAL_ 1420 SubIndex_606C Index 24684-24684;
SG_MUL_VAL_ 1420 position_window_6067 SubIndex_6067 0-0;
SG_MUL_VAL_ 1420 SubIndex_6067 Index 24679-24679;
SG_MUL_VAL_ 1420 position_actual_value_6064 SubIndex_6064 0-0;
SG_MUL_VAL_ 1420 SubIndex_6064 Index 24676-24676;
SG_MUL_VAL_ 1420 position_actual_internal_value_6 SubIndex_6063 0-0;
SG_MUL_VAL_ 1420 SubIndex_6063 Index 24675-24675;
SG_MUL_VAL_ 1420 position_demand_value_6062 SubIndex_6062 0-0;
SG_MUL_VAL_ 1420 SubIndex_6062 Index 24674-24674;
SG_MUL_VAL_ 1420 modes_of_operation_display_6061 SubIndex_6061 0-0;
SG_MUL_VAL_ 1420 SubIndex_6061 Index 24673-24673;
SG_MUL_VAL_ 1420 modes_of_operation_6060 SubIndex_6060 0-0;
SG_MUL_VAL_ 1420 SubIndex_6060 Index 24672-24672;
SG_MUL_VAL_ 1420 fault_reaction_option_code_605E SubIndex_605E 0-0;
SG_MUL_VAL_ 1420 SubIndex_605E Index 24670-24670;
SG_MUL_VAL_ 1420 stop_option_code_605D SubIndex_605D 0-0;
SG_MUL_VAL_ 1420 SubIndex_605D Index 24669-24669;
SG_MUL_VAL_ 1420 disable_operation_option_code_60 SubIndex_605C 0-0;
SG_MUL_VAL_ 1420 SubIndex_605C Index 24668-24668;
SG_MUL_VAL_ 1420 shutdown_option_code_605B SubIndex_605B 0-0;
SG_MUL_VAL_ 1420 SubIndex_605B Index 24667-24667;
SG_MUL_VAL_ 1420 quick_stop_option_code_605A SubIndex_605A 0-0;
SG_MUL_VAL_ 1420 SubIndex_605A Index 24666-24666;
SG_MUL_VAL_ 1420 delta_time_6049_02 SubIndex_6049 2-2;
SG_MUL_VAL_ 1420 delta_speed_6049_01 SubIndex_6049 1-1;
SG_MUL_VAL_ 1420 NrOfObjects_6049_00 SubIndex_6049 0-0;
SG_MUL_VAL_ 1420 SubIndex_6049 Index 24649-24649;
SG_MUL_VAL_ 1420 delta_time_6048_02 SubIndex_6048 2-2;
SG_MUL_VAL_ 1420 delta_speed_6048_01 SubIndex_6048 1-1;
SG_MUL_VAL_ 1420 NrOfObjects_6048_00 SubIndex_6048 0-0;
SG_MUL_VAL_ 1420 SubIndex_6048 Index 24648-24648;
SG_MUL_VAL_ 1420 vl_velocity_max_amount_6046_02 SubIndex_6046 2-2;
SG_MUL_VAL_ 1420 vl_velocity_min_amount_6046_01 SubIndex_6046 1-1;
SG_MUL_VAL_ 1420 vl_velocity_min_max_amount_highe SubIndex_6046 0-0;
SG_MUL_VAL_ 1420 SubIndex_6046 Index 24646-24646;
SG_MUL_VAL_ 1420 vl_control_effort_6044 SubIndex_6044 0-0;
SG_MUL_VAL_ 1420 SubIndex_6044 Index 24644-24644;
SG_MUL_VAL_ 1420 vl_velocity_demand_6043 SubIndex_6043 0-0;
SG_MUL_VAL_ 1420 SubIndex_6043 Index 24643-24643;
SG_MUL_VAL_ 1420 vl_target_velocity_6042 SubIndex_6042 0-0;
SG_MUL_VAL_ 1420 SubIndex_6042 Index 24642-24642;
SG_MUL_VAL_ 1420 statusword_6041 SubIndex_6041 0-0;
SG_MUL_VAL_ 1420 SubIndex_6041 Index 24641-24641;
SG_MUL_VAL_ 1420 controlword_6040 SubIndex_6040 0-0;
SG_MUL_VAL_ 1420 SubIndex_6040 Index 24640-24640;
SG_MUL_VAL_ 1420 error_code_603F SubIndex_603F 0-0;
SG_MUL_VAL_ 1420 SubIndex_603F Index 24639-24639;
SG_MUL_VAL_ 1420 abort_connection_option_code_600 SubIndex_6007 0-0;
SG_MUL_VAL_ 1420 SubIndex_6007 Index 24583-24583;
SG_MUL_VAL_ 1420 PDO_Mapping_Entry_1A06_02 SubIndex_1A06 2-2;
SG_MUL_VAL_ 1420 PDO_Mapping_Entry_1A06_01 SubIndex_1A06 1-1;
SG_MUL_VAL_ 1420 NrOfMappedObjects_1A06_00 SubIndex_1A06 0-0;
SG_MUL_VAL_ 1420 SubIndex_1A06 Index 6662-6662;
SG_MUL_VAL_ 1420 PDO_Mapping_Entry_1A05_02 SubIndex_1A05 2-2;
SG_MUL_VAL_ 1420 PDO_Mapping_Entry_1A05_01 SubIndex_1A05 1-1;
SG_MUL_VAL_ 1420 NrOfMappedObjects_1A05_00 SubIndex_1A05 0-0;
SG_MUL_VAL_ 1420 SubIndex_1A05 Index 6661-6661;
SG_MUL_VAL_ 1420 PDO_Mapping_Entry_1A04_02 SubIndex_1A04 2-2;
SG_MUL_VAL_ 1420 PDO_Mapping_Entry_1A04_01 SubIndex_1A04 1-1;
SG_MUL_VAL_ 1420 NrOfMappedObjects_1A04_00 SubIndex_1A04 0-0;
SG_MUL_VAL_ 1420 SubIndex_1A04 Index 6660-6660;
SG_MUL_VAL_ 1420 PDO_Mapping_Entry_1A03_02 SubIndex_1A03 2-2;
SG_MUL_VAL_ 1420 PDO_Mapping_Entry_1A03_01 SubIndex_1A03 1-1;
SG_MUL_VAL_ 1420 NrOfMappedObjects_1A03_00 SubIndex_1A03 0-0;
SG_MUL_VAL_ 1420 SubIndex_1A03 Index 6659-6659;
SG_MUL_VAL_ 1420 mappedObj2_1A02_02 SubIndex_1A02 2-2;
SG_MUL_VAL_ 1420 mappedObj1_1A02_01 SubIndex_1A02 1-1;
SG_MUL_VAL_ 1420 NrOfMappedObjects_1A02_00 SubIndex_1A02 0-0;
SG_MUL_VAL_ 1420 SubIndex_1A02 Index 6658-6658;
SG_MUL_VAL_ 1420 mappedObj2_1A01_02 SubIndex_1A01 2-2;
SG_MUL_VAL_ 1420 mappedObj1_1A01_01 SubIndex_1A01 1-1;
SG_MUL_VAL_ 1420 NrOfMappedObjects_1A01_00 SubIndex_1A01 0-0;
SG_MUL_VAL_ 1420 SubIndex_1A01 Index 6657-6657;
SG_MUL_VAL_ 1420 mappedObj1_1A00_01 SubIndex_1A00 1-1;
SG_MUL_VAL_ 1420 NrOfMappedObjects_1A00_00 SubIndex_1A00 0-0;
SG_MUL_VAL_ 1420 SubIndex_1A00 Index 6656-6656;
SG_MUL_VAL_ 1420 EventTimer_1806_05 SubIndex_1806 5-5;
SG_MUL_VAL_ 1420 TransmissionType_1806_02 SubIndex_1806 2-2;
SG_MUL_VAL_ 1420 COB_ID_1806_01 SubIndex_1806 1-1;
SG_MUL_VAL_ 1420 Highest_sub_index_supported_1806 SubIndex_1806 0-0;
SG_MUL_VAL_ 1420 SubIndex_1806 Index 6150-6150;
SG_MUL_VAL_ 1420 EventTimer_1805_05 SubIndex_1805 5-5;
SG_MUL_VAL_ 1420 TransmissionType_1805_02 SubIndex_1805 2-2;
SG_MUL_VAL_ 1420 COB_ID_1805_01 SubIndex_1805 1-1;
SG_MUL_VAL_ 1420 Highest_sub_index_supported_1805 SubIndex_1805 0-0;
SG_MUL_VAL_ 1420 SubIndex_1805 Index 6149-6149;
SG_MUL_VAL_ 1420 EventTimer_1804_05 SubIndex_1804 5-5;
SG_MUL_VAL_ 1420 TransmissionType_1804_02 SubIndex_1804 2-2;
SG_MUL_VAL_ 1420 COB_ID_1804_01 SubIndex_1804 1-1;
SG_MUL_VAL_ 1420 Highest_sub_index_supported_0027 SubIndex_1804 0-0;
SG_MUL_VAL_ 1420 SubIndex_1804 Index 6148-6148;
SG_MUL_VAL_ 1420 EventTimer_1803_05 SubIndex_1803 5-5;
SG_MUL_VAL_ 1420 TransmissionType_1803_02 SubIndex_1803 2-2;
SG_MUL_VAL_ 1420 COB_ID_1803_01 SubIndex_1803 1-1;
SG_MUL_VAL_ 1420 Highest_sub_index_supported_0028 SubIndex_1803 0-0;
SG_MUL_VAL_ 1420 SubIndex_1803 Index 6147-6147;
SG_MUL_VAL_ 1420 EventTimer_1802_05 SubIndex_1802 5-5;
SG_MUL_VAL_ 1420 TransmissionType_1802_02 SubIndex_1802 2-2;
SG_MUL_VAL_ 1420 COB_ID_1802_01 SubIndex_1802 1-1;
SG_MUL_VAL_ 1420 Highest_sub_index_supported_0029 SubIndex_1802 0-0;
SG_MUL_VAL_ 1420 SubIndex_1802 Index 6146-6146;
SG_MUL_VAL_ 1420 EventTimer_1801_05 SubIndex_1801 5-5;
SG_MUL_VAL_ 1420 TransmissionType_1801_02 SubIndex_1801 2-2;
SG_MUL_VAL_ 1420 COB_ID_1801_01 SubIndex_1801 1-1;
SG_MUL_VAL_ 1420 Highest_sub_index_supported_0030 SubIndex_1801 0-0;
SG_MUL_VAL_ 1420 SubIndex_1801 Index 6145-6145;
SG_MUL_VAL_ 1420 EventTimer_1800_05 SubIndex_1800 5-5;
SG_MUL_VAL_ 1420 TransmissionType_1800_02 SubIndex_1800 2-2;
SG_MUL_VAL_ 1420 COB_ID_1800_01 SubIndex_1800 1-1;
SG_MUL_VAL_ 1420 Highest_sub_index_supported_0031 SubIndex_1800 0-0;
SG_MUL_VAL_ 1420 SubIndex_1800 Index 6144-6144;
SG_MUL_VAL_ 1420 PDO_Mapping_Entry_1607_02 SubIndex_1607 2-2;
SG_MUL_VAL_ 1420 PDO_Mapping_Entry_1607_01 SubIndex_1607 1-1;
SG_MUL_VAL_ 1420 NrOfMappedObjects_1607_00 SubIndex_1607 0-0;
SG_MUL_VAL_ 1420 SubIndex_1607 Index 5639-5639;
SG_MUL_VAL_ 1420 PDO_Mapping_Entry_1606_02 SubIndex_1606 2-2;
SG_MUL_VAL_ 1420 PDO_Mapping_Entry_1606_01 SubIndex_1606 1-1;
SG_MUL_VAL_ 1420 NrOfMappedObjects_1606_00 SubIndex_1606 0-0;
SG_MUL_VAL_ 1420 SubIndex_1606 Index 5638-5638;
SG_MUL_VAL_ 1420 PDO_Mapping_Entry_1605_02 SubIndex_1605 2-2;
SG_MUL_VAL_ 1420 PDO_Mapping_Entry_1605_01 SubIndex_1605 1-1;
SG_MUL_VAL_ 1420 NrOfMappedObjects_1605_00 SubIndex_1605 0-0;
SG_MUL_VAL_ 1420 SubIndex_1605 Index 5637-5637;
SG_MUL_VAL_ 1420 PDO_Mapping_Entry_1604_02 SubIndex_1604 2-2;
SG_MUL_VAL_ 1420 PDO_Mapping_Entry_1604_01 SubIndex_1604 1-1;
SG_MUL_VAL_ 1420 NrOfMappedObjects_1604_00 SubIndex_1604 0-0;
SG_MUL_VAL_ 1420 SubIndex_1604 Index 5636-5636;
SG_MUL_VAL_ 1420 PDO_Mapping_Entry_1603_02 SubIndex_1603 2-2;
SG_MUL_VAL_ 1420 PDO_Mapping_Entry_1603_01 SubIndex_1603 1-1;
SG_MUL_VAL_ 1420 NrOfMappedObjects_1603_00 SubIndex_1603 0-0;
SG_MUL_VAL_ 1420 SubIndex_1603 Index 5635-5635;
SG_MUL_VAL_ 1420 PDO_Mapping_Entry_1602_02 SubIndex_1602 2-2;
SG_MUL_VAL_ 1420 PDO_Mapping_Entry_1602_01 SubIndex_1602 1-1;
SG_MUL_VAL_ 1420 NrOfMappedObjects_1602_00 SubIndex_1602 0-0;
SG_MUL_VAL_ 1420 SubIndex_1602 Index 5634-5634;
SG_MUL_VAL_ 1420 PDO_Mapping_Entry_1601_02 SubIndex_1601 2-2;
SG_MUL_VAL_ 1420 PDO_Mapping_Entry_1601_01 SubIndex_1601 1-1;
SG_MUL_VAL_ 1420 NrOfMappedObjects_1601_00 SubIndex_1601 0-0;
SG_MUL_VAL_ 1420 SubIndex_1601 Index 5633-5633;
SG_MUL_VAL_ 1420 PDO_Mapping_Entry_1600_04 SubIndex_1600 4-4;
SG_MUL_VAL_ 1420 PDO_Mapping_Entry_1600_03 SubIndex_1600 3-3;
SG_MUL_VAL_ 1420 mappedObj2_1600_02 SubIndex_1600 2-2;
SG_MUL_VAL_ 1420 mappedObj1_1600_01 SubIndex_1600 1-1;
SG_MUL_VAL_ 1420 NrOfMappedObjects_1600_00 SubIndex_1600 0-0;
SG_MUL_VAL_ 1420 SubIndex_1600 Index 5632-5632;
SG_MUL_VAL_ 1420 TransmissionType_1407_02 SubIndex_1407 2-2;
SG_MUL_VAL_ 1420 COB_ID_1407_01 SubIndex_1407 1-1;
SG_MUL_VAL_ 1420 Highest_sub_index_supported_1407 SubIndex_1407 0-0;
SG_MUL_VAL_ 1420 SubIndex_1407 Index 5127-5127;
SG_MUL_VAL_ 1420 TransmissionType_1406_02 SubIndex_1406 2-2;
SG_MUL_VAL_ 1420 COB_ID_1406_01 SubIndex_1406 1-1;
SG_MUL_VAL_ 1420 Highest_sub_index_supported_1406 SubIndex_1406 0-0;
SG_MUL_VAL_ 1420 SubIndex_1406 Index 5126-5126;
SG_MUL_VAL_ 1420 TransmissionType_1405_02 SubIndex_1405 2-2;
SG_MUL_VAL_ 1420 COB_ID_1405_01 SubIndex_1405 1-1;
SG_MUL_VAL_ 1420 Highest_sub_index_supported_1405 SubIndex_1405 0-0;
SG_MUL_VAL_ 1420 SubIndex_1405 Index 5125-5125;
SG_MUL_VAL_ 1420 TransmissionType_1404_02 SubIndex_1404 2-2;
SG_MUL_VAL_ 1420 COB_ID_1404_01 SubIndex_1404 1-1;
SG_MUL_VAL_ 1420 Highest_sub_index_supported_0032 SubIndex_1404 0-0;
SG_MUL_VAL_ 1420 SubIndex_1404 Index 5124-5124;
SG_MUL_VAL_ 1420 TransmissionType_1403_02 SubIndex_1403 2-2;
SG_MUL_VAL_ 1420 COB_ID_1403_01 SubIndex_1403 1-1;
SG_MUL_VAL_ 1420 Highest_sub_index_supported_0033 SubIndex_1403 0-0;
SG_MUL_VAL_ 1420 SubIndex_1403 Index 5123-5123;
SG_MUL_VAL_ 1420 TransmissionType_1402_02 SubIndex_1402 2-2;
SG_MUL_VAL_ 1420 COB_ID_1402_01 SubIndex_1402 1-1;
SG_MUL_VAL_ 1420 Highest_sub_index_supported_0034 SubIndex_1402 0-0;
SG_MUL_VAL_ 1420 SubIndex_1402 Index 5122-5122;
SG_MUL_VAL_ 1420 TransmissionType_1401_02 SubIndex_1401 2-2;
SG_MUL_VAL_ 1420 COB_ID_1401_01 SubIndex_1401 1-1;
SG_MUL_VAL_ 1420 Highest_sub_index_supported_0035 SubIndex_1401 0-0;
SG_MUL_VAL_ 1420 SubIndex_1401 Index 5121-5121;
SG_MUL_VAL_ 1420 TransmissionType_1400_02 SubIndex_1400 2-2;
SG_MUL_VAL_ 1420 COB_ID_1400_01 SubIndex_1400 1-1;
SG_MUL_VAL_ 1420 Highest_sub_index_supported_0036 SubIndex_1400 0-0;
SG_MUL_VAL_ 1420 SubIndex_1400 Index 5120-5120;
SG_MUL_VAL_ 1420 Serial_number_1018_04 SubIndex_1018 4-4;
SG_MUL_VAL_ 1420 Revision_number_1018_03 SubIndex_1018 3-3;
SG_MUL_VAL_ 1420 Product_Code_1018_02 SubIndex_1018 2-2;
SG_MUL_VAL_ 1420 Vendor_Id_1018_01 SubIndex_1018 1-1;
SG_MUL_VAL_ 1420 Highest_sub_index_supported_0037 SubIndex_1018 0-0;
SG_MUL_VAL_ 1420 SubIndex_1018 Index 4120-4120;
SG_MUL_VAL_ 1420 Producer_Heartbeat_Time_1017 SubIndex_1017 0-0;
SG_MUL_VAL_ 1420 SubIndex_1017 Index 4119-4119;
SG_MUL_VAL_ 1420 Consumer_Heartbeat_Time_1016_7E SubIndex_1016 126-126;
SG_MUL_VAL_ 1420 Consumer_Heartbeat_Time_1016_7D SubIndex_1016 125-125;
SG_MUL_VAL_ 1420 Consumer_Heartbeat_Time_1016_7C SubIndex_1016 124-124;
SG_MUL_VAL_ 1420 Consumer_Heartbeat_Time_1016_7B SubIndex_1016 123-123;
SG_MUL_VAL_ 1420 Consumer_Heartbeat_Time_1016_7A SubIndex_1016 122-122;
SG_MUL_VAL_ 1420 Consumer_Heartbeat_Time_1016_79 SubIndex_1016 121-121;
SG_MUL_VAL_ 1420 Consumer_Heartbeat_Time_1016_78 SubIndex_1016 120-120;
SG_MUL_VAL_ 1420 Consumer_Heartbeat_Time_1016_77 SubIndex_1016 119-119;
SG_MUL_VAL_ 1420 Consumer_Heartbeat_Time_1016_76 SubIndex_1016 118-118;
SG_MUL_VAL_ 1420 Consumer_Heartbeat_Time_1016_75 SubIndex_1016 117-117;
SG_MUL_VAL_ 1420 Consumer_Heartbeat_Time_1016_74 SubIndex_1016 116-116;
SG_MUL_VAL_ 1420 Consumer_Heartbeat_Time_1016_73 SubIndex_1016 115-115;
SG_MUL_VAL_ 1420 Consumer_Heartbeat_Time_1016_72 SubIndex_1016 114-114;
SG_MUL_VAL_ 1420 Consumer_Heartbeat_Time_1016_71 SubIndex_1016 113-113;
SG_MUL_VAL_ 1420 Consumer_Heartbeat_Time_1016_70 SubIndex_1016 112-112;
SG_MUL_VAL_ 1420 Consumer_Heartbeat_Time_1016_6F SubIndex_1016 111-111;
SG_MUL_VAL_ 1420 Consumer_Heartbeat_Time_1016_6E SubIndex_1016 110-110;
SG_MUL_VAL_ 1420 Consumer_Heartbeat_Time_1016_6D SubIndex_1016 109-109;
SG_MUL_VAL_ 1420 Consumer_Heartbeat_Time_1016_6C SubIndex_1016 108-108;
SG_MUL_VAL_ 1420 Consumer_Heartbeat_Time_1016_6B SubIndex_1016 107-107;
SG_MUL_VAL_ 1420 Consumer_Heartbeat_Time_1016_6A SubIndex_1016 106-106;
SG_MUL_VAL_ 1420 Consumer_Heartbeat_Time_1016_69 SubIndex_1016 105-105;
SG_MUL_VAL_ 1420 Consumer_Heartbeat_Time_1016_68 SubIndex_1016 104-104;
SG_MUL_VAL_ 1420 Consumer_Heartbeat_Time_1016_67 SubIndex_1016 103-103;
SG_MUL_VAL_ 1420 Consumer_Heartbeat_Time_1016_66 SubIndex_1016 102-102;
SG_MUL_VAL_ 1420 Consumer_Heartbeat_Time_1016_65 SubIndex_1016 101-101;
SG_MUL_VAL_ 1420 Consumer_Heartbeat_Time_1016_64 SubIndex_1016 100-100;
SG_MUL_VAL_ 1420 Consumer_Heartbeat_Time_1016_63 SubIndex_1016 99-99;
SG_MUL_VAL_ 1420 Consumer_Heartbeat_Time_1016_62 SubIndex_1016 98-98;
SG_MUL_VAL_ 1420 Consumer_Heartbeat_Time_1016_61 SubIndex_1016 97-97;
SG_MUL_VAL_ 1420 Consumer_Heartbeat_Time_1016_60 SubIndex_1016 96-96;
SG_MUL_VAL_ 1420 Consumer_Heartbeat_Time_1016_5F SubIndex_1016 95-95;
SG_MUL_VAL_ 1420 Consumer_Heartbeat_Time_1016_5E SubIndex_1016 94-94;
SG_MUL_VAL_ 1420 Consumer_Heartbeat_Time_1016_5D SubIndex_1016 93-93;
SG_MUL_VAL_ 1420 Consumer_Heartbeat_Time_1016_5C SubIndex_1016 92-92;
SG_MUL_VAL_ 1420 Consumer_Heartbeat_Time_1016_5B SubIndex_1016 91-91;
SG_MUL_VAL_ 1420 Consumer_Heartbeat_Time_1016_5A SubIndex_1016 90-90;
SG_MUL_VAL_ 1420 Consumer_Heartbeat_Time_1016_59 SubIndex_1016 89-89;
SG_MUL_VAL_ 1420 Consumer_Heartbeat_Time_1016_58 SubIndex_1016 88-88;
SG_MUL_VAL_ 1420 Consumer_Heartbeat_Time_1016_57 SubIndex_1016 87-87;
SG_MUL_VAL_ 1420 Consumer_Heartbeat_Time_1016_56 SubIndex_1016 86-86;
SG_MUL_VAL_ 1420 Consumer_Heartbeat_Time_1016_55 SubIndex_1016 85-85;
SG_MUL_VAL_ 1420 Consumer_Heartbeat_Time_1016_54 SubIndex_1016 84-84;
SG_MUL_VAL_ 1420 Consumer_Heartbeat_Time_1016_53 SubIndex_1016 83-83;
SG_MUL_VAL_ 1420 Consumer_Heartbeat_Time_1016_52 SubIndex_1016 82-82;
SG_MUL_VAL_ 1420 Consumer_Heartbeat_Time_1016_51 SubIndex_1016 81-81;
SG_MUL_VAL_ 1420 Consumer_Heartbeat_Time_1016_50 SubIndex_1016 80-80;
SG_MUL_VAL_ 1420 Consumer_Heartbeat_Time_1016_4F SubIndex_1016 79-79;
SG_MUL_VAL_ 1420 Consumer_Heartbeat_Time_1016_4E SubIndex_1016 78-78;
SG_MUL_VAL_ 1420 Consumer_Heartbeat_Time_1016_4D SubIndex_1016 77-77;
SG_MUL_VAL_ 1420 Consumer_Heartbeat_Time_1016_4C SubIndex_1016 76-76;
SG_MUL_VAL_ 1420 Consumer_Heartbeat_Time_1016_4B SubIndex_1016 75-75;
SG_MUL_VAL_ 1420 Consumer_Heartbeat_Time_1016_4A SubIndex_1016 74-74;
SG_MUL_VAL_ 1420 Consumer_Heartbeat_Time_1016_49 SubIndex_1016 73-73;
SG_MUL_VAL_ 1420 Consumer_Heartbeat_Time_1016_48 SubIndex_1016 72-72;
SG_MUL_VAL_ 1420 Consumer_Heartbeat_Time_1016_47 SubIndex_1016 71-71;
SG_MUL_VAL_ 1420 Consumer_Heartbeat_Time_1016_46 SubIndex_1016 70-70;
SG_MUL_VAL_ 1420 Consumer_Heartbeat_Time_1016_45 SubIndex_1016 69-69;
SG_MUL_VAL_ 1420 Consumer_Heartbeat_Time_1016_44 SubIndex_1016 68-68;
SG_MUL_VAL_ 1420 Consumer_Heartbeat_Time_1016_43 SubIndex_1016 67-67;
SG_MUL_VAL_ 1420 Consumer_Heartbeat_Time_1016_42 SubIndex_1016 66-66;
SG_MUL_VAL_ 1420 Consumer_Heartbeat_Time_1016_41 SubIndex_1016 65-65;
SG_MUL_VAL_ 1420 Consumer_Heartbeat_Time_1016_40 SubIndex_1016 64-64;
SG_MUL_VAL_ 1420 Consumer_Heartbeat_Time_1016_3F SubIndex_1016 63-63;
SG_MUL_VAL_ 1420 Consumer_Heartbeat_Time_1016_3E SubIndex_1016 62-62;
SG_MUL_VAL_ 1420 Consumer_Heartbeat_Time_1016_3D SubIndex_1016 61-61;
SG_MUL_VAL_ 1420 Consumer_Heartbeat_Time_1016_3C SubIndex_1016 60-60;
SG_MUL_VAL_ 1420 Consumer_Heartbeat_Time_1016_3B SubIndex_1016 59-59;
SG_MUL_VAL_ 1420 Consumer_Heartbeat_Time_1016_3A SubIndex_1016 58-58;
SG_MUL_VAL_ 1420 Consumer_Heartbeat_Time_1016_39 SubIndex_1016 57-57;
SG_MUL_VAL_ 1420 Consumer_Heartbeat_Time_1016_38 SubIndex_1016 56-56;
SG_MUL_VAL_ 1420 Consumer_Heartbeat_Time_1016_37 SubIndex_1016 55-55;
SG_MUL_VAL_ 1420 Consumer_Heartbeat_Time_1016_36 SubIndex_1016 54-54;
SG_MUL_VAL_ 1420 Consumer_Heartbeat_Time_1016_35 SubIndex_1016 53-53;
SG_MUL_VAL_ 1420 Consumer_Heartbeat_Time_1016_34 SubIndex_1016 52-52;
SG_MUL_VAL_ 1420 Consumer_Heartbeat_Time_1016_33 SubIndex_1016 51-51;
SG_MUL_VAL_ 1420 Consumer_Heartbeat_Time_1016_32 SubIndex_1016 50-50;
SG_MUL_VAL_ 1420 Consumer_Heartbeat_Time_1016_31 SubIndex_1016 49-49;
SG_MUL_VAL_ 1420 Consumer_Heartbeat_Time_1016_30 SubIndex_1016 48-48;
SG_MUL_VAL_ 1420 Consumer_Heartbeat_Time_1016_2F SubIndex_1016 47-47;
SG_MUL_VAL_ 1420 Consumer_Heartbeat_Time_1016_2E SubIndex_1016 46-46;
SG_MUL_VAL_ 1420 Consumer_Heartbeat_Time_1016_2D SubIndex_1016 45-45;
SG_MUL_VAL_ 1420 Consumer_Heartbeat_Time_1016_2C SubIndex_1016 44-44;
SG_MUL_VAL_ 1420 Consumer_Heartbeat_Time_1016_2B SubIndex_1016 43-43;
SG_MUL_VAL_ 1420 Consumer_Heartbeat_Time_1016_2A SubIndex_1016 42-42;
SG_MUL_VAL_ 1420 Consumer_Heartbeat_Time_1016_29 SubIndex_1016 41-41;
SG_MUL_VAL_ 1420 Consumer_Heartbeat_Time_1016_28 SubIndex_1016 40-40;
SG_MUL_VAL_ 1420 Consumer_Heartbeat_Time_1016_27 SubIndex_1016 39-39;
SG_MUL_VAL_ 1420 Consumer_Heartbeat_Time_1016_26 SubIndex_1016 38-38;
SG_MUL_VAL_ 1420 Consumer_Heartbeat_Time_1016_25 SubIndex_1016 37-37;
SG_MUL_VAL_ 1420 Consumer_Heartbeat_Time_1016_24 SubIndex_1016 36-36;
SG_MUL_VAL_ 1420 Consumer_Heartbeat_Time_1016_23 SubIndex_1016 35-35;
SG_MUL_VAL_ 1420 Consumer_Heartbeat_Time_1016_22 SubIndex_1016 34-34;
SG_MUL_VAL_ 1420 Consumer_Heartbeat_Time_1016_21 SubIndex_1016 33-33;
SG_MUL_VAL_ 1420 Consumer_Heartbeat_Time_1016_20 SubIndex_1016 32-32;
SG_MUL_VAL_ 1420 Consumer_Heartbeat_Time_1016_1F SubIndex_1016 31-31;
SG_MUL_VAL_ 1420 Consumer_Heartbeat_Time_1016_1E SubIndex_1016 30-30;
SG_MUL_VAL_ 1420 Consumer_Heartbeat_Time_1016_1D SubIndex_1016 29-29;
SG_MUL_VAL_ 1420 Consumer_Heartbeat_Time_1016_1C SubIndex_1016 28-28;
SG_MUL_VAL_ 1420 Consumer_Heartbeat_Time_1016_1B SubIndex_1016 27-27;
SG_MUL_VAL_ 1420 Consumer_Heartbeat_Time_1016_1A SubIndex_1016 26-26;
SG_MUL_VAL_ 1420 Consumer_Heartbeat_Time_1016_19 SubIndex_1016 25-25;
SG_MUL_VAL_ 1420 Consumer_Heartbeat_Time_1016_18 SubIndex_1016 24-24;
SG_MUL_VAL_ 1420 Consumer_Heartbeat_Time_1016_17 SubIndex_1016 23-23;
SG_MUL_VAL_ 1420 Consumer_Heartbeat_Time_1016_16 SubIndex_1016 22-22;
SG_MUL_VAL_ 1420 Consumer_Heartbeat_Time_1016_15 SubIndex_1016 21-21;
SG_MUL_VAL_ 1420 Consumer_Heartbeat_Time_1016_14 SubIndex_1016 20-20;
SG_MUL_VAL_ 1420 Consumer_Heartbeat_Time_1016_13 SubIndex_1016 19-19;
SG_MUL_VAL_ 1420 Consumer_Heartbeat_Time_1016_12 SubIndex_1016 18-18;
SG_MUL_VAL_ 1420 Consumer_Heartbeat_Time_1016_11 SubIndex_1016 17-17;
SG_MUL_VAL_ 1420 Consumer_Heartbeat_Time_1016_10 SubIndex_1016 16-16;
SG_MUL_VAL_ 1420 Consumer_Heartbeat_Time_1016_0F SubIndex_1016 15-15;
SG_MUL_VAL_ 1420 Consumer_Heartbeat_Time_1016_0E SubIndex_1016 14-14;
SG_MUL_VAL_ 1420 Consumer_Heartbeat_Time_1016_0D SubIndex_1016 13-13;
SG_MUL_VAL_ 1420 Consumer_Heartbeat_Time_1016_0C SubIndex_1016 12-12;
SG_MUL_VAL_ 1420 Consumer_Heartbeat_Time_1016_0B SubIndex_1016 11-11;
SG_MUL_VAL_ 1420 Consumer_Heartbeat_Time_1016_0A SubIndex_1016 10-10;
SG_MUL_VAL_ 1420 Consumer_Heartbeat_Time_1016_09 SubIndex_1016 9-9;
SG_MUL_VAL_ 1420 Consumer_Heartbeat_Time_1016_08 SubIndex_1016 8-8;
SG_MUL_VAL_ 1420 Consumer_Heartbeat_Time_1016_07 SubIndex_1016 7-7;
SG_MUL_VAL_ 1420 Consumer_Heartbeat_Time_1016_06 SubIndex_1016 6-6;
SG_MUL_VAL_ 1420 Consumer_Heartbeat_Time_1016_05 SubIndex_1016 5-5;
SG_MUL_VAL_ 1420 Consumer_Heartbeat_Time_1016_04 SubIndex_1016 4-4;
SG_MUL_VAL_ 1420 Consumer_Heartbeat_Time_1016_03 SubIndex_1016 3-3;
SG_MUL_VAL_ 1420 Consumer_Heartbeat_Time_1016_02 SubIndex_1016 2-2;
SG_MUL_VAL_ 1420 Consumer_Heartbeat_Time_1016_01 SubIndex_1016 1-1;
SG_MUL_VAL_ 1420 NrOfObjects_1016_00 SubIndex_1016 0-0;
SG_MUL_VAL_ 1420 SubIndex_1016 Index 4118-4118;
SG_MUL_VAL_ 1420 Save_all_Parameters_1010_01 SubIndex_1010 1-1;
SG_MUL_VAL_ 1420 Highest_sub_index_supported_0038 SubIndex_1010 0-0;
SG_MUL_VAL_ 1420 SubIndex_1010 Index 4112-4112;
SG_MUL_VAL_ 1420 Life_Time_Factor_100D SubIndex_100D 0-0;
SG_MUL_VAL_ 1420 SubIndex_100D Index 4109-4109;
SG_MUL_VAL_ 1420 Guard_Time_100C SubIndex_100C 0-0;
SG_MUL_VAL_ 1420 SubIndex_100C Index 4108-4108;
SG_MUL_VAL_ 1420 Sync_Window_Length_1007 SubIndex_1007 0-0;
SG_MUL_VAL_ 1420 SubIndex_1007 Index 4103-4103;
SG_MUL_VAL_ 1420 Communication_Cycle_Period_1006 SubIndex_1006 0-0;
SG_MUL_VAL_ 1420 SubIndex_1006 Index 4102-4102;
SG_MUL_VAL_ 1420 COB_ID_SYNC_1005 SubIndex_1005 0-0;
SG_MUL_VAL_ 1420 SubIndex_1005 Index 4101-4101;
SG_MUL_VAL_ 1420 Manufacturer_Status_Registe_0001 SubIndex_1002 0-0;
SG_MUL_VAL_ 1420 SubIndex_1002 Index 4098-4098;
SG_MUL_VAL_ 1420 Error_Register_1001 SubIndex_1001 0-0;
SG_MUL_VAL_ 1420 SubIndex_1001 Index 4097-4097;
SG_MUL_VAL_ 1420 Device_Type_1000 SubIndex_1000 0-0;
SG_MUL_VAL_ 1420 SubIndex_1000 Index 4096-4096;
SG_MUL_VAL_ 1420 Index TransferType 1-1;
SG_MUL_VAL_ 1420 TransferType SCS 1-2;
SG_MUL_VAL_ 1420 NotUsedBytes SCS 1-2;
SG_MUL_VAL_ 1420 SizeIndicator SCS 1-2;
